VERSION "dbc-export 1 2025.20.8"

NS_ :

BS_:

BU_: ADSP APB APP APS APSB BB BMS CC CMP CMPD CP DAS DI DIF DIR DPB EPAS3P EPAS3S EPASTP EPASTS EPBL EPBR ESP EVSE FC GTW HCML HCMR HVP IBST ICR IDB LS OCS1P PARK PCS PM PMF PMR PNCD PTC RADC RCM RCM2 RCM3 RCU SCCM SCM SCS SDCR TAS TCU TPMS TRCM UI UIS UMC USM VC VCFRONT VCLEFT VCRIGHT VCSEC VEH

BO_ 896 PM_alertMatrix2: 8 PM
 SG_ PM_a066_pmfMIA : 1|1@1+ (1,0) [0|1] "" Vector__XXX
 SG_ PM_a067_pmrMIA : 2|1@1+ (1,0) [0|1] "" Vector__XXX
 SG_ PM_a068_brakePedalMonitor : 3|1@1+ (1,0) [0|1] "" Vector__XXX
 SG_ PM_a069_brakeMonitorsUnhealthy : 4|1@1+ (1,0) [0|1] "" Vector__XXX
 SG_ PM_a070_brakeTorqueSplitMonitorT : 5|1@1+ (1,0) [0|1] "" Vector__XXX
 SG_ PM_a071_baseBrakingMonitor : 6|1@1+ (1,0) [0|1] "" Vector__XXX
 SG_ PM_a072_brakeTorqueCommandInterf : 7|1@1+ (1,0) [0|1] "" Vector__XXX
 SG_ PM_a073_canDataBusC : 8|1@1+ (1,0) [0|1] "" Vector__XXX
 SG_ PM_a074_canHardwareBusC : 9|1@1+ (1,0) [0|1] "" Vector__XXX
 SG_ PM_a075_canDataBusD : 10|1@1+ (1,0) [0|1] "" Vector__XXX
 SG_ PM_a076_canHardwareBusD : 11|1@1+ (1,0) [0|1] "" Vector__XXX
 SG_ PM_a077_canDataBusE : 12|1@1+ (1,0) [0|1] "" Vector__XXX
 SG_ PM_a078_canHardwareBusE : 13|1@1+ (1,0) [0|1] "" Vector__XXX
 SG_ PM_a079_rcuMIA : 14|1@1+ (1,0) [0|1] "" Vector__XXX
 SG_ PM_a080_exceptionPrefetchAbort : 15|1@1+ (1,0) [0|1] "" Vector__XXX
 SG_ PM_a081_exceptionDataAbort : 16|1@1+ (1,0) [0|1] "" Vector__XXX
 SG_ PM_a082_exceptionDataAbort2 : 17|1@1+ (1,0) [0|1] "" Vector__XXX
 SG_ PM_a083_ahbWriteError : 18|1@1+ (1,0) [0|1] "" Vector__XXX
 SG_ PM_a084_exceptionMpuFirewall : 19|1@1+ (1,0) [0|1] "" Vector__XXX
 SG_ PM_a085_dpbMIA : 20|1@1+ (1,0) [0|1] "" Vector__XXX
 SG_ PM_a086_exceptionUndefinedInstru : 21|1@1+ (1,0) [0|1] "" Vector__XXX
 SG_ PM_a087_canHardwareBusLIPC : 22|1@1+ (1,0) [0|1] "" Vector__XXX
 SG_ PM_a092_xtalOscillator : 27|1@1+ (1,0) [0|1] "" Vector__XXX
 SG_ PM_a093_accelPedalSupply : 28|1@1+ (1,0) [0|1] "" Vector__XXX
 SG_ PM_a095_ITPMSTimeoutGNSSConverge : 30|1@1+ (1,0) [0|1] "" Vector__XXX
 SG_ PM_a096_ITPMSConvergedGNSSAbsRad : 31|1@1+ (1,0) [0|1] "" Vector__XXX
 SG_ PM_a098_ITPMSTriggerDebug : 33|1@1+ (1,0) [0|1] "" Vector__XXX
 SG_ PM_a099_ITPMSCalibrated : 34|1@1+ (1,0) [0|1] "" Vector__XXX
 SG_ PM_a100_diTraceInfo1 : 35|1@1+ (1,0) [0|1] "" Vector__XXX
 SG_ PM_a110_indirectTPMSSoftWarningF : 45|1@1+ (1,0) [0|1] "" Vector__XXX
 SG_ PM_a111_indirectTPMSSoftWarningF : 46|1@1+ (1,0) [0|1] "" Vector__XXX
 SG_ PM_a112_indirectTPMSSoftWarningR : 47|1@1+ (1,0) [0|1] "" Vector__XXX
 SG_ PM_a113_indirectTPMSSoftWarningR : 48|1@1+ (1,0) [0|1] "" Vector__XXX
 SG_ PM_a114_indirectTPMSHardWarningF : 49|1@1+ (1,0) [0|1] "" Vector__XXX
 SG_ PM_a115_indirectTPMSHardWarningF : 50|1@1+ (1,0) [0|1] "" Vector__XXX
 SG_ PM_a116_indirectTPMSHardWarningR : 51|1@1+ (1,0) [0|1] "" Vector__XXX
 SG_ PM_a117_indirectTPMSHardWarningR : 52|1@1+ (1,0) [0|1] "" Vector__XXX
 SG_ PM_a120_indirectTPMSFaulted : 55|1@1+ (1,0) [0|1] "" Vector__XXX
 SG_ PM_a121_unintendedReset2 : 56|1@1+ (1,0) [0|1] "" Vector__XXX

BO_ 2020 PM_info: 8 PM
 SG_ PM_infoIndex M : 0|8@1+ (1,0) [0|255] "" Vector__XXX
 SG_ PM_buildType m10 : 8|8@1+ (1,0) [0|255] "" Vector__XXX
 SG_ PM_buildConfigurationId m10 : 16|16@1+ (1,0) [0|65535] "" Vector__XXX
 SG_ PM_hardwareId m10 : 32|8@1+ (1,0) [0|252] "" Vector__XXX
 SG_ PM_deviceFused m10 : 40|1@1+ (1,0) [0|1] "" Vector__XXX
 SG_ PM_componentId m10 : 48|16@1+ (1,0) [0|65535] "" Vector__XXX
 SG_ PM_pcbaId m11 : 16|8@1+ (1,0) [0|255] "" Vector__XXX
 SG_ PM_assemblyId m11 : 24|8@1+ (1,0) [0|255] "" Vector__XXX
 SG_ PM_usageId m11 : 32|16@1+ (1,0) [0|65535] "" Vector__XXX
 SG_ PM_subUsageId m11 : 48|16@1+ (1,0) [0|65535] "" Vector__XXX
 SG_ PM_applicationCrc m13 : 32|32@1+ (1,0) [0|4294967295] "" Vector__XXX
 SG_ PM_bootGitHash m18 : 8|56@1+ (1,0) [0|7.20575940379e+16] "" Vector__XXX

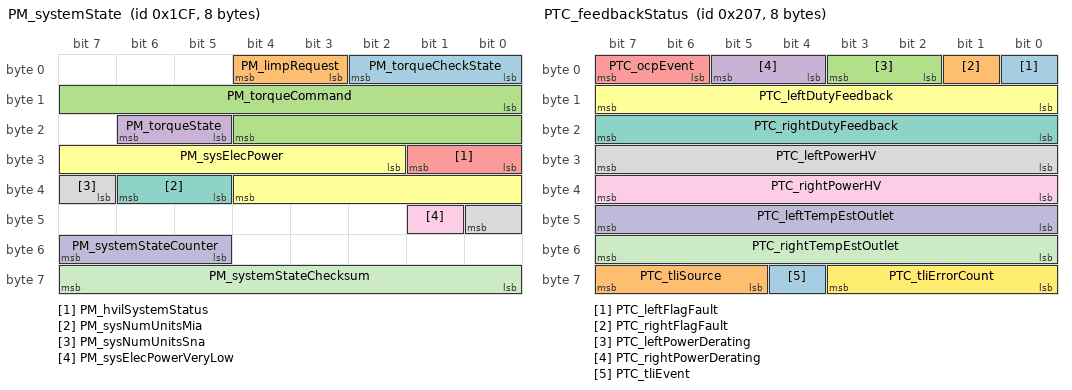
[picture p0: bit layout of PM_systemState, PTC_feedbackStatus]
BO_ 463 PM_systemState: 8 PM
 SG_ PM_torqueCheckState : 0|3@1+ (1,0) [0|7] "" Vector__XXX
 SG_ PM_limpRequest : 3|2@1+ (1,0) [0|3] "" Vector__XXX
 SG_ PM_torqueCommand : 8|13@1- (2,0) [-8192|8190] "Nm" Vector__XXX
 SG_ PM_torqueState : 21|2@1+ (1,0) [0|3] "" Vector__XXX
 SG_ PM_hvilSystemStatus : 24|2@1+ (1,0) [0|2] "" Vector__XXX
 SG_ PM_sysElecPower : 26|11@1- (1,250) [-774|1273] "kW" Vector__XXX
 SG_ PM_sysNumUnitsMia : 37|2@1+ (1,0) [0|3] "" Vector__XXX
 SG_ PM_sysNumUnitsSna : 39|2@1+ (1,0) [0|3] "" Vector__XXX
 SG_ PM_sysElecPowerVeryLow : 41|1@1+ (1,0) [0|1] "" Vector__XXX
 SG_ PM_systemStateCounter : 53|3@1+ (1,0) [0|7] "" Vector__XXX
 SG_ PM_systemStateChecksum : 56|8@1+ (1,0) [0|255] "" Vector__XXX

BO_ 2038 PM_vdcDebug: 8 PM
 SG_ PM_vdcDebugSelector M : 0|6@1+ (1,0) [0|63] "" Vector__XXX
 SG_ PM_VDCA_TCSlipTargetMod_RA_Fwd m5 : 8|6@1- (0.1,0) [-3|3] "m/s" Vector__XXX
 SG_ PM_VDCA_TCSlipTargetMod_RA_Rwd m5 : 16|6@1- (0.1,0) [-3|3] "m/s" Vector__XXX
 SG_ PM_VSE_forceY_RA m5 : 22|9@1- (40,240) [-10000|10440] "N" Vector__XXX
 SG_ PM_VDCT_observerSlipAngle_RA m5 : 31|9@1- (0.005,0.03) [-1.25|1.305] "rad" Vector__XXX
 SG_ PM_VSE_muVehicleFxLow m5 : 40|5@1+ (0.05,0) [0|1.55] "mu" Vector__XXX
 SG_ PM_VE_fxmFres m13 : 8|8@1- (200,0) [-20000|20000] "N" Vector__XXX
 SG_ PM_VE_fxAccelMass m13 : 16|8@1- (0.16,0) [-20|20] "m/s^2" Vector__XXX
 SG_ PM_VE_vxDotGrade m13 : 24|8@1- (0.1,0.8) [-12|13.5] "m/s^2" Vector__XXX
 SG_ PM_VE_betaEst m13 : 32|8@1- (0.01,0) [-1|1] "rad" Vector__XXX
 SG_ PM_VSE_muVehicleFxHigh m13 : 40|5@1+ (0.05,0) [0|1.55] "mu" Vector__XXX
 SG_ PM_VSE_muVehicleDecLeakRate m29 : 6|5@1+ (0.05,0) [0|1.55] "mu" Vector__XXX
 SG_ PM_VSE_muVehicleLearnDown m29 : 11|5@1+ (0.05,0) [0|1.55] "mu" Vector__XXX
 SG_ PM_VSE_muVehicleDecFilter m29 : 16|5@1+ (0.05,0) [0|1.55] "mu" Vector__XXX
 SG_ PM_VSE_muVehicleLatDecLeakRate m29 : 21|5@1+ (0.05,0) [0|1.55] "mu" Vector__XXX
 SG_ PM_VSE_splitMuProbability m29 : 26|5@1+ (0.05,0) [0|1.55] "probability" Vector__XXX
 SG_ PM_VSE_splitMuTotalMz m29 : 31|9@1- (60,360) [-15000|15660] "Nm" Vector__XXX
 SG_ PM_VSE_attitudeBankAngle m29 : 40|9@1- (0.005,0.03) [-1.25|1.305] "rad" Vector__XXX
 SG_ PM_VSE_attitudeDBetaInControl m29 : 49|8@1- (0.01,0.03) [-1.25|1.3] "rad" Vector__XXX
 SG_ PM_VSE_roadWheelAngleAverage m29 : 57|7@1- (0.015,0.255) [-0.7|1.2] "rad" Vector__XXX

BO_ 1766 PNCD_IsoTpPipeToCp: 8 PNCD
 SG_ PNCD_isoTpToCpData : 0|64@1+ (1,0) [0|1.84467440737e+19] "" Vector__XXX

BO_ 519 PTC_feedbackStatus: 8 PTC
 SG_ PTC_leftFlagFault : 0|1@1+ (1,0) [0|1] "" Vector__XXX
 SG_ PTC_rightFlagFault : 1|1@1+ (1,0) [0|1] "" Vector__XXX
 SG_ PTC_leftPowerDerating : 2|2@1+ (1,0) [0|3] "" Vector__XXX
 SG_ PTC_rightPowerDerating : 4|2@1+ (1,0) [0|3] "" Vector__XXX
 SG_ PTC_ocpEvent : 6|2@1+ (1,0) [0|3] "" Vector__XXX
 SG_ PTC_leftDutyFeedback : 8|8@1+ (0.5,0) [0|100] "%" Vector__XXX
 SG_ PTC_rightDutyFeedback : 16|8@1+ (0.5,0) [0|100] "%" Vector__XXX
 SG_ PTC_leftPowerHV : 24|8@1+ (30,0) [0|7650] "W" Vector__XXX
 SG_ PTC_rightPowerHV : 32|8@1+ (30,0) [0|7650] "W" Vector__XXX
 SG_ PTC_leftTempEstOutlet : 40|8@1+ (1,-40) [-40|200] "degC" Vector__XXX
 SG_ PTC_rightTempEstOutlet : 48|8@1+ (1,-40) [-40|200] "degC" Vector__XXX
 SG_ PTC_tliErrorCount : 56|4@1+ (1,0) [0|15] "" Vector__XXX
 SG_ PTC_tliEvent : 60|1@1+ (1,0) [0|1] "" Vector__XXX
 SG_ PTC_tliSource : 61|3@1+ (1,0) [0|7] "" Vector__XXX

BO_ 837 PTC_info: 8 PTC
 SG_ PTC_infoIndex M : 0|8@1+ (1,0) [0|255] "" Vector__XXX
 SG_ PTC_infoBuildType m10 : 8|3@1+ (1,0) [0|7] "" Vector__XXX
 SG_ PTC_infoBuildConfigId m10 : 16|16@1+ (1,0) [0|65535] "" Vector__XXX
 SG_ PTC_infoHardwareId m10 : 32|16@1+ (1,0) [0|65535] "" Vector__XXX
 SG_ PTC_infoComponentId m10 : 48|16@1+ (1,0) [0|65535] "" Vector__XXX
 SG_ PTC_infoPcbaId m11 : 16|8@1+ (1,0) [0|255] "" Vector__XXX
 SG_ PTC_infoAssemblyId m11 : 24|8@1+ (1,0) [0|254] "" Vector__XXX
 SG_ PTC_infoUsageId m11 : 32|16@1+ (1,0) [0|65535] "" Vector__XXX
 SG_ PTC_infoSubUsageId m11 : 48|16@1+ (1,0) [0|65535] "" Vector__XXX
 SG_ PTC_infoPlatformType m13 : 8|8@1+ (1,0) [0|255] "" Vector__XXX
 SG_ PTC_infoAppCrc m13 : 32|32@1+ (1,0) [0|4294967295] "" Vector__XXX
 SG_ PTC_infoBootUdsProtoVersion m20 : 8|8@1+ (1,0) [0|255] "" Vector__XXX
 SG_ PTC_infoBootCrc m20 : 32|32@1+ (1,0) [0|4294967295] "" Vector__XXX

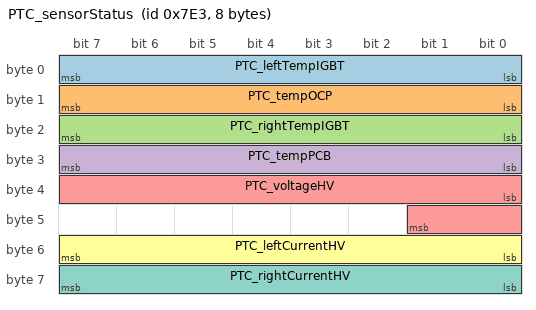
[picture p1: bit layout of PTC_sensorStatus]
BO_ 2019 PTC_sensorStatus: 8 PTC
 SG_ PTC_leftTempIGBT : 0|8@1+ (1,-40) [-40|200] "degC" Vector__XXX
 SG_ PTC_tempOCP : 8|8@1+ (1,-40) [-40|200] "degC" Vector__XXX
 SG_ PTC_rightTempIGBT : 16|8@1+ (1,-40) [-40|200] "degC" Vector__XXX
 SG_ PTC_tempPCB : 24|8@1+ (1,-40) [-40|200] "degC" Vector__XXX
 SG_ PTC_voltageHV : 32|10@1+ (0.5,0) [0|511.5] "V" Vector__XXX
 SG_ PTC_leftCurrentHV : 48|8@1+ (0.2,0) [0|50] "A" Vector__XXX
 SG_ PTC_rightCurrentHV : 56|8@1+ (0.2,0) [0|50] "A" Vector__XXX

BO_ 1365 RADC_alertLog: 8 RADC
 SG_ RADC_alertID M : 0|6@1+ (1,0) [0|63] "" Vector__XXX
 SG_ RADC_alertState : 15|1@1+ (1,0) [0|1] "" Vector__XXX
 SG_ RADC_a002_ecuAdcErrType m2 : 16|8@1+ (1,0) [0|255] "" Vector__XXX
 SG_ RADC_a008_interLockErrType m8 : 16|8@1+ (1,0) [0|255] "" Vector__XXX
 SG_ RADC_a011_ecuMcemErrType m11 : 16|8@1+ (1,0) [0|255] "" Vector__XXX
 SG_ RADC_a013_ecuWdgErrType m13 : 16|8@1+ (1,0) [0|255] "" Vector__XXX
 SG_ RADC_a016_adcOverVoltType m16 : 16|8@1+ (1,0) [0|255] "" Vector__XXX
 SG_ RADC_a016_adcVoltage m16 : 24|6@1+ (0.1,0) [0|6.3] "v" Vector__XXX
 SG_ RADC_a017_adcUnderVoltType m17 : 16|8@1+ (1,0) [0|255] "" Vector__XXX
 SG_ RADC_a017_adcVoltage m17 : 24|6@1+ (0.1,0) [0|6.3] "v" Vector__XXX
 SG_ RADC_a019_internalSWFaultType m19 : 16|8@1+ (1,0) [0|255] "" Vector__XXX
 SG_ RADC_a019_internalSWFaultCoreID m19 : 24|4@1+ (1,0) [0|15] "" Vector__XXX
 SG_ RADC_a020_ecuTemp m20 : 16|16@1+ (0.1,-44) [-44|6509.5] "deg" Vector__XXX
 SG_ RADC_a023_ecuTemp m23 : 16|16@1+ (0.1,-44) [-44|6509.5] "deg" Vector__XXX
 SG_ RADC_a025_ecuVoltage m25 : 16|8@1+ (0.1,0) [0|25.5] "v" Vector__XXX
 SG_ RADC_a026_ecuVoltage m26 : 16|8@1+ (0.1,0) [0|25.5] "v" Vector__XXX
 SG_ RADC_a027_nvmFailureType m27 : 16|8@1+ (1,0) [0|255] "" Vector__XXX
 SG_ RADC_a028_rfComRegCheckFail m28 : 16|8@1+ (1,0) [0|255] "" Vector__XXX
 SG_ RADC_a029_rhcChirpMonErrType m29 : 16|8@1+ (1,0) [0|255] "" Vector__XXX
 SG_ RADC_a029_rhcRxLongTermErrType m29 : 24|8@1+ (1,0) [0|255] "" Vector__XXX
 SG_ RADC_a029_rhcRxErrType m29 : 32|8@1+ (1,0) [0|255] "" Vector__XXX
 SG_ RADC_a029_rhcVcoPowerErrType m29 : 40|8@1+ (1,0) [0|255] "" Vector__XXX
 SG_ RADC_a029_rhcSp1ErrType m29 : 48|8@1+ (1,0) [0|255] "" Vector__XXX
 SG_ RADC_a029_rhcFdcErrType m29 : 56|8@1+ (1,0) [0|255] "" Vector__XXX
 SG_ RADC_a030_rspErrType m30 : 16|8@1+ (1,0) [0|255] "" Vector__XXX
 SG_ RADC_a031_horizMisalignAngle m31 : 16|8@1+ (0.001953125,-0.25) [-0.25|0.248046875] "rad" Vector__XXX
 SG_ RADC_a031_vertMisalignAngle m31 : 24|12@1+ (0.0001220703125,-0.25) [-0.25|0.249877929688] "rad" Vector__XXX
 SG_ RADC_a032_blockageType m32 : 16|8@1+ (1,0) [0|255] "" Vector__XXX
 SG_ RADC_a032_block_SPMBlockageState m32 : 24|3@1+ (1,0) [0|7] "" Vector__XXX
 SG_ RADC_a032_block_dummy m32 : 27|3@1+ (1,0) [0|7] "" Vector__XXX
 SG_ RADC_a032_block_SPMSelfTestState m32 : 30|2@1+ (1,0) [0|3] "" Vector__XXX
 SG_ RADC_a032_block_ucEstiRange m32 : 32|8@1+ (1,0) [0|255] "m" Vector__XXX
 SG_ RADC_a032_block_ucEstiRangeConf m32 : 40|8@1+ (1,0) [0|255] "" Vector__XXX
 SG_ RADC_a032_block_ucEstiRangeProb m32 : 48|8@1+ (1,0) [0|255] "" Vector__XXX
 SG_ RADC_a032_block_ucTimeoutBlkConf m32 : 56|8@1+ (1,0) [0|255] "" Vector__XXX
 SG_ RADC_a035_msgId m35 : 16|12@1+ (1,0) [0|4095] "" Vector__XXX
 SG_ RADC_a036_msgId m36 : 16|12@1+ (1,0) [0|4095] "" Vector__XXX
 SG_ RADC_a037_msgId m37 : 16|12@1+ (1,0) [0|4095] "" Vector__XXX
 SG_ RADC_a038_msgId m38 : 16|12@1+ (1,0) [0|4095] "" Vector__XXX
 SG_ RADC_a039_msgId m39 : 16|12@1+ (1,0) [0|4095] "" Vector__XXX
 SG_ RADC_a040_msgId m40 : 16|12@1+ (1,0) [0|4095] "" Vector__XXX
 SG_ RADC_a041_vinErrType m41 : 16|4@1+ (1,0) [0|15] "" Vector__XXX
 SG_ RADC_a041_vinErrExp m41 : 20|16@1+ (1,0) [0|65535] "" Vector__XXX
 SG_ RADC_a041_vinErrRx m41 : 36|16@1+ (1,0) [0|65535] "" Vector__XXX
 SG_ RADC_a041_msgId m41 : 52|12@1+ (1,0) [0|4095] "" Vector__XXX
 SG_ RADC_a042_carConfigErrType m42 : 16|4@1+ (1,0) [0|15] "" Vector__XXX
 SG_ RADC_a042_carConfigErrExp m42 : 20|16@1+ (1,0) [0|65535] "" Vector__XXX
 SG_ RADC_a042_carConfigErrRx m42 : 36|16@1+ (1,0) [0|65535] "" Vector__XXX
 SG_ RADC_a042_msgId m42 : 52|12@1+ (1,0) [0|4095] "" Vector__XXX
 SG_ RADC_a043_inertialSignalsErrType m43 : 16|4@1+ (1,0) [0|15] "" Vector__XXX
 SG_ RADC_a043_inertialSignalsErrExp m43 : 20|16@1+ (1,0) [0|65535] "" Vector__XXX
 SG_ RADC_a043_inertialSignalsErrRx m43 : 36|16@1+ (1,0) [0|65535] "" Vector__XXX
 SG_ RADC_a043_msgId m43 : 52|12@1+ (1,0) [0|4095] "" Vector__XXX
 SG_ RADC_a044_stwAngleErrType m44 : 16|4@1+ (1,0) [0|15] "" Vector__XXX
 SG_ RADC_a044_stwAngleErrExp m44 : 20|16@1+ (1,0) [0|65535] "" Vector__XXX
 SG_ RADC_a044_stwAngleErrRx m44 : 36|16@1+ (1,0) [0|65535] "" Vector__XXX
 SG_ RADC_a044_msgId m44 : 52|12@1+ (1,0) [0|4095] "" Vector__XXX
 SG_ RADC_a045_vehicleStateErrType m45 : 16|4@1+ (1,0) [0|15] "" Vector__XXX
 SG_ RADC_a045_vehicleStateErrExp m45 : 20|16@1+ (1,0) [0|65535] "" Vector__XXX
 SG_ RADC_a045_vehicleStateErrRx m45 : 36|16@1+ (1,0) [0|65535] "" Vector__XXX
 SG_ RADC_a045_msgId m45 : 52|12@1+ (1,0) [0|4095] "" Vector__XXX
 SG_ RADC_a046_wheelSpeedsErrType m46 : 16|4@1+ (1,0) [0|15] "" Vector__XXX
 SG_ RADC_a046_wheelSpeedsErrExp m46 : 20|16@1+ (1,0) [0|65535] "" Vector__XXX
 SG_ RADC_a046_wheelSpeedsErrRx m46 : 36|16@1+ (1,0) [0|65535] "" Vector__XXX
 SG_ RADC_a046_msgId m46 : 52|12@1+ (1,0) [0|4095] "" Vector__XXX
 SG_ RADC_a047_chassisTypeExp m47 : 16|8@1+ (1,0) [0|255] "" Vector__XXX
 SG_ RADC_a047_chassisTypeRx m47 : 24|8@1+ (1,0) [0|255] "" Vector__XXX
 SG_ RADC_a048_airSuspensionExp m48 : 16|8@1+ (1,0) [0|255] "" Vector__XXX
 SG_ RADC_a048_airSuspensionRx m48 : 24|8@1+ (1,0) [0|255] "" Vector__XXX
 SG_ RADC_a049_fourWheelDriveExp m49 : 16|8@1+ (1,0) [0|255] "" Vector__XXX
 SG_ RADC_a049_fourWheelDriveRx m49 : 24|8@1+ (1,0) [0|255] "" Vector__XXX
 SG_ RADC_a050_countryExp m50 : 16|16@1+ (1,0) [0|65535] "" Vector__XXX
 SG_ RADC_a050_countryRx m50 : 32|16@1+ (1,0) [0|65535] "" Vector__XXX
 SG_ RADC_a051_epasTypeExp m51 : 16|8@1+ (1,0) [0|255] "" Vector__XXX
 SG_ RADC_a051_epasTypeRx m51 : 24|8@1+ (1,0) [0|255] "" Vector__XXX
 SG_ RADC_a052_radarPositionExp m52 : 16|8@1+ (1,0) [0|255] "" Vector__XXX
 SG_ RADC_a052_radarPositionRx m52 : 24|8@1+ (1,0) [0|255] "" Vector__XXX
 SG_ RADC_a054_block_ucObjLossProb m54 : 16|8@1+ (1,0) [0|255] "" Vector__XXX
 SG_ RADC_a054_block_ucObjLossConf m54 : 24|8@1+ (1,0) [0|255] "" Vector__XXX
 SG_ RADC_a054_block_ucOverallProb m54 : 32|8@1+ (1,0) [0|255] "" Vector__XXX
 SG_ RADC_a054_block_ucOverallConf m54 : 40|8@1+ (1,0) [0|255] "" Vector__XXX
 SG_ RADC_a054_block_RoadbeamTimeCnt m54 : 48|16@1+ (1,0) [0|65535] "s" Vector__XXX
 SG_ RADC_a055_block_usTimeoutWayCnt m55 : 16|16@1+ (1,0) [0|65535] "m" Vector__XXX
 SG_ RADC_a055_block_ucTimeoutTimeCnt m55 : 32|8@1+ (1,0) [0|255] "s" Vector__XXX
 SG_ RADC_a055_bblock_ucTimeoutBlkPro m55 : 40|8@1+ (1,0) [0|255] "" Vector__XXX
 SG_ RADC_a055_block_usFullBlkTimer m55 : 48|16@1+ (1,0) [0|65535] "s" Vector__XXX

BO_ 1282 RADC_alertMatrix0: 8 RADC
 SG_ RADC_a001_can1BusOff : 1|1@1+ (1,0) [0|1] "" Vector__XXX
 SG_ RADC_a002_ecuAdcError : 2|1@1+ (1,0) [0|1] "" Vector__XXX
 SG_ RADC_a003_ecuBistDisabled : 3|1@1+ (1,0) [0|1] "" Vector__XXX
 SG_ RADC_a004_ecuCrcHwError : 4|1@1+ (1,0) [0|1] "" Vector__XXX
 SG_ RADC_a005_ecuEcuMError : 5|1@1+ (1,0) [0|1] "" Vector__XXX
 SG_ RADC_a006_ecuFimError : 6|1@1+ (1,0) [0|1] "" Vector__XXX
 SG_ RADC_a007_ecuGptCheckError : 7|1@1+ (1,0) [0|1] "" Vector__XXX
 SG_ RADC_a008_ecuHwSwInterlock : 8|1@1+ (1,0) [0|1] "" Vector__XXX
 SG_ RADC_a009_plantModeActive : 9|1@1+ (1,0) [0|1] "" Vector__XXX
 SG_ RADC_a010_ecuIoHwAbError : 10|1@1+ (1,0) [0|1] "" Vector__XXX
 SG_ RADC_a011_ecuMcemError : 11|1@1+ (1,0) [0|1] "" Vector__XXX
 SG_ RADC_a012_ecuSpiError : 12|1@1+ (1,0) [0|1] "" Vector__XXX
 SG_ RADC_a013_ecuWdgError : 13|1@1+ (1,0) [0|1] "" Vector__XXX
 SG_ RADC_a014_fctSelfTestNotDone : 14|1@1+ (1,0) [0|1] "" Vector__XXX
 SG_ RADC_a015_fctSenInterference : 15|1@1+ (1,0) [0|1] "" Vector__XXX
 SG_ RADC_a016_adcOverVolt : 16|1@1+ (1,0) [0|1] "" Vector__XXX
 SG_ RADC_a017_adcUnderVolt : 17|1@1+ (1,0) [0|1] "" Vector__XXX
 SG_ RADC_a018_internalHardwareFault : 18|1@1+ (1,0) [0|1] "" Vector__XXX
 SG_ RADC_a019_internalSoftwareFault : 19|1@1+ (1,0) [0|1] "" Vector__XXX
 SG_ RADC_a020_overTemp : 20|1@1+ (1,0) [0|1] "" Vector__XXX
 SG_ RADC_a021_overTempCrit : 21|1@1+ (1,0) [0|1] "" Vector__XXX
 SG_ RADC_a022_tempImplausible : 22|1@1+ (1,0) [0|1] "" Vector__XXX
 SG_ RADC_a023_underTemp : 23|1@1+ (1,0) [0|1] "" Vector__XXX
 SG_ RADC_a024_underTempCrit : 24|1@1+ (1,0) [0|1] "" Vector__XXX
 SG_ RADC_a025_overVoltage : 25|1@1+ (1,0) [0|1] "" Vector__XXX
 SG_ RADC_a026_underVoltage : 26|1@1+ (1,0) [0|1] "" Vector__XXX
 SG_ RADC_a027_nvmFailure : 27|1@1+ (1,0) [0|1] "" Vector__XXX
 SG_ RADC_a028_rfChipError : 28|1@1+ (1,0) [0|1] "" Vector__XXX
 SG_ RADC_a029_rhcError : 29|1@1+ (1,0) [0|1] "" Vector__XXX
 SG_ RADC_a030_rspError : 30|1@1+ (1,0) [0|1] "" Vector__XXX
 SG_ RADC_a031_sensorMisaligned : 31|1@1+ (1,0) [0|1] "" Vector__XXX
 SG_ RADC_a032_sensorBlocked : 32|1@1+ (1,0) [0|1] "" Vector__XXX
 SG_ RADC_a033_sensorNeverAligned : 33|1@1+ (1,0) [0|1] "" Vector__XXX
 SG_ RADC_a034_vehDynamicsError : 34|1@1+ (1,0) [0|1] "" Vector__XXX
 SG_ RADC_a035_vinMIA : 35|1@1+ (1,0) [0|1] "" Vector__XXX
 SG_ RADC_a036_carConfigMIA : 36|1@1+ (1,0) [0|1] "" Vector__XXX
 SG_ RADC_a037_inertialSignalsMIA : 37|1@1+ (1,0) [0|1] "" Vector__XXX
 SG_ RADC_a038_steeringWheelAngleMIA : 38|1@1+ (1,0) [0|1] "" Vector__XXX
 SG_ RADC_a039_vehicleStateMIA : 39|1@1+ (1,0) [0|1] "" Vector__XXX
 SG_ RADC_a040_wheelSpeedsMIA : 40|1@1+ (1,0) [0|1] "" Vector__XXX
 SG_ RADC_a041_vinErr : 41|1@1+ (1,0) [0|1] "" Vector__XXX
 SG_ RADC_a042_carConfigErr : 42|1@1+ (1,0) [0|1] "" Vector__XXX
 SG_ RADC_a043_inertialSignalsErr : 43|1@1+ (1,0) [0|1] "" Vector__XXX
 SG_ RADC_a044_steeringWheelAngleErr : 44|1@1+ (1,0) [0|1] "" Vector__XXX
 SG_ RADC_a045_vehicleStateErr : 45|1@1+ (1,0) [0|1] "" Vector__XXX
 SG_ RADC_a046_wheelSpeedsErr : 46|1@1+ (1,0) [0|1] "" Vector__XXX
 SG_ RADC_a047_mismatchChassisType : 47|1@1+ (1,0) [0|1] "" Vector__XXX
 SG_ RADC_a048_mismatchAirSuspension : 48|1@1+ (1,0) [0|1] "" Vector__XXX
 SG_ RADC_a049_mismatchFourWheelDrive : 49|1@1+ (1,0) [0|1] "" Vector__XXX
 SG_ RADC_a050_mismatchCountry : 50|1@1+ (1,0) [0|1] "" Vector__XXX
 SG_ RADC_a051_mismatchEPASType : 51|1@1+ (1,0) [0|1] "" Vector__XXX
 SG_ RADC_a052_mismatcRadPos : 52|1@1+ (1,0) [0|1] "" Vector__XXX
 SG_ RADC_a053_emError : 53|1@1+ (1,0) [0|1] "" Vector__XXX
 SG_ RADC_a054_blockageInfo_Frame_1 : 54|1@1+ (1,0) [0|1] "" Vector__XXX
 SG_ RADC_a055_blockageInfo_Frame_2 : 55|1@1+ (1,0) [0|1] "" Vector__XXX

BO_ 1329 RADC_info: 8 RADC
 SG_ RADC_infoIndex M : 0|8@1+ (1,0) [0|255] "" Vector__XXX
 SG_ RADC_infoBuildType m10 : 8|8@1+ (1,0) [0|255] "" Vector__XXX
 SG_ RADC_infoBuildConfigID m10 : 16|16@1+ (1,0) [0|65535] "" Vector__XXX
 SG_ RADC_infoHardwareID m10 : 32|16@1+ (1,0) [0|65535] "" Vector__XXX
 SG_ RADC_infoComponentID m10 : 48|16@1+ (1,0) [0|65535] "" Vector__XXX
 SG_ RADC_infoPcbaID m11 : 16|8@1+ (1,0) [0|255] "" Vector__XXX
 SG_ RADC_infoAssemblyID m11 : 24|8@1+ (1,0) [0|255] "" Vector__XXX
 SG_ RADC_infoUsageID m11 : 32|16@1+ (1,0) [0|65535] "" Vector__XXX
 SG_ RADC_infoSubUsageID m11 : 48|16@1+ (1,0) [0|65535] "" Vector__XXX
 SG_ RADC_infoApplicationCRC m13 : 32|32@1+ (1,0) [0|4294967295] "" Vector__XXX
 SG_ RADC_infoPlatformType m19 : 8|8@1+ (1,0) [0|255] "" Vector__XXX
 SG_ RADC_infoMajorVersion m19 : 16|8@1+ (1,0) [0|255] "" Vector__XXX
 SG_ RADC_infoBranchOrigin m19 : 24|8@1+ (1,0) [0|255] "" Vector__XXX
 SG_ RADC_infoMaturity m19 : 32|8@1+ (1,0) [0|255] "" Vector__XXX
 SG_ RADC_infoHardwareRevision m19 : 40|8@1+ (1,0) [0|255] "" Vector__XXX
 SG_ RADC_infoBootUdsProtoVersion m20 : 8|8@1+ (1,0) [0|255] "" Vector__XXX
 SG_ RADC_infoBootloaderCRC m20 : 32|32@1+ (1,0) [0|4294967295] "" Vector__XXX

BO_ 1249 RCM2_alertLog: 8 RCM2
 SG_ RCM2_alertID M : 0|10@1+ (1,0) [0|1023] "" Vector__XXX
 SG_ RCM2_alertState : 15|1@1+ (1,0) [0|1] "" Vector__XXX
 SG_ RCM2_eventArmStatus : 25|1@1+ (1,0) [0|1] "" Vector__XXX
 SG_ RCM2_eventFactoryMode : 26|1@1+ (1,0) [0|1] "" Vector__XXX
 SG_ RCM2_eventDriveOrientation : 28|1@1+ (1,0) [0|1] "" Vector__XXX
 SG_ RCM2_eventIDFsignal : 29|1@1+ (1,0) [0|1] "" Vector__XXX
 SG_ RCM2_eventFrontLeftSeatbelt : 30|1@1+ (1,0) [0|1] "" Vector__XXX
 SG_ RCM2_eventFrontRightSeatbelt : 31|1@1+ (1,0) [0|1] "" Vector__XXX
 SG_ RCM2_eventVehicleSpeed : 32|12@1+ (0.08,-40) [-40|287.6] "kph" Vector__XXX
 SG_ RCM2_eventDriverBrakeApply : 44|2@1+ (1,0) [0|2] "" Vector__XXX
 SG_ RCM2_eventAccelPedalPos : 56|8@1+ (0.4,0) [0|101.6] "%" Vector__XXX
 SG_ RCM2_a000_crashDetectedStaticRol m0 : 13|1@1+ (1,0) [0|1] "" Vector__XXX
 SG_ RCM2_a000_crashDetectedPitch m0 : 14|1@1+ (1,0) [0|1] "" Vector__XXX
 SG_ RCM2_a000_crashDetectedFront m0 : 16|1@1+ (1,0) [0|1] "" Vector__XXX
 SG_ RCM2_a000_crashDetectedRear m0 : 17|1@1+ (1,0) [0|1] "" Vector__XXX
 SG_ RCM2_a000_crashDetectedLeft m0 : 18|1@1+ (1,0) [0|1] "" Vector__XXX
 SG_ RCM2_a000_crashDetectedRight m0 : 19|1@1+ (1,0) [0|1] "" Vector__XXX
 SG_ RCM2_a000_crashDetectedRoll m0 : 20|1@1+ (1,0) [0|1] "" Vector__XXX
 SG_ RCM2_a000_crashDetectedPreten m0 : 21|1@1+ (1,0) [0|1] "" Vector__XXX
 SG_ RCM2_a000_crashDetectedStage1 m0 : 22|1@1+ (1,0) [0|1] "" Vector__XXX
 SG_ RCM2_a000_crashDetectedStage2 m0 : 23|1@1+ (1,0) [0|1] "" Vector__XXX
 SG_ RCM2_a000_crashDetectedHVpyro m0 : 24|1@1+ (1,0) [0|1] "" Vector__XXX
 SG_ RCM2_a000_crashDetectedOffZone m0 : 27|1@1+ (1,0) [0|1] "" Vector__XXX
 SG_ RCM2_a001_nearDeployFront m1 : 16|1@1+ (1,0) [0|1] "" Vector__XXX
 SG_ RCM2_a001_nearDeployRear m1 : 17|1@1+ (1,0) [0|1] "" Vector__XXX
 SG_ RCM2_a001_nearDeployLeft m1 : 18|1@1+ (1,0) [0|1] "" Vector__XXX
 SG_ RCM2_a001_nearDeployRight m1 : 19|1@1+ (1,0) [0|1] "" Vector__XXX
 SG_ RCM2_a001_nearDeployRoll m1 : 20|1@1+ (1,0) [0|1] "" Vector__XXX
 SG_ RCM2_a002_airbagsUnArmed_s m2 : 16|1@1+ (1,0) [0|1] "" Vector__XXX
 SG_ RCM2_a003_warningIndicator_s m3 : 16|1@1+ (1,0) [0|1] "" Vector__XXX
 SG_ RCM2_a004_crashAlgoWakeup_s m4 : 16|1@1+ (1,0) [0|1] "" Vector__XXX
 SG_ RCM2_a004_crashAlgoWakeupFront m4 : 17|1@1+ (1,0) [0|1] "" Vector__XXX
 SG_ RCM2_a004_crashAlgoWakeupSide m4 : 18|1@1+ (1,0) [0|1] "" Vector__XXX
 SG_ RCM2_a004_crashAlgoWakeupRear m4 : 19|1@1+ (1,0) [0|1] "" Vector__XXX
 SG_ RCM2_a004_crashAlgoWakeupRoll m4 : 20|1@1+ (1,0) [0|1] "" Vector__XXX
 SG_ RCM2_a004_crashAlgoWakeupPedPro m4 : 21|1@1+ (1,0) [0|1] "" Vector__XXX
 SG_ RCM2_a004_crashAlgoWakeupOffZone m4 : 22|1@1+ (1,0) [0|1] "" Vector__XXX
 SG_ RCM2_a005_abuseImmunityThrshold_ m5 : 16|1@1+ (1,0) [0|1] "" Vector__XXX
 SG_ RCM2_a007_pedProCrashDetected_s m7 : 16|1@1+ (1,0) [0|1] "" Vector__XXX
 SG_ RCM2_a008_factoryMode_s m8 : 16|1@1+ (1,0) [0|1] "" Vector__XXX
 SG_ RCM2_a009_edrDataAreaLocked_s m9 : 16|1@1+ (1,0) [0|1] "" Vector__XXX
 SG_ RCM2_a010_pedProEDRDataLocked_s m10 : 16|1@1+ (1,0) [0|1] "" Vector__XXX
 SG_ RCM2_a014_pedProNearDeploy_s m14 : 16|1@1+ (1,0) [0|1] "" Vector__XXX
 SG_ RCM2_a015_noDeployCrashCal_s m15 : 16|1@1+ (1,0) [0|1] "" Vector__XXX
 SG_ RCM2_a016_noDeployPedProCal_s m16 : 16|1@1+ (1,0) [0|1] "" Vector__XXX
 SG_ RCM2_a047_batteryESRhigh_s m47 : 16|1@1+ (1,0) [0|1] "" Vector__XXX
 SG_ RCM2_a048_batteryVoltageTooHigh_ m48 : 16|1@1+ (1,0) [0|1] "" Vector__XXX
 SG_ RCM2_a049_batteryVoltageTooLow_s m49 : 16|1@1+ (1,0) [0|1] "" Vector__XXX
 SG_ RCM2_a050_driverABStg1Sht2Gnd_s m50 : 16|1@1+ (1,0) [0|1] "" Vector__XXX
 SG_ RCM2_a051_driverABStg1Sht2Bat_s m51 : 16|1@1+ (1,0) [0|1] "" Vector__XXX
 SG_ RCM2_a052_driverABStg1Open_s m52 : 16|1@1+ (1,0) [0|1] "" Vector__XXX
 SG_ RCM2_a053_driverABStg1Short_s m53 : 16|1@1+ (1,0) [0|1] "" Vector__XXX
 SG_ RCM2_a054_driverABStg1CrssCoup_s m54 : 16|1@1+ (1,0) [0|1] "" Vector__XXX
 SG_ RCM2_a055_driverABStg1Config_s m55 : 16|1@1+ (1,0) [0|1] "" Vector__XXX
 SG_ RCM2_a056_driverABStg2Sht2Gnd_s m56 : 16|1@1+ (1,0) [0|1] "" Vector__XXX
 SG_ RCM2_a057_driverABStg2Sht2Bat_s m57 : 16|1@1+ (1,0) [0|1] "" Vector__XXX
 SG_ RCM2_a058_driverABStg2Open_s m58 : 16|1@1+ (1,0) [0|1] "" Vector__XXX
 SG_ RCM2_a059_driverABStg2Short_s m59 : 16|1@1+ (1,0) [0|1] "" Vector__XXX
 SG_ RCM2_a060_driverABStg2CrssCoup_s m60 : 16|1@1+ (1,0) [0|1] "" Vector__XXX
 SG_ RCM2_a061_driverABStg2Config_s m61 : 16|1@1+ (1,0) [0|1] "" Vector__XXX
 SG_ RCM2_a062_passABStg1Sht2Gnd_s m62 : 16|1@1+ (1,0) [0|1] "" Vector__XXX
 SG_ RCM2_a063_passABStg1Sht2Bat_s m63 : 16|1@1+ (1,0) [0|1] "" Vector__XXX
 SG_ RCM2_a064_passABStg1Open_s m64 : 16|1@1+ (1,0) [0|1] "" Vector__XXX
 SG_ RCM2_a065_passABStg1Short_s m65 : 16|1@1+ (1,0) [0|1] "" Vector__XXX
 SG_ RCM2_a066_passABStg1CrssCoup_s m66 : 16|1@1+ (1,0) [0|1] "" Vector__XXX
 SG_ RCM2_a067_passABStg1Config_s m67 : 16|1@1+ (1,0) [0|1] "" Vector__XXX
 SG_ RCM2_a068_passABStg2Sht2Gnd_s m68 : 16|1@1+ (1,0) [0|1] "" Vector__XXX
 SG_ RCM2_a069_passABStg2Sht2Bat_s m69 : 16|1@1+ (1,0) [0|1] "" Vector__XXX
 SG_ RCM2_a070_passABStg2Open_s m70 : 16|1@1+ (1,0) [0|1] "" Vector__XXX
 SG_ RCM2_a071_passABStg2Short_s m71 : 16|1@1+ (1,0) [0|1] "" Vector__XXX
 SG_ RCM2_a072_passABStg2CrssCoup_s m72 : 16|1@1+ (1,0) [0|1] "" Vector__XXX
 SG_ RCM2_a073_passABStg2Config_s m73 : 16|1@1+ (1,0) [0|1] "" Vector__XXX
 SG_ RCM2_a074_passActiveVentSht2Gnd_ m74 : 16|1@1+ (1,0) [0|1] "" Vector__XXX
 SG_ RCM2_a075_passActiveVentSht2Bat_ m75 : 16|1@1+ (1,0) [0|1] "" Vector__XXX
 SG_ RCM2_a076_passActiveVentOpen_s m76 : 16|1@1+ (1,0) [0|1] "" Vector__XXX
 SG_ RCM2_a077_passActiveVentShort_s m77 : 16|1@1+ (1,0) [0|1] "" Vector__XXX
 SG_ RCM2_a078_passActiveVentCrssCoup m78 : 16|1@1+ (1,0) [0|1] "" Vector__XXX
 SG_ RCM2_a079_passActiveVentConfig_s m79 : 16|1@1+ (1,0) [0|1] "" Vector__XXX
 SG_ RCM2_a080_pretenShldLeftSht2Gnd_ m80 : 16|1@1+ (1,0) [0|1] "" Vector__XXX
 SG_ RCM2_a081_pretenShldLeftSht2Bat_ m81 : 16|1@1+ (1,0) [0|1] "" Vector__XXX
 SG_ RCM2_a082_pretenShldLeftOpen_s m82 : 16|1@1+ (1,0) [0|1] "" Vector__XXX
 SG_ RCM2_a083_pretenShldLeftShort_s m83 : 16|1@1+ (1,0) [0|1] "" Vector__XXX
 SG_ RCM2_a084_pretenShldLeftCrossC_s m84 : 16|1@1+ (1,0) [0|1] "" Vector__XXX
 SG_ RCM2_a085_pretenShldLeftConfig_s m85 : 16|1@1+ (1,0) [0|1] "" Vector__XXX
 SG_ RCM2_a086_pretenShldRightSht2Gnd m86 : 16|1@1+ (1,0) [0|1] "" Vector__XXX
 SG_ RCM2_a087_pretenShldRightSht2Bat m87 : 16|1@1+ (1,0) [0|1] "" Vector__XXX
 SG_ RCM2_a088_pretenShldRightOpen_s m88 : 16|1@1+ (1,0) [0|1] "" Vector__XXX
 SG_ RCM2_a089_pretenShldRightShort_s m89 : 16|1@1+ (1,0) [0|1] "" Vector__XXX
 SG_ RCM2_a090_pretenShldRightCrssCou m90 : 16|1@1+ (1,0) [0|1] "" Vector__XXX
 SG_ RCM2_a091_pretenShldRightConfig_ m91 : 16|1@1+ (1,0) [0|1] "" Vector__XXX
 SG_ RCM2_a092_pretenLapLeftSht2Gnd_s m92 : 16|1@1+ (1,0) [0|1] "" Vector__XXX
 SG_ RCM2_a093_pretenLapLeftSht2Bat_s m93 : 16|1@1+ (1,0) [0|1] "" Vector__XXX
 SG_ RCM2_a094_pretenLapLeftOpen_s m94 : 16|1@1+ (1,0) [0|1] "" Vector__XXX
 SG_ RCM2_a095_pretenLapLeftShort_s m95 : 16|1@1+ (1,0) [0|1] "" Vector__XXX
 SG_ RCM2_a096_pretenLapLeftCrssCoup_ m96 : 16|1@1+ (1,0) [0|1] "" Vector__XXX
 SG_ RCM2_a097_pretenLapLeftConfig_s m97 : 16|1@1+ (1,0) [0|1] "" Vector__XXX
 SG_ RCM2_a098_pretenLapRightSht2Gnd_ m98 : 16|1@1+ (1,0) [0|1] "" Vector__XXX
 SG_ RCM2_a099_pretenLapRightSht2Bat_ m99 : 16|1@1+ (1,0) [0|1] "" Vector__XXX
 SG_ RCM2_a100_pretenLapRightOpen_s m100 : 16|1@1+ (1,0) [0|1] "" Vector__XXX
 SG_ RCM2_a101_pretenLapRightShort_s m101 : 16|1@1+ (1,0) [0|1] "" Vector__XXX
 SG_ RCM2_a102_pretenLapRightCrssCoup m102 : 16|1@1+ (1,0) [0|1] "" Vector__XXX
 SG_ RCM2_a103_pretenLapRightConfig_s m103 : 16|1@1+ (1,0) [0|1] "" Vector__XXX
 SG_ RCM2_a104_loadLimLeftSht2Gnd_s m104 : 16|1@1+ (1,0) [0|1] "" Vector__XXX
 SG_ RCM2_a105_loadLimLeftSht2Bat_s m105 : 16|1@1+ (1,0) [0|1] "" Vector__XXX
 SG_ RCM2_a106_loadLimLeftOpen_s m106 : 16|1@1+ (1,0) [0|1] "" Vector__XXX
 SG_ RCM2_a107_loadLimLeftShort_s m107 : 16|1@1+ (1,0) [0|1] "" Vector__XXX
 SG_ RCM2_a108_loadLimLeftCrssCoup_s m108 : 16|1@1+ (1,0) [0|1] "" Vector__XXX
 SG_ RCM2_a110_loadLimRightSht2Gnd_s m110 : 16|1@1+ (1,0) [0|1] "" Vector__XXX
 SG_ RCM2_a111_loadLimRightSht2Bat_s m111 : 16|1@1+ (1,0) [0|1] "" Vector__XXX
 SG_ RCM2_a112_loadLimRightOpen_s m112 : 16|1@1+ (1,0) [0|1] "" Vector__XXX
 SG_ RCM2_a113_loadLimRightShort_s m113 : 16|1@1+ (1,0) [0|1] "" Vector__XXX
 SG_ RCM2_a114_loadLimRightCrssCoup_s m114 : 16|1@1+ (1,0) [0|1] "" Vector__XXX
 SG_ RCM2_a115_loadLimRightConfig_s m115 : 16|1@1+ (1,0) [0|1] "" Vector__XXX
 SG_ RCM2_a116_kneeABDrvrSht2Gnd_s m116 : 16|1@1+ (1,0) [0|1] "" Vector__XXX
 SG_ RCM2_a117_kneeABDrvrSht2Bat_s m117 : 16|1@1+ (1,0) [0|1] "" Vector__XXX
 SG_ RCM2_a118_kneeABDrvrOpen_s m118 : 16|1@1+ (1,0) [0|1] "" Vector__XXX
 SG_ RCM2_a119_kneeABDrvrShort_s m119 : 16|1@1+ (1,0) [0|1] "" Vector__XXX
 SG_ RCM2_a120_kneeABDrvrCrssCoup_s m120 : 16|1@1+ (1,0) [0|1] "" Vector__XXX
 SG_ RCM2_a122_kneeABPassSht2Gnd_s m122 : 16|1@1+ (1,0) [0|1] "" Vector__XXX
 SG_ RCM2_a123_kneeABPassSht2Bat_s m123 : 16|1@1+ (1,0) [0|1] "" Vector__XXX
 SG_ RCM2_a124_kneeABPassOpen_s m124 : 16|1@1+ (1,0) [0|1] "" Vector__XXX
 SG_ RCM2_a125_kneeABPassShort_s m125 : 16|1@1+ (1,0) [0|1] "" Vector__XXX
 SG_ RCM2_a126_kneeABPassCrssCoup_s m126 : 16|1@1+ (1,0) [0|1] "" Vector__XXX
 SG_ RCM2_a127_kneeABPassConfig_s m127 : 16|1@1+ (1,0) [0|1] "" Vector__XXX
 SG_ RCM2_a128_sideAB1stRowLSht2Gnd_s m128 : 16|1@1+ (1,0) [0|1] "" Vector__XXX
 SG_ RCM2_a129_sideAB1stRowLSht2Bat_s m129 : 16|1@1+ (1,0) [0|1] "" Vector__XXX
 SG_ RCM2_a130_sideAB1stRowLOpen_s m130 : 16|1@1+ (1,0) [0|1] "" Vector__XXX
 SG_ RCM2_a131_sideAB1stRowLShort_s m131 : 16|1@1+ (1,0) [0|1] "" Vector__XXX
 SG_ RCM2_a132_sideAB1stRowLCrssCoup_ m132 : 16|1@1+ (1,0) [0|1] "" Vector__XXX
 SG_ RCM2_a134_sideAB1stRowRSht2Gnd_s m134 : 16|1@1+ (1,0) [0|1] "" Vector__XXX
 SG_ RCM2_a135_sideAB1stRowRSht2Bat_s m135 : 16|1@1+ (1,0) [0|1] "" Vector__XXX
 SG_ RCM2_a136_sideAB1stRowROpen_s m136 : 16|1@1+ (1,0) [0|1] "" Vector__XXX
 SG_ RCM2_a137_sideAB1stRowRShort_s m137 : 16|1@1+ (1,0) [0|1] "" Vector__XXX
 SG_ RCM2_a138_sideAB1stRowRCrssCoup_ m138 : 16|1@1+ (1,0) [0|1] "" Vector__XXX
 SG_ RCM2_a140_hvdPyroSht2Gnd_s m140 : 16|1@1+ (1,0) [0|1] "" Vector__XXX
 SG_ RCM2_a141_hvdPyroSht2Bat_s m141 : 16|1@1+ (1,0) [0|1] "" Vector__XXX
 SG_ RCM2_a142_hvdPyroOpen_s m142 : 16|1@1+ (1,0) [0|1] "" Vector__XXX
 SG_ RCM2_a143_hvdPyroShort_s m143 : 16|1@1+ (1,0) [0|1] "" Vector__XXX
 SG_ RCM2_a144_hvdPyroCrssCoup_s m144 : 16|1@1+ (1,0) [0|1] "" Vector__XXX
 SG_ RCM2_a145_hvdPyroConfig_s m145 : 16|1@1+ (1,0) [0|1] "" Vector__XXX
 SG_ RCM2_a146_curABLeftSht2Gnd_s m146 : 16|1@1+ (1,0) [0|1] "" Vector__XXX
 SG_ RCM2_a147_curABLeftSht2Bat_s m147 : 16|1@1+ (1,0) [0|1] "" Vector__XXX
 SG_ RCM2_a148_curABLeftOpen_s m148 : 16|1@1+ (1,0) [0|1] "" Vector__XXX
 SG_ RCM2_a149_curABLeftShort_s m149 : 16|1@1+ (1,0) [0|1] "" Vector__XXX
 SG_ RCM2_a150_curABLeftCrssCoup_s m150 : 16|1@1+ (1,0) [0|1] "" Vector__XXX
 SG_ RCM2_a152_curABRightSht2Gnd_s m152 : 16|1@1+ (1,0) [0|1] "" Vector__XXX
 SG_ RCM2_a153_curABRightSht2Bat_s m153 : 16|1@1+ (1,0) [0|1] "" Vector__XXX
 SG_ RCM2_a154_curABRightOpen_s m154 : 16|1@1+ (1,0) [0|1] "" Vector__XXX
 SG_ RCM2_a155_curABRightShort_s m155 : 16|1@1+ (1,0) [0|1] "" Vector__XXX
 SG_ RCM2_a156_curABRightCrssCoup_s m156 : 16|1@1+ (1,0) [0|1] "" Vector__XXX
 SG_ RCM2_a158_preten2ndRowLSht2Gnd_s m158 : 16|1@1+ (1,0) [0|1] "" Vector__XXX
 SG_ RCM2_a159_preten2ndRowLSht2Bat_s m159 : 16|1@1+ (1,0) [0|1] "" Vector__XXX
 SG_ RCM2_a160_preten2ndRowLOpen_s m160 : 16|1@1+ (1,0) [0|1] "" Vector__XXX
 SG_ RCM2_a161_preten2ndRowLShort_s m161 : 16|1@1+ (1,0) [0|1] "" Vector__XXX
 SG_ RCM2_a162_preten2ndRowLCrssCoup_ m162 : 16|1@1+ (1,0) [0|1] "" Vector__XXX
 SG_ RCM2_a163_preten2ndRowLCgf_s m163 : 16|1@1+ (1,0) [0|1] "" Vector__XXX
 SG_ RCM2_a164_preten2ndRowRSht2Gnd_s m164 : 16|1@1+ (1,0) [0|1] "" Vector__XXX
 SG_ RCM2_a165_preten2ndRowRSht2Bat_s m165 : 16|1@1+ (1,0) [0|1] "" Vector__XXX
 SG_ RCM2_a166_preten2ndRowROpen_s m166 : 16|1@1+ (1,0) [0|1] "" Vector__XXX
 SG_ RCM2_a167_preten2ndRowRShort_s m167 : 16|1@1+ (1,0) [0|1] "" Vector__XXX
 SG_ RCM2_a168_preten2ndRowRCrssCoup_ m168 : 16|1@1+ (1,0) [0|1] "" Vector__XXX
 SG_ RCM2_a169_preten2ndRowRCgf_s m169 : 16|1@1+ (1,0) [0|1] "" Vector__XXX
 SG_ RCM2_a170_curAB2ndRowLSht2Gnd_s m170 : 16|1@1+ (1,0) [0|1] "" Vector__XXX
 SG_ RCM2_a171_curAB2ndRowLSht2Bat_s m171 : 16|1@1+ (1,0) [0|1] "" Vector__XXX
 SG_ RCM2_a172_curAB2ndRowLOpen_s m172 : 16|1@1+ (1,0) [0|1] "" Vector__XXX
 SG_ RCM2_a173_curAB2ndRowLShort_s m173 : 16|1@1+ (1,0) [0|1] "" Vector__XXX
 SG_ RCM2_a174_curAB2ndRowLCrssCoup_s m174 : 16|1@1+ (1,0) [0|1] "" Vector__XXX
 SG_ RCM2_a175_curAB2ndRowLConfig_s m175 : 16|1@1+ (1,0) [0|1] "" Vector__XXX
 SG_ RCM2_a176_curAB2ndRowRSht2Gnd_s m176 : 16|1@1+ (1,0) [0|1] "" Vector__XXX
 SG_ RCM2_a177_curAB2ndRowRSht2Bat_s m177 : 16|1@1+ (1,0) [0|1] "" Vector__XXX
 SG_ RCM2_a178_curAB2ndRowROpen_s m178 : 16|1@1+ (1,0) [0|1] "" Vector__XXX
 SG_ RCM2_a179_curAB2ndRowRShort_s m179 : 16|1@1+ (1,0) [0|1] "" Vector__XXX
 SG_ RCM2_a180_curAB2ndRowRCrssCoup_s m180 : 16|1@1+ (1,0) [0|1] "" Vector__XXX
 SG_ RCM2_a181_curAB2ndRowRConfig_s m181 : 16|1@1+ (1,0) [0|1] "" Vector__XXX
 SG_ RCM2_a182_hoodActuatorRSht2Gnd_s m182 : 16|1@1+ (1,0) [0|1] "" Vector__XXX
 SG_ RCM2_a183_hoodActuatorRSht2Bat_s m183 : 16|1@1+ (1,0) [0|1] "" Vector__XXX
 SG_ RCM2_a184_hoodActuatorROpen_s m184 : 16|1@1+ (1,0) [0|1] "" Vector__XXX
 SG_ RCM2_a185_hoodActuatorRShort_s m185 : 16|1@1+ (1,0) [0|1] "" Vector__XXX
 SG_ RCM2_a186_hoodActuatorRCrssCoup_ m186 : 16|1@1+ (1,0) [0|1] "" Vector__XXX
 SG_ RCM2_a187_hoodActuatorRConfig_s m187 : 16|1@1+ (1,0) [0|1] "" Vector__XXX
 SG_ RCM2_a188_hoodActuatorLSht2Gnd_s m188 : 16|1@1+ (1,0) [0|1] "" Vector__XXX
 SG_ RCM2_a189_hoodActuatorLSht2Bat_s m189 : 16|1@1+ (1,0) [0|1] "" Vector__XXX
 SG_ RCM2_a190_hoodActuatorLOpen_s m190 : 16|1@1+ (1,0) [0|1] "" Vector__XXX
 SG_ RCM2_a191_hoodActuatorLShort_s m191 : 16|1@1+ (1,0) [0|1] "" Vector__XXX
 SG_ RCM2_a192_hoodActuatorLCrssCoup_ m192 : 16|1@1+ (1,0) [0|1] "" Vector__XXX
 SG_ RCM2_a193_hoodActuatorLConfig_s m193 : 16|1@1+ (1,0) [0|1] "" Vector__XXX
 SG_ RCM2_a194_driverABAVSht2Gnd_s m194 : 16|1@1+ (1,0) [0|1] "" Vector__XXX
 SG_ RCM2_a195_driverABAVSht2Bat_s m195 : 16|1@1+ (1,0) [0|1] "" Vector__XXX
 SG_ RCM2_a196_driverABAVOpen_s m196 : 16|1@1+ (1,0) [0|1] "" Vector__XXX
 SG_ RCM2_a197_driverABAVShort_s m197 : 16|1@1+ (1,0) [0|1] "" Vector__XXX
 SG_ RCM2_a198_driverABAVCrossCoup_s m198 : 16|1@1+ (1,0) [0|1] "" Vector__XXX
 SG_ RCM2_a199_driverABAVConfig_s m199 : 16|1@1+ (1,0) [0|1] "" Vector__XXX
 SG_ RCM2_a200_driverFSABSht2Gnd_s m200 : 16|1@1+ (1,0) [0|1] "" Vector__XXX
 SG_ RCM2_a201_driverFSABSht2Bat_s m201 : 16|1@1+ (1,0) [0|1] "" Vector__XXX
 SG_ RCM2_a202_driverFSABOpen_s m202 : 16|1@1+ (1,0) [0|1] "" Vector__XXX
 SG_ RCM2_a203_driverFSABShort_s m203 : 16|1@1+ (1,0) [0|1] "" Vector__XXX
 SG_ RCM2_a204_driverFSABCrossCoup_s m204 : 16|1@1+ (1,0) [0|1] "" Vector__XXX
 SG_ RCM2_a205_driverFSABConfig_s m205 : 16|1@1+ (1,0) [0|1] "" Vector__XXX
 SG_ RCM2_a206_sideAB2ndRowLSht2Gnd_s m206 : 16|1@1+ (1,0) [0|1] "" Vector__XXX
 SG_ RCM2_a207_sideAB2ndRowLSht2Bat_s m207 : 16|1@1+ (1,0) [0|1] "" Vector__XXX
 SG_ RCM2_a208_sideAB2ndRowLOpen_s m208 : 16|1@1+ (1,0) [0|1] "" Vector__XXX
 SG_ RCM2_a209_sideAB2ndRowLShort_s m209 : 16|1@1+ (1,0) [0|1] "" Vector__XXX
 SG_ RCM2_a210_sideAB2ndRowLCrssCoup_ m210 : 16|1@1+ (1,0) [0|1] "" Vector__XXX
 SG_ RCM2_a211_sideAB2ndRowLConfig_s m211 : 16|1@1+ (1,0) [0|1] "" Vector__XXX
 SG_ RCM2_a212_sideAB2ndRowRSht2Gnd_s m212 : 16|1@1+ (1,0) [0|1] "" Vector__XXX
 SG_ RCM2_a213_sideAB2ndRowRSht2Bat_s m213 : 16|1@1+ (1,0) [0|1] "" Vector__XXX
 SG_ RCM2_a214_sideAB2ndRowROpen_s m214 : 16|1@1+ (1,0) [0|1] "" Vector__XXX
 SG_ RCM2_a215_sideAB2ndRowRShort_s m215 : 16|1@1+ (1,0) [0|1] "" Vector__XXX
 SG_ RCM2_a216_sideAB2ndRowRCrssCoup_ m216 : 16|1@1+ (1,0) [0|1] "" Vector__XXX
 SG_ RCM2_a217_sideAB2ndRowRConfig_s m217 : 16|1@1+ (1,0) [0|1] "" Vector__XXX
 SG_ RCM2_a250_ens1Sht2Bat_s m250 : 16|1@1+ (1,0) [0|1] "" Vector__XXX
 SG_ RCM2_a251_ens1Sht2Gnd_s m251 : 16|1@1+ (1,0) [0|1] "" Vector__XXX
 SG_ RCM2_a252_ens1Config_s m252 : 16|1@1+ (1,0) [0|1] "" Vector__XXX
 SG_ RCM2_a253_ens2Sht2Bat_s m253 : 16|1@1+ (1,0) [0|1] "" Vector__XXX
 SG_ RCM2_a254_ens2Sht2Gnd_s m254 : 16|1@1+ (1,0) [0|1] "" Vector__XXX
 SG_ RCM2_a256_ens3Sht2Bat_s m256 : 16|1@1+ (1,0) [0|1] "" Vector__XXX
 SG_ RCM2_a257_ens3Sht2Gnd_s m257 : 16|1@1+ (1,0) [0|1] "" Vector__XXX
 SG_ RCM2_a258_ens3Config_s m258 : 16|1@1+ (1,0) [0|1] "" Vector__XXX
 SG_ RCM2_a259_ens4Sht2Bat_s m259 : 16|1@1+ (1,0) [0|1] "" Vector__XXX
 SG_ RCM2_a260_ens4Sht2Gnd_s m260 : 16|1@1+ (1,0) [0|1] "" Vector__XXX
 SG_ RCM2_a261_ens4Config_s m261 : 16|1@1+ (1,0) [0|1] "" Vector__XXX
 SG_ RCM2_a264_imuYawR8OffCompPosLife m264 : 16|1@1+ (1,0) [0|1] "" Vector__XXX
 SG_ RCM2_a265_imuYawR8OffCompNegLife m265 : 16|1@1+ (1,0) [0|1] "" Vector__XXX
 SG_ RCM2_a266_imuYawR8OffCompPosFLDC m266 : 16|1@1+ (1,0) [0|1] "" Vector__XXX
 SG_ RCM2_a267_imuYawR8OffCompNegFLDC m267 : 16|1@1+ (1,0) [0|1] "" Vector__XXX
 SG_ RCM2_a268_imuYawR8OffCompPosSLDC m268 : 16|1@1+ (1,0) [0|1] "" Vector__XXX
 SG_ RCM2_a269_imuYawR8OffCompNegSLDC m269 : 16|1@1+ (1,0) [0|1] "" Vector__XXX
 SG_ RCM2_a270_imuPtchR8OffCompPosLif m270 : 16|1@1+ (1,0) [0|1] "" Vector__XXX
 SG_ RCM2_a271_imuPtchR8OffCompNegLif m271 : 16|1@1+ (1,0) [0|1] "" Vector__XXX
 SG_ RCM2_a272_imuPtchR8OffCompPosFLD m272 : 16|1@1+ (1,0) [0|1] "" Vector__XXX
 SG_ RCM2_a273_imuPtchR8OffCompNegFLD m273 : 16|1@1+ (1,0) [0|1] "" Vector__XXX
 SG_ RCM2_a274_imuPtchR8OffCompPosSLD m274 : 16|1@1+ (1,0) [0|1] "" Vector__XXX
 SG_ RCM2_a275_imuPtchR8OffCompNegSLD m275 : 16|1@1+ (1,0) [0|1] "" Vector__XXX
 SG_ RCM2_a276_imuRollR8OffCompPosLif m276 : 16|1@1+ (1,0) [0|1] "" Vector__XXX
 SG_ RCM2_a277_imuRollR8OffCompNegLif m277 : 16|1@1+ (1,0) [0|1] "" Vector__XXX
 SG_ RCM2_a278_imuRollR8OffCompPosFLD m278 : 16|1@1+ (1,0) [0|1] "" Vector__XXX
 SG_ RCM2_a279_imuRollR8OffCompNegFLD m279 : 16|1@1+ (1,0) [0|1] "" Vector__XXX
 SG_ RCM2_a280_imuRollR8OffCompPosSLD m280 : 16|1@1+ (1,0) [0|1] "" Vector__XXX
 SG_ RCM2_a281_imuRollR8OffCompNegSLD m281 : 16|1@1+ (1,0) [0|1] "" Vector__XXX
 SG_ RCM2_a282_imuLongAOffCompPosLife m282 : 16|1@1+ (1,0) [0|1] "" Vector__XXX
 SG_ RCM2_a283_imuLongAOffCompNegLife m283 : 16|1@1+ (1,0) [0|1] "" Vector__XXX
 SG_ RCM2_a284_imuLongAOffCompPosFLDC m284 : 16|1@1+ (1,0) [0|1] "" Vector__XXX
 SG_ RCM2_a285_imuLongAOffCompNegFLDC m285 : 16|1@1+ (1,0) [0|1] "" Vector__XXX
 SG_ RCM2_a286_imuLongAOffCompPosSLDC m286 : 16|1@1+ (1,0) [0|1] "" Vector__XXX
 SG_ RCM2_a287_imuLongAOffCompNegSLDC m287 : 16|1@1+ (1,0) [0|1] "" Vector__XXX
 SG_ RCM2_a288_imuLatAcOffCompPosLife m288 : 16|1@1+ (1,0) [0|1] "" Vector__XXX
 SG_ RCM2_a289_imuLatAcOffCompNegLife m289 : 16|1@1+ (1,0) [0|1] "" Vector__XXX
 SG_ RCM2_a290_imuLatAcOffCompPosFLDC m290 : 16|1@1+ (1,0) [0|1] "" Vector__XXX
 SG_ RCM2_a291_imuLatAcOffCompNegFLDC m291 : 16|1@1+ (1,0) [0|1] "" Vector__XXX
 SG_ RCM2_a292_imuLatAcOffCompPosSLDC m292 : 16|1@1+ (1,0) [0|1] "" Vector__XXX
 SG_ RCM2_a293_imuLatAcOffCompNegSLDC m293 : 16|1@1+ (1,0) [0|1] "" Vector__XXX
 SG_ RCM2_a294_imuVertAOffCompPosLife m294 : 16|1@1+ (1,0) [0|1] "" Vector__XXX
 SG_ RCM2_a295_imuVertAOffCompNegLife m295 : 16|1@1+ (1,0) [0|1] "" Vector__XXX
 SG_ RCM2_a296_imuVertAOffCompPosFLDC m296 : 16|1@1+ (1,0) [0|1] "" Vector__XXX
 SG_ RCM2_a297_imuVertAOffCompNegFLDC m297 : 16|1@1+ (1,0) [0|1] "" Vector__XXX
 SG_ RCM2_a298_imuVertAOffCompPosSLDC m298 : 16|1@1+ (1,0) [0|1] "" Vector__XXX
 SG_ RCM2_a299_imuVertAOffCompNegSLDC m299 : 16|1@1+ (1,0) [0|1] "" Vector__XXX
 SG_ RCM2_a300_imuAccXHgMonChlPerm_s m300 : 16|1@1+ (1,0) [0|1] "" Vector__XXX
 SG_ RCM2_a301_imuAccXHgMonChlTemp_s m301 : 16|1@1+ (1,0) [0|1] "" Vector__XXX
 SG_ RCM2_a302_imuAccYHgMonChlPerm_s m302 : 16|1@1+ (1,0) [0|1] "" Vector__XXX
 SG_ RCM2_a303_imuAccYHgMonChlTemp_s m303 : 16|1@1+ (1,0) [0|1] "" Vector__XXX
 SG_ RCM2_a304_imuYawR8SnsrPermBG_s m304 : 16|1@1+ (1,0) [0|1] "" Vector__XXX
 SG_ RCM2_a305_imuYawR8SnsrPermInit_s m305 : 16|1@1+ (1,0) [0|1] "" Vector__XXX
 SG_ RCM2_a306_imuYawR8SnsrPermLF_s m306 : 16|1@1+ (1,0) [0|1] "" Vector__XXX
 SG_ RCM2_a307_imuYawR8ChnlMonTmpLF_s m307 : 16|1@1+ (1,0) [0|1] "" Vector__XXX
 SG_ RCM2_a308_imuPitchR8SnsrPermBG_s m308 : 16|1@1+ (1,0) [0|1] "" Vector__XXX
 SG_ RCM2_a309_imuPitchR8SnsrPermInit m309 : 16|1@1+ (1,0) [0|1] "" Vector__XXX
 SG_ RCM2_a310_imuPitchR8SnsrPermLF_s m310 : 16|1@1+ (1,0) [0|1] "" Vector__XXX
 SG_ RCM2_a311_imuPitchR8ChnlMonTmpLF m311 : 16|1@1+ (1,0) [0|1] "" Vector__XXX
 SG_ RCM2_a312_imuRollR8SnsrPermBG_s m312 : 16|1@1+ (1,0) [0|1] "" Vector__XXX
 SG_ RCM2_a313_imuRollR8SnsrPermInit_ m313 : 16|1@1+ (1,0) [0|1] "" Vector__XXX
 SG_ RCM2_a314_imuRollR8SnsrPermLF_s m314 : 16|1@1+ (1,0) [0|1] "" Vector__XXX
 SG_ RCM2_a315_imuRollR8ChnlMonTmpLF_ m315 : 16|1@1+ (1,0) [0|1] "" Vector__XXX
 SG_ RCM2_a316_imuAccXLgMonChlPerm_s m316 : 16|1@1+ (1,0) [0|1] "" Vector__XXX
 SG_ RCM2_a317_imuAccXLgMonChlTemp_s m317 : 16|1@1+ (1,0) [0|1] "" Vector__XXX
 SG_ RCM2_a318_imuAccYLgMonChlPerm_s m318 : 16|1@1+ (1,0) [0|1] "" Vector__XXX
 SG_ RCM2_a319_imuAccYLgMonChlTemp_s m319 : 16|1@1+ (1,0) [0|1] "" Vector__XXX
 SG_ RCM2_a320_imuAccZLgMonChlPerm_s m320 : 16|1@1+ (1,0) [0|1] "" Vector__XXX
 SG_ RCM2_a321_imuAccZLgMonChlTemp_s m321 : 16|1@1+ (1,0) [0|1] "" Vector__XXX
 SG_ RCM2_a322_imuCalibrationFailed_s m322 : 16|1@1+ (1,0) [0|1] "" Vector__XXX
 SG_ RCM2_a323_imuCalibrationNotDone_ m323 : 16|1@1+ (1,0) [0|1] "" Vector__XXX
 SG_ RCM2_a350_upFrntSnsrLSht2Gnd_s m350 : 16|1@1+ (1,0) [0|1] "" Vector__XXX
 SG_ RCM2_a351_upFrntSnsrLSht2Bat_s m351 : 16|1@1+ (1,0) [0|1] "" Vector__XXX
 SG_ RCM2_a352_upFrntSnsrLOpen_s m352 : 16|1@1+ (1,0) [0|1] "" Vector__XXX
 SG_ RCM2_a353_upFrntSnsrLCrssCoup_s m353 : 16|1@1+ (1,0) [0|1] "" Vector__XXX
 SG_ RCM2_a354_upFrntSnsrLCommErr_s m354 : 16|1@1+ (1,0) [0|1] "" Vector__XXX
 SG_ RCM2_a355_upFrntSnsrLInitTyp_s m355 : 16|1@1+ (1,0) [0|1] "" Vector__XXX
 SG_ RCM2_a356_upFrntSnsrLConfig_s m356 : 16|1@1+ (1,0) [0|1] "" Vector__XXX
 SG_ RCM2_a357_upFrntSnsrLDefect_s m357 : 16|1@1+ (1,0) [0|1] "" Vector__XXX
 SG_ RCM2_a358_upFrntSnsrLSigMon_s m358 : 16|1@1+ (1,0) [0|1] "" Vector__XXX
 SG_ RCM2_a360_upFrntSnsrRSht2Gnd_s m360 : 16|1@1+ (1,0) [0|1] "" Vector__XXX
 SG_ RCM2_a361_upFrntSnsrRSht2Bat_s m361 : 16|1@1+ (1,0) [0|1] "" Vector__XXX
 SG_ RCM2_a362_upFrntSnsrROpen_s m362 : 16|1@1+ (1,0) [0|1] "" Vector__XXX
 SG_ RCM2_a363_upFrntSnsrRCrssCoup_s m363 : 16|1@1+ (1,0) [0|1] "" Vector__XXX
 SG_ RCM2_a364_upFrntSnsrRCommErr_s m364 : 16|1@1+ (1,0) [0|1] "" Vector__XXX
 SG_ RCM2_a365_upFrntSnsrRInitTyp_s m365 : 16|1@1+ (1,0) [0|1] "" Vector__XXX
 SG_ RCM2_a366_upFrntSnsrRConfig_s m366 : 16|1@1+ (1,0) [0|1] "" Vector__XXX
 SG_ RCM2_a367_upFrntSnsrRDefect_s m367 : 16|1@1+ (1,0) [0|1] "" Vector__XXX
 SG_ RCM2_a368_upFrntSnsrRSigMon_s m368 : 16|1@1+ (1,0) [0|1] "" Vector__XXX
 SG_ RCM2_a370_upFrntSnsrMidLSht2Gnd_ m370 : 16|1@1+ (1,0) [0|1] "" Vector__XXX
 SG_ RCM2_a371_upFrntSnsrMidLSht2Bat_ m371 : 16|1@1+ (1,0) [0|1] "" Vector__XXX
 SG_ RCM2_a372_upFrntSnsrMidLOpen_s m372 : 16|1@1+ (1,0) [0|1] "" Vector__XXX
 SG_ RCM2_a373_upFrntSnsrMidLCrssCoup m373 : 16|1@1+ (1,0) [0|1] "" Vector__XXX
 SG_ RCM2_a374_upFrntSnsrMidLCommErr_ m374 : 16|1@1+ (1,0) [0|1] "" Vector__XXX
 SG_ RCM2_a375_upFrntSnsrMidLInitTyp_ m375 : 16|1@1+ (1,0) [0|1] "" Vector__XXX
 SG_ RCM2_a376_upFrntSnsrMidLConfig_s m376 : 16|1@1+ (1,0) [0|1] "" Vector__XXX
 SG_ RCM2_a377_upFrntSnsrMidLDefect_s m377 : 16|1@1+ (1,0) [0|1] "" Vector__XXX
 SG_ RCM2_a378_upFrntSnsrMidLSigMon_s m378 : 16|1@1+ (1,0) [0|1] "" Vector__XXX
 SG_ RCM2_a380_upFrntSnsrMidRSht2Gnd_ m380 : 16|1@1+ (1,0) [0|1] "" Vector__XXX
 SG_ RCM2_a381_upFrntSnsrMidRSht2Bat_ m381 : 16|1@1+ (1,0) [0|1] "" Vector__XXX
 SG_ RCM2_a382_upFrntSnsrMidROpen_s m382 : 16|1@1+ (1,0) [0|1] "" Vector__XXX
 SG_ RCM2_a383_upFrntSnsrMidRCrssCoup m383 : 16|1@1+ (1,0) [0|1] "" Vector__XXX
 SG_ RCM2_a384_upFrntSnsrMidRCommErr_ m384 : 16|1@1+ (1,0) [0|1] "" Vector__XXX
 SG_ RCM2_a385_upFrntSnsrMidRInitTyp_ m385 : 16|1@1+ (1,0) [0|1] "" Vector__XXX
 SG_ RCM2_a386_upFrntSnsrMidRConfig_s m386 : 16|1@1+ (1,0) [0|1] "" Vector__XXX
 SG_ RCM2_a387_upFrntSnsrMidRDefect_s m387 : 16|1@1+ (1,0) [0|1] "" Vector__XXX
 SG_ RCM2_a388_upFrntSnsrMidRSigMon_s m388 : 16|1@1+ (1,0) [0|1] "" Vector__XXX
 SG_ RCM2_a390_sideAccelBPilLSht2Gnd_ m390 : 16|1@1+ (1,0) [0|1] "" Vector__XXX
 SG_ RCM2_a391_sideAccelBPilLSht2Bat_ m391 : 16|1@1+ (1,0) [0|1] "" Vector__XXX
 SG_ RCM2_a392_sideAccelBPilLOpen_s m392 : 16|1@1+ (1,0) [0|1] "" Vector__XXX
 SG_ RCM2_a393_sideAccelBPilLCLosCoup m393 : 16|1@1+ (1,0) [0|1] "" Vector__XXX
 SG_ RCM2_a394_sideAccelBPilLCommErr_ m394 : 16|1@1+ (1,0) [0|1] "" Vector__XXX
 SG_ RCM2_a395_sideAccelBPilLInitTyp_ m395 : 16|1@1+ (1,0) [0|1] "" Vector__XXX
 SG_ RCM2_a396_sideAccelBPilLConfig_s m396 : 16|1@1+ (1,0) [0|1] "" Vector__XXX
 SG_ RCM2_a397_sideAccelBPilLDefect_s m397 : 16|1@1+ (1,0) [0|1] "" Vector__XXX
 SG_ RCM2_a398_sideAccelBPilLSigMon_s m398 : 16|1@1+ (1,0) [0|1] "" Vector__XXX
 SG_ RCM2_a400_sideAccelBPilRSht2Gnd_ m400 : 16|1@1+ (1,0) [0|1] "" Vector__XXX
 SG_ RCM2_a401_sideAccelBPilRSht2Bat_ m401 : 16|1@1+ (1,0) [0|1] "" Vector__XXX
 SG_ RCM2_a402_sideAccelBPilROpen_s m402 : 16|1@1+ (1,0) [0|1] "" Vector__XXX
 SG_ RCM2_a403_sideAccelBPilRCrssCoup m403 : 16|1@1+ (1,0) [0|1] "" Vector__XXX
 SG_ RCM2_a404_sideAccelBPilRCommErr_ m404 : 16|1@1+ (1,0) [0|1] "" Vector__XXX
 SG_ RCM2_a405_sideAccelBPilRInitTyp_ m405 : 16|1@1+ (1,0) [0|1] "" Vector__XXX
 SG_ RCM2_a406_sideAccelBPilRConfig_s m406 : 16|1@1+ (1,0) [0|1] "" Vector__XXX
 SG_ RCM2_a407_sideAccelBPilRDefect_s m407 : 16|1@1+ (1,0) [0|1] "" Vector__XXX
 SG_ RCM2_a408_sideAccelBPilRSigMon_s m408 : 16|1@1+ (1,0) [0|1] "" Vector__XXX
 SG_ RCM2_a410_sideAccelCPilLSht2Gnd_ m410 : 16|1@1+ (1,0) [0|1] "" Vector__XXX
 SG_ RCM2_a411_sideAccelCPilLSht2Bat_ m411 : 16|1@1+ (1,0) [0|1] "" Vector__XXX
 SG_ RCM2_a412_sideAccelCPilLOpen_s m412 : 16|1@1+ (1,0) [0|1] "" Vector__XXX
 SG_ RCM2_a413_sideAccelCPilLCrssCoup m413 : 16|1@1+ (1,0) [0|1] "" Vector__XXX
 SG_ RCM2_a414_sideAccelCPilLCommErr_ m414 : 16|1@1+ (1,0) [0|1] "" Vector__XXX
 SG_ RCM2_a415_sideAccelCPilLInitTyp_ m415 : 16|1@1+ (1,0) [0|1] "" Vector__XXX
 SG_ RCM2_a416_sideAccelCPilLConfig_s m416 : 16|1@1+ (1,0) [0|1] "" Vector__XXX
 SG_ RCM2_a417_sideAccelCPilLDefect_s m417 : 16|1@1+ (1,0) [0|1] "" Vector__XXX
 SG_ RCM2_a418_sideAccelCPilLSigMon_s m418 : 16|1@1+ (1,0) [0|1] "" Vector__XXX
 SG_ RCM2_a420_sideAccelCPilRSht2Gnd_ m420 : 16|1@1+ (1,0) [0|1] "" Vector__XXX
 SG_ RCM2_a421_sideAccelCPilRSht2Bat_ m421 : 16|1@1+ (1,0) [0|1] "" Vector__XXX
 SG_ RCM2_a422_sideAccelCPilROpen_s m422 : 16|1@1+ (1,0) [0|1] "" Vector__XXX
 SG_ RCM2_a423_sideAccelCPilRCrssCoup m423 : 16|1@1+ (1,0) [0|1] "" Vector__XXX
 SG_ RCM2_a424_sideAccelCPilRCommErr_ m424 : 16|1@1+ (1,0) [0|1] "" Vector__XXX
 SG_ RCM2_a425_sideAccelCPilRInitTyp_ m425 : 16|1@1+ (1,0) [0|1] "" Vector__XXX
 SG_ RCM2_a426_sideAccelCPilRConfig_s m426 : 16|1@1+ (1,0) [0|1] "" Vector__XXX
 SG_ RCM2_a427_sideAccelCPilRDefect_s m427 : 16|1@1+ (1,0) [0|1] "" Vector__XXX
 SG_ RCM2_a428_sideAccelCPilRSigMon_s m428 : 16|1@1+ (1,0) [0|1] "" Vector__XXX
 SG_ RCM2_a430_presFrntLDoorSht2Gnd_s m430 : 16|1@1+ (1,0) [0|1] "" Vector__XXX
 SG_ RCM2_a431_presFrntLDoorSht2Bat_s m431 : 16|1@1+ (1,0) [0|1] "" Vector__XXX
 SG_ RCM2_a432_presFrntLDoorOpen_s m432 : 16|1@1+ (1,0) [0|1] "" Vector__XXX
 SG_ RCM2_a433_presFrntLDoorCrssCoup_ m433 : 16|1@1+ (1,0) [0|1] "" Vector__XXX
 SG_ RCM2_a434_presFrntLDoorCommErr_s m434 : 16|1@1+ (1,0) [0|1] "" Vector__XXX
 SG_ RCM2_a435_presFrntLDoorInitTyp_s m435 : 16|1@1+ (1,0) [0|1] "" Vector__XXX
 SG_ RCM2_a436_presFrntLDoorConfig_s m436 : 16|1@1+ (1,0) [0|1] "" Vector__XXX
 SG_ RCM2_a437_presFrntLDoorDefect_s m437 : 16|1@1+ (1,0) [0|1] "" Vector__XXX
 SG_ RCM2_a438_presFrntLDoorSigMon_s m438 : 16|1@1+ (1,0) [0|1] "" Vector__XXX
 SG_ RCM2_a439_presDoorAbsolute1_s m439 : 16|1@1+ (1,0) [0|1] "" Vector__XXX
 SG_ RCM2_a440_presFrntRDoorSht2Gnd_s m440 : 16|1@1+ (1,0) [0|1] "" Vector__XXX
 SG_ RCM2_a441_presFrntRDoorSht2Bat_s m441 : 16|1@1+ (1,0) [0|1] "" Vector__XXX
 SG_ RCM2_a442_presFrntRDoorOpen_s m442 : 16|1@1+ (1,0) [0|1] "" Vector__XXX
 SG_ RCM2_a443_presFrntRDoorCrssCoup_ m443 : 16|1@1+ (1,0) [0|1] "" Vector__XXX
 SG_ RCM2_a444_presFrntRDoorCommErr_s m444 : 16|1@1+ (1,0) [0|1] "" Vector__XXX
 SG_ RCM2_a445_presFrntRDoorInitTyp_s m445 : 16|1@1+ (1,0) [0|1] "" Vector__XXX
 SG_ RCM2_a446_presFrntRDoorConfig_s m446 : 16|1@1+ (1,0) [0|1] "" Vector__XXX
 SG_ RCM2_a447_presFrntRDoorDefect_s m447 : 16|1@1+ (1,0) [0|1] "" Vector__XXX
 SG_ RCM2_a448_presFrntRDoorSigMon_s m448 : 16|1@1+ (1,0) [0|1] "" Vector__XXX
 SG_ RCM2_a449_presDoorAbsolute2_s m449 : 16|1@1+ (1,0) [0|1] "" Vector__XXX
 SG_ RCM2_a450_presPedProLSht2Gnd_s m450 : 16|1@1+ (1,0) [0|1] "" Vector__XXX
 SG_ RCM2_a451_presPedProLSht2Bat_s m451 : 16|1@1+ (1,0) [0|1] "" Vector__XXX
 SG_ RCM2_a452_presPedProLOpen_s m452 : 16|1@1+ (1,0) [0|1] "" Vector__XXX
 SG_ RCM2_a453_presPedProLCrssCoup_s m453 : 16|1@1+ (1,0) [0|1] "" Vector__XXX
 SG_ RCM2_a454_presPedProLCommErr_s m454 : 16|1@1+ (1,0) [0|1] "" Vector__XXX
 SG_ RCM2_a455_presPedProLInitTyp_s m455 : 16|1@1+ (1,0) [0|1] "" Vector__XXX
 SG_ RCM2_a456_presPedProLConfig_s m456 : 16|1@1+ (1,0) [0|1] "" Vector__XXX
 SG_ RCM2_a457_presPedProLDefect_s m457 : 16|1@1+ (1,0) [0|1] "" Vector__XXX
 SG_ RCM2_a458_presPedProLSigMon_s m458 : 16|1@1+ (1,0) [0|1] "" Vector__XXX
 SG_ RCM2_a460_presPedProRSht2Gnd_s m460 : 16|1@1+ (1,0) [0|1] "" Vector__XXX
 SG_ RCM2_a461_presPedProRSht2Bat_s m461 : 16|1@1+ (1,0) [0|1] "" Vector__XXX
 SG_ RCM2_a462_presPedProROpen_s m462 : 16|1@1+ (1,0) [0|1] "" Vector__XXX
 SG_ RCM2_a463_presPedProRCrssCoup_s m463 : 16|1@1+ (1,0) [0|1] "" Vector__XXX
 SG_ RCM2_a464_presPedProRCommErr_s m464 : 16|1@1+ (1,0) [0|1] "" Vector__XXX
 SG_ RCM2_a465_presPedProRInitTyp_s m465 : 16|1@1+ (1,0) [0|1] "" Vector__XXX
 SG_ RCM2_a466_presPedProRConfig_s m466 : 16|1@1+ (1,0) [0|1] "" Vector__XXX
 SG_ RCM2_a467_presPedProRDefect_s m467 : 16|1@1+ (1,0) [0|1] "" Vector__XXX
 SG_ RCM2_a468_presPedProRSigMon_s m468 : 16|1@1+ (1,0) [0|1] "" Vector__XXX
 SG_ RCM2_a469_presPedProAbsolute_s m469 : 16|1@1+ (1,0) [0|1] "" Vector__XXX
 SG_ RCM2_a470_upFrntPedProLSht2Gnd_s m470 : 16|1@1+ (1,0) [0|1] "" Vector__XXX
 SG_ RCM2_a471_upFrntPedProLSht2Bat_s m471 : 16|1@1+ (1,0) [0|1] "" Vector__XXX
 SG_ RCM2_a472_upFrntPedProLOpen_s m472 : 16|1@1+ (1,0) [0|1] "" Vector__XXX
 SG_ RCM2_a473_upFrntPedProLCrssCoup_ m473 : 16|1@1+ (1,0) [0|1] "" Vector__XXX
 SG_ RCM2_a474_upFrntPedProLCommErr_s m474 : 16|1@1+ (1,0) [0|1] "" Vector__XXX
 SG_ RCM2_a475_upFrntPedProLIntTyp_s m475 : 16|1@1+ (1,0) [0|1] "" Vector__XXX
 SG_ RCM2_a476_upFrntPedProLConfig_s m476 : 16|1@1+ (1,0) [0|1] "" Vector__XXX
 SG_ RCM2_a477_upFrntPedProLDefect_s m477 : 16|1@1+ (1,0) [0|1] "" Vector__XXX
 SG_ RCM2_a478_upFrntPedProLSigMon_s m478 : 16|1@1+ (1,0) [0|1] "" Vector__XXX
 SG_ RCM2_a480_upFrntPedProRSht2Gnd_s m480 : 16|1@1+ (1,0) [0|1] "" Vector__XXX
 SG_ RCM2_a481_upFrntPedProRSht2Bat_s m481 : 16|1@1+ (1,0) [0|1] "" Vector__XXX
 SG_ RCM2_a482_upFrntPedProROpen_s m482 : 16|1@1+ (1,0) [0|1] "" Vector__XXX
 SG_ RCM2_a483_upFrntPedProRCrssCoup_ m483 : 16|1@1+ (1,0) [0|1] "" Vector__XXX
 SG_ RCM2_a484_upFrntPedProRCommErr_s m484 : 16|1@1+ (1,0) [0|1] "" Vector__XXX
 SG_ RCM2_a485_upFrntPedProRIntTyp_s m485 : 16|1@1+ (1,0) [0|1] "" Vector__XXX
 SG_ RCM2_a486_upFrntPedProRConfig_s m486 : 16|1@1+ (1,0) [0|1] "" Vector__XXX
 SG_ RCM2_a487_upFrntPedProRDefect_s m487 : 16|1@1+ (1,0) [0|1] "" Vector__XXX
 SG_ RCM2_a488_upFrntPedProRSigMon_s m488 : 16|1@1+ (1,0) [0|1] "" Vector__XXX
 SG_ RCM2_a490_presRearLDoorSht2Gnd_s m490 : 16|1@1+ (1,0) [0|1] "" Vector__XXX
 SG_ RCM2_a491_presRearLDoorSht2Bat_s m491 : 16|1@1+ (1,0) [0|1] "" Vector__XXX
 SG_ RCM2_a492_presRearLDoorOpen_s m492 : 16|1@1+ (1,0) [0|1] "" Vector__XXX
 SG_ RCM2_a493_presRearLDoorCrssCoup_ m493 : 16|1@1+ (1,0) [0|1] "" Vector__XXX
 SG_ RCM2_a494_presRearLDoorCommErr_s m494 : 16|1@1+ (1,0) [0|1] "" Vector__XXX
 SG_ RCM2_a495_presRearLDoorInitTyp_s m495 : 16|1@1+ (1,0) [0|1] "" Vector__XXX
 SG_ RCM2_a496_presRearLDoorConfig_s m496 : 16|1@1+ (1,0) [0|1] "" Vector__XXX
 SG_ RCM2_a497_presRearLDoorDefect_s m497 : 16|1@1+ (1,0) [0|1] "" Vector__XXX
 SG_ RCM2_a498_presRearLDoorSigMon_s m498 : 16|1@1+ (1,0) [0|1] "" Vector__XXX
 SG_ RCM2_a500_presRearRDoorSht2Gnd_s m500 : 16|1@1+ (1,0) [0|1] "" Vector__XXX
 SG_ RCM2_a501_presRearRDoorSht2Bat_s m501 : 16|1@1+ (1,0) [0|1] "" Vector__XXX
 SG_ RCM2_a502_presRearRDoorOpen_s m502 : 16|1@1+ (1,0) [0|1] "" Vector__XXX
 SG_ RCM2_a503_presRearRDoorCrssCoup_ m503 : 16|1@1+ (1,0) [0|1] "" Vector__XXX
 SG_ RCM2_a504_presRearRDoorCommErr_s m504 : 16|1@1+ (1,0) [0|1] "" Vector__XXX
 SG_ RCM2_a505_presRearRDoorInitTyp_s m505 : 16|1@1+ (1,0) [0|1] "" Vector__XXX
 SG_ RCM2_a506_presRearRDoorConfig_s m506 : 16|1@1+ (1,0) [0|1] "" Vector__XXX
 SG_ RCM2_a507_presRearRDoorDefect_s m507 : 16|1@1+ (1,0) [0|1] "" Vector__XXX
 SG_ RCM2_a508_presRearRDoorSigMon_s m508 : 16|1@1+ (1,0) [0|1] "" Vector__XXX
 SG_ RCM2_a509_sideAccelDPilLSht2Gnd_ m509 : 16|1@1+ (1,0) [0|1] "" Vector__XXX
 SG_ RCM2_a510_sideAccelDPilLSht2Bat_ m510 : 16|1@1+ (1,0) [0|1] "" Vector__XXX
 SG_ RCM2_a511_sideAccelDPilLOpen_s m511 : 16|1@1+ (1,0) [0|1] "" Vector__XXX
 SG_ RCM2_a512_sideAccelDPilLCrssCoup m512 : 16|1@1+ (1,0) [0|1] "" Vector__XXX
 SG_ RCM2_a513_sideAccelDPilLCommErr_ m513 : 16|1@1+ (1,0) [0|1] "" Vector__XXX
 SG_ RCM2_a514_sideAccelDPilLInitTyp_ m514 : 16|1@1+ (1,0) [0|1] "" Vector__XXX
 SG_ RCM2_a515_sideAccelDPilLConfig_s m515 : 16|1@1+ (1,0) [0|1] "" Vector__XXX
 SG_ RCM2_a516_sideAccelDPilLDefect_s m516 : 16|1@1+ (1,0) [0|1] "" Vector__XXX
 SG_ RCM2_a517_sideAccelDPilLSigMon_s m517 : 16|1@1+ (1,0) [0|1] "" Vector__XXX
 SG_ RCM2_a518_sideAccelDPilRSht2Gnd_ m518 : 16|1@1+ (1,0) [0|1] "" Vector__XXX
 SG_ RCM2_a519_sideAccelDPilRSht2Bat_ m519 : 16|1@1+ (1,0) [0|1] "" Vector__XXX
 SG_ RCM2_a520_sideAccelDPilROpen_s m520 : 16|1@1+ (1,0) [0|1] "" Vector__XXX
 SG_ RCM2_a521_sideAccelDPilRCrssCoup m521 : 16|1@1+ (1,0) [0|1] "" Vector__XXX
 SG_ RCM2_a522_sideAccelDPilRCommErr_ m522 : 16|1@1+ (1,0) [0|1] "" Vector__XXX
 SG_ RCM2_a523_sideAccelDPilRInitTyp_ m523 : 16|1@1+ (1,0) [0|1] "" Vector__XXX
 SG_ RCM2_a524_sideAccelDPilRConfig_s m524 : 16|1@1+ (1,0) [0|1] "" Vector__XXX
 SG_ RCM2_a525_sideAccelDPilRDefect_s m525 : 16|1@1+ (1,0) [0|1] "" Vector__XXX
 SG_ RCM2_a526_sideAccelDPilRSigMon_s m526 : 16|1@1+ (1,0) [0|1] "" Vector__XXX
 SG_ RCM2_a527_upFrntSnsrCSht2Gnd_s m527 : 16|1@1+ (1,0) [0|1] "" Vector__XXX
 SG_ RCM2_a528_upFrntSnsrCSht2Bat_s m528 : 16|1@1+ (1,0) [0|1] "" Vector__XXX
 SG_ RCM2_a529_upFrntSnsrCOpen_s m529 : 16|1@1+ (1,0) [0|1] "" Vector__XXX
 SG_ RCM2_a530_upFrntSnsrCCrssCoup_s m530 : 16|1@1+ (1,0) [0|1] "" Vector__XXX
 SG_ RCM2_a531_upFrntSnsrCCommErr_s m531 : 16|1@1+ (1,0) [0|1] "" Vector__XXX
 SG_ RCM2_a532_upFrntSnsrCInitTyp_s m532 : 16|1@1+ (1,0) [0|1] "" Vector__XXX
 SG_ RCM2_a533_upFrntSnsrCConfig_s m533 : 16|1@1+ (1,0) [0|1] "" Vector__XXX
 SG_ RCM2_a534_upFrntSnsrCDefect_s m534 : 16|1@1+ (1,0) [0|1] "" Vector__XXX
 SG_ RCM2_a535_upFrntSnsrCSigMon_s m535 : 16|1@1+ (1,0) [0|1] "" Vector__XXX
 SG_ RCM2_a550_bucklHallLeftSht2Gnd_s m550 : 16|1@1+ (1,0) [0|1] "" Vector__XXX
 SG_ RCM2_a551_bucklHallLeftSht2Bat_s m551 : 16|1@1+ (1,0) [0|1] "" Vector__XXX
 SG_ RCM2_a552_bucklHallLeftOpen_s m552 : 16|1@1+ (1,0) [0|1] "" Vector__XXX
 SG_ RCM2_a553_bucklHallLeftUndef_s m553 : 16|1@1+ (1,0) [0|1] "" Vector__XXX
 SG_ RCM2_a554_bucklHallLeftCrssCoup_ m554 : 16|1@1+ (1,0) [0|1] "" Vector__XXX
 SG_ RCM2_a555_bucklHallLeftConfig_s m555 : 16|1@1+ (1,0) [0|1] "" Vector__XXX
 SG_ RCM2_a556_bucklHallRightSht2Gnd_ m556 : 16|1@1+ (1,0) [0|1] "" Vector__XXX
 SG_ RCM2_a557_bucklHallRightSht2Bat_ m557 : 16|1@1+ (1,0) [0|1] "" Vector__XXX
 SG_ RCM2_a558_bucklHallRightOpen_s m558 : 16|1@1+ (1,0) [0|1] "" Vector__XXX
 SG_ RCM2_a559_bucklHallRightUndef_s m559 : 16|1@1+ (1,0) [0|1] "" Vector__XXX
 SG_ RCM2_a560_bucklHallRightCrssCoup m560 : 16|1@1+ (1,0) [0|1] "" Vector__XXX
 SG_ RCM2_a561_bucklHallRightConfig_s m561 : 16|1@1+ (1,0) [0|1] "" Vector__XXX
 SG_ RCM2_a562_seaTrkPosLeftSht2Gnd_s m562 : 16|1@1+ (1,0) [0|1] "" Vector__XXX
 SG_ RCM2_a563_seaTrkPosLeftShtBat_s m563 : 16|1@1+ (1,0) [0|1] "" Vector__XXX
 SG_ RCM2_a564_seaTrkPosLeftOpen_s m564 : 16|1@1+ (1,0) [0|1] "" Vector__XXX
 SG_ RCM2_a565_seaTrkPosLeftUndefined m565 : 16|1@1+ (1,0) [0|1] "" Vector__XXX
 SG_ RCM2_a566_seaTrkPosLeftCrssCoup_ m566 : 16|1@1+ (1,0) [0|1] "" Vector__XXX
 SG_ RCM2_a567_seaTrkPosLeftConfig_s m567 : 16|1@1+ (1,0) [0|1] "" Vector__XXX
 SG_ RCM2_a568_occPROSSht2Gnd_s m568 : 16|1@1+ (1,0) [0|1] "" Vector__XXX
 SG_ RCM2_a569_occPROSSht2Bat_s m569 : 16|1@1+ (1,0) [0|1] "" Vector__XXX
 SG_ RCM2_a570_occPROSOpen_s m570 : 16|1@1+ (1,0) [0|1] "" Vector__XXX
 SG_ RCM2_a571_occPROSUndef_s m571 : 16|1@1+ (1,0) [0|1] "" Vector__XXX
 SG_ RCM2_a572_occPROSCrssCoup_s m572 : 16|1@1+ (1,0) [0|1] "" Vector__XXX
 SG_ RCM2_a573_occPROSConfig_s m573 : 16|1@1+ (1,0) [0|1] "" Vector__XXX
 SG_ RCM2_a587_sbrRearNetworkSht2Gnd_ m587 : 16|1@1+ (1,0) [0|1] "" Vector__XXX
 SG_ RCM2_a588_sbrRearNetworkSht2Bat_ m588 : 16|1@1+ (1,0) [0|1] "" Vector__XXX
 SG_ RCM2_a591_sbrRearNetworkCrssCoup m591 : 16|1@1+ (1,0) [0|1] "" Vector__XXX
 SG_ RCM2_a592_sbrRearNetworkConfig_s m592 : 16|1@1+ (1,0) [0|1] "" Vector__XXX
 SG_ RCM2_a593_driveOrientationSht2Gn m593 : 16|1@1+ (1,0) [0|1] "" Vector__XXX
 SG_ RCM2_a594_driveOrientationSht2Ba m594 : 16|1@1+ (1,0) [0|1] "" Vector__XXX
 SG_ RCM2_a595_driveOrientationOpen_s m595 : 16|1@1+ (1,0) [0|1] "" Vector__XXX
 SG_ RCM2_a596_driveOrientationUndefi m596 : 16|1@1+ (1,0) [0|1] "" Vector__XXX
 SG_ RCM2_a597_driveOrientationCrssCo m597 : 16|1@1+ (1,0) [0|1] "" Vector__XXX
 SG_ RCM2_a598_driveOrientationConfig m598 : 16|1@1+ (1,0) [0|1] "" Vector__XXX
 SG_ RCM2_a600_comCANinternalTimeout_ m600 : 16|1@1+ (1,0) [0|1] "" Vector__XXX
 SG_ RCM2_a601_comChassisCANSilent_s m601 : 16|1@1+ (1,0) [0|1] "" Vector__XXX
 SG_ RCM2_a602_comChassisCANBusOff_s m602 : 16|1@1+ (1,0) [0|1] "" Vector__XXX
 SG_ RCM2_a603_comPARTYCANSilent_s m603 : 16|1@1+ (1,0) [0|1] "" Vector__XXX
 SG_ RCM2_a604_comPARTYCANBusOff_s m604 : 16|1@1+ (1,0) [0|1] "" Vector__XXX
 SG_ RCM2_a620_comInvalidVehicleSpeed m620 : 16|1@1+ (1,0) [0|1] "" Vector__XXX
 SG_ RCM2_a630_comGTWACSMIA_s m630 : 16|1@1+ (1,0) [0|1] "" Vector__XXX
 SG_ RCM2_a631_comGTWACSChkSm_s m631 : 16|1@1+ (1,0) [0|1] "" Vector__XXX
 SG_ RCM2_a632_comGTWACSCntr_s m632 : 16|1@1+ (1,0) [0|1] "" Vector__XXX
 SG_ RCM2_a633_comOCS1PMIA_s m633 : 16|1@1+ (1,0) [0|1] "" Vector__XXX
 SG_ RCM2_a634_comOCS1PChkSm_s m634 : 16|1@1+ (1,0) [0|1] "" Vector__XXX
 SG_ RCM2_a635_comOCS1PCntr_s m635 : 16|1@1+ (1,0) [0|1] "" Vector__XXX
 SG_ RCM2_a636_ocsFaulted_s m636 : 16|1@1+ (1,0) [0|1] "" Vector__XXX
 SG_ RCM2_a637_ocsUnknown_s m637 : 16|1@1+ (1,0) [0|1] "" Vector__XXX
 SG_ RCM2_a642_comVINmessageMIA_s m642 : 16|1@1+ (1,0) [0|1] "" Vector__XXX
 SG_ RCM2_a652_ambientTempFaulted_s m652 : 16|1@1+ (1,0) [0|1] "" Vector__XXX
 SG_ RCM2_a656_comVCSEATPrestMIA_s m656 : 16|1@1+ (1,0) [0|1] "" Vector__XXX
 SG_ RCM2_a657_comVCSEATPrestChkSm_s m657 : 16|1@1+ (1,0) [0|1] "" Vector__XXX
 SG_ RCM2_a658_comVCSEATPrestCntr_s m658 : 16|1@1+ (1,0) [0|1] "" Vector__XXX
 SG_ RCM2_a659_comVCSEATPbuckle_s m659 : 16|1@1+ (1,0) [0|1] "" Vector__XXX
 SG_ RCM2_a660_comVCSEATPOccpy_s m660 : 16|1@1+ (1,0) [0|1] "" Vector__XXX
 SG_ RCM2_a661_comVCSEATPocs_s m661 : 16|1@1+ (1,0) [0|1] "" Vector__XXX
 SG_ RCM2_a662_comVCSEATPstps_s m662 : 16|1@1+ (1,0) [0|1] "" Vector__XXX
 SG_ RCM2_a663_comVCSEATDrestMIA_s m663 : 16|1@1+ (1,0) [0|1] "" Vector__XXX
 SG_ RCM2_a664_comVCSEATDrestChkSm_s m664 : 16|1@1+ (1,0) [0|1] "" Vector__XXX
 SG_ RCM2_a665_comVCSEATDrestCntr_s m665 : 16|1@1+ (1,0) [0|1] "" Vector__XXX
 SG_ RCM2_a666_comVCSEATDbuckle_s m666 : 16|1@1+ (1,0) [0|1] "" Vector__XXX
 SG_ RCM2_a667_comVCSEATDOccpy_s m667 : 16|1@1+ (1,0) [0|1] "" Vector__XXX
 SG_ RCM2_a668_comVCSEATDstps_s m668 : 16|1@1+ (1,0) [0|1] "" Vector__XXX
 SG_ RCM2_a688_comVCLEFTrestMIA_s m688 : 16|1@1+ (1,0) [0|1] "" Vector__XXX
 SG_ RCM2_a689_comVCLEFTrestChkSm_s m689 : 16|1@1+ (1,0) [0|1] "" Vector__XXX
 SG_ RCM2_a690_comVCLEFTrestCntr_s m690 : 16|1@1+ (1,0) [0|1] "" Vector__XXX
 SG_ RCM2_a691_comVCLEFT1rLBuckle_s m691 : 16|1@1+ (1,0) [0|1] "" Vector__XXX
 SG_ RCM2_a692_comVCLEFT2rLBuckle_s m692 : 16|1@1+ (1,0) [0|1] "" Vector__XXX
 SG_ RCM2_a693_comVCLEFT1rLSTPS_s m693 : 16|1@1+ (1,0) [0|1] "" Vector__XXX
 SG_ RCM2_a694_comVCRIGHTrestMIA_s m694 : 16|1@1+ (1,0) [0|1] "" Vector__XXX
 SG_ RCM2_a695_comVCRIGHTrestChkSm_s m695 : 16|1@1+ (1,0) [0|1] "" Vector__XXX
 SG_ RCM2_a696_comVCRIGHTrestCntr_s m696 : 16|1@1+ (1,0) [0|1] "" Vector__XXX
 SG_ RCM2_a697_comVCRIGHT1rRBuckle_s m697 : 16|1@1+ (1,0) [0|1] "" Vector__XXX
 SG_ RCM2_a698_comVCRIGHT2rRBuckle_s m698 : 16|1@1+ (1,0) [0|1] "" Vector__XXX
 SG_ RCM2_a699_comVCRIGHTocs_s m699 : 16|1@1+ (1,0) [0|1] "" Vector__XXX
 SG_ RCM2_a700_comVCRIGHT1rRSTPS_s m700 : 16|1@1+ (1,0) [0|1] "" Vector__XXX
 SG_ RCM2_a750_linInternalTimeout_s m750 : 16|1@1+ (1,0) [0|1] "" Vector__XXX
 SG_ RCM2_a799_internalFault_s m799 : 16|1@1+ (1,0) [0|1] "" Vector__XXX
 SG_ RCM2_a800_crcFault_s m800 : 16|1@1+ (1,0) [0|1] "" Vector__XXX
 SG_ RCM2_a801_parameterLayoutID_s m801 : 16|1@1+ (1,0) [0|1] "" Vector__XXX
 SG_ RCM2_a802_parameterTransferID_s m802 : 16|1@1+ (1,0) [0|1] "" Vector__XXX
 SG_ RCM2_a803_algoVerifySensorID_s m803 : 16|1@1+ (1,0) [0|1] "" Vector__XXX
 SG_ RCM2_a804_configDataInconsistent m804 : 16|1@1+ (1,0) [0|1] "" Vector__XXX
 SG_ RCM2_a805_swVersionWrong_s m805 : 16|1@1+ (1,0) [0|1] "" Vector__XXX
 SG_ RCM2_a806_configVINnotLearned_s m806 : 16|1@1+ (1,0) [0|1] "" Vector__XXX
 SG_ RCM2_a807_configVINmismatch_s m807 : 16|1@1+ (1,0) [0|1] "" Vector__XXX
 SG_ RCM2_a808_configDriveNotLearned_ m808 : 16|1@1+ (1,0) [0|1] "" Vector__XXX
 SG_ RCM2_a809_configDriveMismatch_s m809 : 16|1@1+ (1,0) [0|1] "" Vector__XXX
 SG_ RCM2_a810_bootUpActionFailure_s m810 : 16|1@1+ (1,0) [0|1] "" Vector__XXX
 SG_ RCM2_a815_upFrntPedProMLSht2Gnd_ m815 : 16|1@1+ (1,0) [0|1] "" Vector__XXX
 SG_ RCM2_a816_upFrntPedProMLSht2Bat_ m816 : 16|1@1+ (1,0) [0|1] "" Vector__XXX
 SG_ RCM2_a817_upFrntPedProMLOpen_s m817 : 16|1@1+ (1,0) [0|1] "" Vector__XXX
 SG_ RCM2_a818_upFrntPedProMLCrssCoup m818 : 16|1@1+ (1,0) [0|1] "" Vector__XXX
 SG_ RCM2_a819_upFrntPedProMLCommErr_ m819 : 16|1@1+ (1,0) [0|1] "" Vector__XXX
 SG_ RCM2_a820_upFrntPedProMLIntTyp_s m820 : 16|1@1+ (1,0) [0|1] "" Vector__XXX
 SG_ RCM2_a821_upFrntPedProMLConfig_s m821 : 16|1@1+ (1,0) [0|1] "" Vector__XXX
 SG_ RCM2_a822_upFrntPedProMLDefect_s m822 : 16|1@1+ (1,0) [0|1] "" Vector__XXX
 SG_ RCM2_a823_upFrntPedProMLSigMon_s m823 : 16|1@1+ (1,0) [0|1] "" Vector__XXX
 SG_ RCM2_a824_upFrntPedProMRSht2Gnd_ m824 : 16|1@1+ (1,0) [0|1] "" Vector__XXX
 SG_ RCM2_a825_upFrntPedProMRSht2Bat_ m825 : 16|1@1+ (1,0) [0|1] "" Vector__XXX
 SG_ RCM2_a826_upFrntPedProMROpen_s m826 : 16|1@1+ (1,0) [0|1] "" Vector__XXX
 SG_ RCM2_a827_upFrntPedProMRCrssCoup m827 : 16|1@1+ (1,0) [0|1] "" Vector__XXX
 SG_ RCM2_a828_upFrntPedProMRCommErr_ m828 : 16|1@1+ (1,0) [0|1] "" Vector__XXX
 SG_ RCM2_a829_upFrntPedProMRIntTyp_s m829 : 16|1@1+ (1,0) [0|1] "" Vector__XXX
 SG_ RCM2_a830_upFrntPedProMRConfig_s m830 : 16|1@1+ (1,0) [0|1] "" Vector__XXX
 SG_ RCM2_a831_upFrntPedProMRDefect_s m831 : 16|1@1+ (1,0) [0|1] "" Vector__XXX
 SG_ RCM2_a832_upFrntPedProMRSigMon_s m832 : 16|1@1+ (1,0) [0|1] "" Vector__XXX
 SG_ RCM2_a833_pretenShldCSht2Gnd_s m833 : 16|1@1+ (1,0) [0|1] "" Vector__XXX
 SG_ RCM2_a834_pretenShldCSht2Bat_s m834 : 16|1@1+ (1,0) [0|1] "" Vector__XXX
 SG_ RCM2_a835_pretenShldCOpen_s m835 : 16|1@1+ (1,0) [0|1] "" Vector__XXX
 SG_ RCM2_a836_pretenShldCShort_s m836 : 16|1@1+ (1,0) [0|1] "" Vector__XXX
 SG_ RCM2_a837_pretenShldCCrossC_s m837 : 16|1@1+ (1,0) [0|1] "" Vector__XXX
 SG_ RCM2_a838_pretenShldCConfig_s m838 : 16|1@1+ (1,0) [0|1] "" Vector__XXX
 SG_ RCM2_a839_preten2ndRowCSht2Gnd_s m839 : 16|1@1+ (1,0) [0|1] "" Vector__XXX
 SG_ RCM2_a840_preten2ndRowCSht2Bat_s m840 : 16|1@1+ (1,0) [0|1] "" Vector__XXX
 SG_ RCM2_a841_preten2ndRowCOpen_s m841 : 16|1@1+ (1,0) [0|1] "" Vector__XXX
 SG_ RCM2_a842_preten2ndRowCShort_s m842 : 16|1@1+ (1,0) [0|1] "" Vector__XXX
 SG_ RCM2_a843_preten2ndRowCCrssCoup_ m843 : 16|1@1+ (1,0) [0|1] "" Vector__XXX
 SG_ RCM2_a844_preten2ndRowCConfig_s m844 : 16|1@1+ (1,0) [0|1] "" Vector__XXX
 SG_ RCM2_a852_autarkyEvent_s m852 : 16|1@1+ (1,0) [0|1] "" Vector__XXX
 SG_ RCM2_a853_ConfigParametersIncons m853 : 16|1@1+ (1,0) [0|1] "" Vector__XXX
 SG_ RCM2_a854_ConfigParametersNotLea m854 : 16|1@1+ (1,0) [0|1] "" Vector__XXX
 SG_ RCM2_a857_comVCLEFT2rCBuckle_s m857 : 16|1@1+ (1,0) [0|1] "" Vector__XXX
 SG_ RCM2_a861_typeApprovalStringNotL m861 : 16|1@1+ (1,0) [0|1] "" Vector__XXX
 SG_ RCM2_a868_headAB3rdRowRSht2Gnd_s m868 : 16|1@1+ (1,0) [0|1] "" Vector__XXX
 SG_ RCM2_a869_headAB3rdRowRSht2Bat_s m869 : 16|1@1+ (1,0) [0|1] "" Vector__XXX
 SG_ RCM2_a870_headAB3rdRowROpen_s m870 : 16|1@1+ (1,0) [0|1] "" Vector__XXX
 SG_ RCM2_a871_headAB3rdRowRShort_s m871 : 16|1@1+ (1,0) [0|1] "" Vector__XXX
 SG_ RCM2_a872_headAB3rdRowRCrossC_s m872 : 16|1@1+ (1,0) [0|1] "" Vector__XXX
 SG_ RCM2_a873_headAB3rdRowRConfig_s m873 : 16|1@1+ (1,0) [0|1] "" Vector__XXX
 SG_ RCM2_a874_headAB3rdRowLSht2Gnd_s m874 : 16|1@1+ (1,0) [0|1] "" Vector__XXX
 SG_ RCM2_a875_headAB3rdRowLSht2Bat_s m875 : 16|1@1+ (1,0) [0|1] "" Vector__XXX
 SG_ RCM2_a876_headAB3rdRowLOpen_s m876 : 16|1@1+ (1,0) [0|1] "" Vector__XXX
 SG_ RCM2_a877_headAB3rdRowLShort_s m877 : 16|1@1+ (1,0) [0|1] "" Vector__XXX
 SG_ RCM2_a878_headAB3rdRowLCrossC_s m878 : 16|1@1+ (1,0) [0|1] "" Vector__XXX
 SG_ RCM2_a879_headAB3rdRowLConfig_s m879 : 16|1@1+ (1,0) [0|1] "" Vector__XXX

BO_TX_BU_ 896 : PM;
BO_TX_BU_ 2020 : PM;
BO_TX_BU_ 463 : PM;
BO_TX_BU_ 2038 : PM;
BO_TX_BU_ 1766 : PNCD;
BO_TX_BU_ 519 : PTC;
BO_TX_BU_ 837 : PTC;
BO_TX_BU_ 2019 : PTC;
BO_TX_BU_ 1365 : RADC;
BO_TX_BU_ 1282 : RADC;
BO_TX_BU_ 1329 : RADC;
BO_TX_BU_ 1249 : RCM2;
CM_ BO_ 896 "PM ECU message: alert matrix2";
CM_ SG_ 896 PM_a066_pmfMIA "PM ECU: a066 pmf MIA";
CM_ SG_ 896 PM_a067_pmrMIA "PM ECU: a067 pmr MIA";
CM_ SG_ 896 PM_a068_brakePedalMonitor "PM ECU: a068 brake pedal monitor";
CM_ SG_ 896 PM_a069_brakeMonitorsUnhealthy "PM ECU: a069 brake monitors unhealthy";
CM_ SG_ 896 PM_a070_brakeTorqueSplitMonitorT "PM ECU: a070 brake torque split monitor trip";
CM_ SG_ 896 PM_a071_baseBrakingMonitor "PM ECU: a071 base braking monitor";
CM_ SG_ 896 PM_a072_brakeTorqueCommandInterf "PM ECU: a072 brake torque command interface";
CM_ SG_ 896 PM_a073_canDataBusC "PM ECU: a073 can data bus c";
CM_ SG_ 896 PM_a074_canHardwareBusC "PM ECU: a074 can hardware bus c";
CM_ SG_ 896 PM_a075_canDataBusD "PM ECU: a075 can data bus d";
CM_ SG_ 896 PM_a076_canHardwareBusD "PM ECU: a076 can hardware bus d";
CM_ SG_ 896 PM_a077_canDataBusE "PM ECU: a077 can data bus e";
CM_ SG_ 896 PM_a078_canHardwareBusE "PM ECU: a078 can hardware bus e";
CM_ SG_ 896 PM_a079_rcuMIA "PM ECU: a079 rcu MIA";
CM_ SG_ 896 PM_a080_exceptionPrefetchAbort "PM ECU: a080 exception prefetch abort";
CM_ SG_ 896 PM_a081_exceptionDataAbort "PM ECU: a081 exception data abort";
CM_ SG_ 896 PM_a082_exceptionDataAbort2 "PM ECU: a082 exception data abort2";
CM_ SG_ 896 PM_a083_ahbWriteError "PM ECU: a083 ahb write error";
CM_ SG_ 896 PM_a084_exceptionMpuFirewall "PM ECU: a084 exception mpu firewall";
CM_ SG_ 896 PM_a085_dpbMIA "PM ECU: a085 dpb MIA";
CM_ SG_ 896 PM_a086_exceptionUndefinedInstru "PM ECU: a086 exception undefined instruction";
CM_ SG_ 896 PM_a087_canHardwareBusLIPC "PM ECU: a087 can hardware bus LIPC";
CM_ SG_ 896 PM_a092_xtalOscillator "PM ECU: a092 xtal oscillator";
CM_ SG_ 896 PM_a093_accelPedalSupply "PM ECU: a093 accel pedal supply";
CM_ SG_ 896 PM_a095_ITPMSTimeoutGNSSConverge "PM ECU: a095 ITPMS timeout GNSS convergence";
CM_ SG_ 896 PM_a096_ITPMSConvergedGNSSAbsRad "PM ECU: a096 ITPMS converged GNSS abs radius times";
CM_ SG_ 896 PM_a098_ITPMSTriggerDebug "PM ECU: a098 ITPMS trigger debug";
CM_ SG_ 896 PM_a099_ITPMSCalibrated "PM ECU: a099 ITPMS calibrated";
CM_ SG_ 896 PM_a100_diTraceInfo1 "PM ECU: a100 di trace info1";
CM_ SG_ 896 PM_a110_indirectTPMSSoftWarningF "PM ECU: a110 indirect TPMS soft warning front left";
CM_ SG_ 896 PM_a111_indirectTPMSSoftWarningF "PM ECU: a111 indirect TPMS soft warning front right";
CM_ SG_ 896 PM_a112_indirectTPMSSoftWarningR "PM ECU: a112 indirect TPMS soft warning rear left";
CM_ SG_ 896 PM_a113_indirectTPMSSoftWarningR "PM ECU: a113 indirect TPMS soft warning rear right";
CM_ SG_ 896 PM_a114_indirectTPMSHardWarningF "PM ECU: a114 indirect TPMS hard warning front left";
CM_ SG_ 896 PM_a115_indirectTPMSHardWarningF "PM ECU: a115 indirect TPMS hard warning front right";
CM_ SG_ 896 PM_a116_indirectTPMSHardWarningR "PM ECU: a116 indirect TPMS hard warning rear left";
CM_ SG_ 896 PM_a117_indirectTPMSHardWarningR "PM ECU: a117 indirect TPMS hard warning rear right";
CM_ SG_ 896 PM_a120_indirectTPMSFaulted "PM ECU: a120 indirect TPMS faulted";
CM_ SG_ 896 PM_a121_unintendedReset2 "PM ECU: a121 unintended reset2";
CM_ BO_ 2020 "PM ECU message: info";
CM_ SG_ 2020 PM_infoIndex "PM ECU: info index";
CM_ SG_ 2020 PM_buildType "PM ECU: build type";
CM_ SG_ 2020 PM_buildConfigurationId "PM ECU: build configuration id";
CM_ SG_ 2020 PM_hardwareId "PM ECU: hardware id";
CM_ SG_ 2020 PM_deviceFused "PM ECU: device fused";
CM_ SG_ 2020 PM_componentId "PM ECU: component id";
CM_ SG_ 2020 PM_pcbaId "PM ECU: pcba id";
CM_ SG_ 2020 PM_assemblyId "PM ECU: assembly id";
CM_ SG_ 2020 PM_usageId "PM ECU: usage id";
CM_ SG_ 2020 PM_subUsageId "PM ECU: sub usage id";
CM_ SG_ 2020 PM_applicationCrc "PM ECU: application crc";
CM_ SG_ 2020 PM_bootGitHash "PM ECU: boot git hash";
CM_ BO_ 463 "PM ECU message: system state";
CM_ SG_ 463 PM_torqueCheckState "PM ECU: torque check state";
CM_ SG_ 463 PM_limpRequest "PM ECU: limp request";
CM_ SG_ 463 PM_torqueCommand "PM ECU: torque command; raw 4096 = signal not available (SNA)";
CM_ SG_ 463 PM_torqueState "PM ECU: torque state";
CM_ SG_ 463 PM_hvilSystemStatus "HVIL system status; raw 3 = signal not available (SNA)";
CM_ SG_ 463 PM_sysElecPower "PM ECU: sys elec power; raw 1024 = signal not available (SNA)";
CM_ SG_ 463 PM_sysNumUnitsMia "PM ECU: sys num units mia";
CM_ SG_ 463 PM_sysNumUnitsSna "PM ECU: sys num units sna";
CM_ SG_ 463 PM_sysElecPowerVeryLow "PM ECU: sys elec power very low";
CM_ SG_ 463 PM_systemStateCounter "PM ECU: system state counter";
CM_ SG_ 463 PM_systemStateChecksum "PM ECU: system state checksum";
CM_ BO_ 2038 "PM ECU message: vdc debug";
CM_ SG_ 2038 PM_vdcDebugSelector "PM ECU: vdc debug selector";
CM_ SG_ 2038 PM_VDCA_TCSlipTargetMod_RA_Fwd "PM ECU: VDCA TC slip target mod RA fwd";
CM_ SG_ 2038 PM_VDCA_TCSlipTargetMod_RA_Rwd "PM ECU: VDCA TC slip target mod RA rwd";
CM_ SG_ 2038 PM_VSE_forceY_RA "PM ECU: VSE force y RA";
CM_ SG_ 2038 PM_VDCT_observerSlipAngle_RA "PM ECU: VDCT observer slip angle RA";
CM_ SG_ 2038 PM_VSE_muVehicleFxLow "PM ECU: VSE mu vehicle fx low";
CM_ SG_ 2038 PM_VE_fxmFres "PM ECU: VE fxm fres";
CM_ SG_ 2038 PM_VE_fxAccelMass "PM ECU: VE fx accel mass";
CM_ SG_ 2038 PM_VE_vxDotGrade "PM ECU: VE vx dot grade";
CM_ SG_ 2038 PM_VE_betaEst "PM ECU: VE beta est";
CM_ SG_ 2038 PM_VSE_muVehicleFxHigh "PM ECU: VSE mu vehicle fx high";
CM_ SG_ 2038 PM_VSE_muVehicleDecLeakRate "PM ECU: VSE mu vehicle dec leak rate";
CM_ SG_ 2038 PM_VSE_muVehicleLearnDown "PM ECU: VSE mu vehicle learn down";
CM_ SG_ 2038 PM_VSE_muVehicleDecFilter "PM ECU: VSE mu vehicle dec filter";
CM_ SG_ 2038 PM_VSE_muVehicleLatDecLeakRate "PM ECU: VSE mu vehicle lat dec leak rate";
CM_ SG_ 2038 PM_VSE_splitMuProbability "PM ECU: VSE split mu probability";
CM_ SG_ 2038 PM_VSE_splitMuTotalMz "PM ECU: VSE split mu total mz";
CM_ SG_ 2038 PM_VSE_attitudeBankAngle "PM ECU: VSE attitude bank angle";
CM_ SG_ 2038 PM_VSE_attitudeDBetaInControl "PM ECU: VSE attitude d beta in control";
CM_ SG_ 2038 PM_VSE_roadWheelAngleAverage "PM ECU: VSE road wheel angle average";
CM_ BO_ 1766 "PNCD ECU message: iso tp pipe to cp";
CM_ SG_ 1766 PNCD_isoTpToCpData "PNCD ECU: iso tp to cp data";
CM_ BO_ 519 "Cabin heater message: feedback status";
CM_ SG_ 519 PTC_leftFlagFault "Heater left bank fault indication flag";
CM_ SG_ 519 PTC_rightFlagFault "Heater right bank fault indication flag";
CM_ SG_ 519 PTC_leftPowerDerating "Heater left bank power derating state";
CM_ SG_ 519 PTC_rightPowerDerating "Heater right bank power derating state";
CM_ SG_ 519 PTC_ocpEvent "Indication that an over current protection event has occurred";
CM_ SG_ 519 PTC_leftDutyFeedback "Current PWM duty cycle applied to left side of PTC heater";
CM_ SG_ 519 PTC_rightDutyFeedback "Current PWM duty cycle applied to right side of PTC heater";
CM_ SG_ 519 PTC_leftPowerHV "Heater left bank power";
CM_ SG_ 519 PTC_rightPowerHV "Heater right bank power";
CM_ SG_ 519 PTC_leftTempEstOutlet "Cabin heater: left temp est outlet";
CM_ SG_ 519 PTC_rightTempEstOutlet "Cabin heater: right temp est outlet";
CM_ SG_ 519 PTC_tliErrorCount "Heater top level interrupt error count";
CM_ SG_ 519 PTC_tliEvent "Indicator of heater top level interrupt event";
CM_ SG_ 519 PTC_tliSource "Heater top level interrupt event source";
CM_ BO_ 837 "Cabin heater message: info";
CM_ SG_ 837 PTC_infoIndex "Cabin heater: info index";
CM_ SG_ 837 PTC_infoBuildType "Cabin heater: info build type";
CM_ SG_ 837 PTC_infoBuildConfigId "Cabin heater: info build config id";
CM_ SG_ 837 PTC_infoHardwareId "Cabin heater: info hardware id";
CM_ SG_ 837 PTC_infoComponentId "Cabin heater: info component id";
CM_ SG_ 837 PTC_infoPcbaId "Cabin heater: info pcba id";
CM_ SG_ 837 PTC_infoAssemblyId "Cabin heater: info assembly id; raw 255 = signal not available (SNA)";
CM_ SG_ 837 PTC_infoUsageId "Cabin heater: info usage id";
CM_ SG_ 837 PTC_infoSubUsageId "Cabin heater: info sub usage id";
CM_ SG_ 837 PTC_infoPlatformType "Cabin heater: info platform type";
CM_ SG_ 837 PTC_infoAppCrc "Cabin heater: info app crc";
CM_ SG_ 837 PTC_infoBootUdsProtoVersion "Cabin heater: info boot uds proto version";
CM_ SG_ 837 PTC_infoBootCrc "Cabin heater: info boot crc";
CM_ BO_ 2019 "Cabin heater message: sensor status";
CM_ SG_ 2019 PTC_leftTempIGBT "Heater left bank IGBT temperature";
CM_ SG_ 2019 PTC_tempOCP "Temperature measured near the over current protection circuit";
CM_ SG_ 2019 PTC_rightTempIGBT "Heater right bank IGBT temperature";
CM_ SG_ 2019 PTC_tempPCB "Heater printed circuit board temperature";
CM_ SG_ 2019 PTC_voltageHV "Heater high voltage input voltage";
CM_ SG_ 2019 PTC_leftCurrentHV "Cabin heater: left current HV";
CM_ SG_ 2019 PTC_rightCurrentHV "Cabin heater: right current HV";
CM_ BO_ 1365 "Radar message: alert log";
CM_ SG_ 1365 RADC_alertID "Radar: alert ID";
CM_ SG_ 1365 RADC_alertState "Radar: alert state";
CM_ SG_ 1365 RADC_a002_ecuAdcErrType "Radar: a002 ecu adc err type";
CM_ SG_ 1365 RADC_a008_interLockErrType "Radar: a008 inter lock err type";
CM_ SG_ 1365 RADC_a011_ecuMcemErrType "Radar: a011 ecu mcem err type";
CM_ SG_ 1365 RADC_a013_ecuWdgErrType "Radar: a013 ecu wdg err type";
CM_ SG_ 1365 RADC_a016_adcOverVoltType "Radar: a016 adc over volt type";
CM_ SG_ 1365 RADC_a016_adcVoltage "Radar: a016 adc voltage";
CM_ SG_ 1365 RADC_a017_adcUnderVoltType "Radar: a017 adc under volt type";
CM_ SG_ 1365 RADC_a017_adcVoltage "Radar: a017 adc voltage";
CM_ SG_ 1365 RADC_a019_internalSWFaultType "Radar: a019 internal SW fault type";
CM_ SG_ 1365 RADC_a019_internalSWFaultCoreID "Radar: a019 internal SW fault core ID";
CM_ SG_ 1365 RADC_a020_ecuTemp "Radar: a020 ecu temp";
CM_ SG_ 1365 RADC_a023_ecuTemp "Radar: a023 ecu temp";
CM_ SG_ 1365 RADC_a025_ecuVoltage "Radar: a025 ecu voltage";
CM_ SG_ 1365 RADC_a026_ecuVoltage "Radar: a026 ecu voltage";
CM_ SG_ 1365 RADC_a027_nvmFailureType "Radar: a027 nvm failure type";
CM_ SG_ 1365 RADC_a028_rfComRegCheckFail "Radar: a028 rf com reg check fail";
CM_ SG_ 1365 RADC_a029_rhcChirpMonErrType "Radar: a029 rhc chirp mon err type";
CM_ SG_ 1365 RADC_a029_rhcRxLongTermErrType "Radar: a029 rhc rx long term err type";
CM_ SG_ 1365 RADC_a029_rhcRxErrType "Radar: a029 rhc rx err type";
CM_ SG_ 1365 RADC_a029_rhcVcoPowerErrType "Radar: a029 rhc vco power err type";
CM_ SG_ 1365 RADC_a029_rhcSp1ErrType "Radar: a029 rhc sp1 err type";
CM_ SG_ 1365 RADC_a029_rhcFdcErrType "Radar: a029 rhc fdc err type";
CM_ SG_ 1365 RADC_a030_rspErrType "Radar: a030 rsp err type";
CM_ SG_ 1365 RADC_a031_horizMisalignAngle "Radar: a031 horiz misalign angle";
CM_ SG_ 1365 RADC_a031_vertMisalignAngle "Radar: a031 vert misalign angle";
CM_ SG_ 1365 RADC_a032_blockageType "Radar: a032 blockage type";
CM_ SG_ 1365 RADC_a032_block_SPMBlockageState "Radar: a032 block SPM blockage state";
CM_ SG_ 1365 RADC_a032_block_dummy "Radar: a032 block dummy";
CM_ SG_ 1365 RADC_a032_block_SPMSelfTestState "Radar: a032 block SPM self test state";
CM_ SG_ 1365 RADC_a032_block_ucEstiRange "Radar: a032 block uc esti range";
CM_ SG_ 1365 RADC_a032_block_ucEstiRangeConf "Radar: a032 block uc esti range conf";
CM_ SG_ 1365 RADC_a032_block_ucEstiRangeProb "Radar: a032 block uc esti range prob";
CM_ SG_ 1365 RADC_a032_block_ucTimeoutBlkConf "Radar: a032 block uc timeout blk conf";
CM_ SG_ 1365 RADC_a035_msgId "Radar: a035 msg id";
CM_ SG_ 1365 RADC_a036_msgId "Radar: a036 msg id";
CM_ SG_ 1365 RADC_a037_msgId "Radar: a037 msg id";
CM_ SG_ 1365 RADC_a038_msgId "Radar: a038 msg id";
CM_ SG_ 1365 RADC_a039_msgId "Radar: a039 msg id";
CM_ SG_ 1365 RADC_a040_msgId "Radar: a040 msg id";
CM_ SG_ 1365 RADC_a041_vinErrType "Radar: a041 vin err type";
CM_ SG_ 1365 RADC_a041_vinErrExp "Radar: a041 vin err exp";
CM_ SG_ 1365 RADC_a041_vinErrRx "Radar: a041 vin err rx";
CM_ SG_ 1365 RADC_a041_msgId "Radar: a041 msg id";
CM_ SG_ 1365 RADC_a042_carConfigErrType "Radar: a042 car config err type";
CM_ SG_ 1365 RADC_a042_carConfigErrExp "Radar: a042 car config err exp";
CM_ SG_ 1365 RADC_a042_carConfigErrRx "Radar: a042 car config err rx";
CM_ SG_ 1365 RADC_a042_msgId "Radar: a042 msg id";
CM_ SG_ 1365 RADC_a043_inertialSignalsErrType "Radar: a043 inertial signals err type";
CM_ SG_ 1365 RADC_a043_inertialSignalsErrExp "Radar: a043 inertial signals err exp";
CM_ SG_ 1365 RADC_a043_inertialSignalsErrRx "Radar: a043 inertial signals err rx";
CM_ SG_ 1365 RADC_a043_msgId "Radar: a043 msg id";
CM_ SG_ 1365 RADC_a044_stwAngleErrType "Radar: a044 stw angle err type";
CM_ SG_ 1365 RADC_a044_stwAngleErrExp "Radar: a044 stw angle err exp";
CM_ SG_ 1365 RADC_a044_stwAngleErrRx "Radar: a044 stw angle err rx";
CM_ SG_ 1365 RADC_a044_msgId "Radar: a044 msg id";
CM_ SG_ 1365 RADC_a045_vehicleStateErrType "Radar: a045 vehicle state err type";
CM_ SG_ 1365 RADC_a045_vehicleStateErrExp "Radar: a045 vehicle state err exp";
CM_ SG_ 1365 RADC_a045_vehicleStateErrRx "Radar: a045 vehicle state err rx";
CM_ SG_ 1365 RADC_a045_msgId "Radar: a045 msg id";
CM_ SG_ 1365 RADC_a046_wheelSpeedsErrType "Radar: a046 wheel speeds err type";
CM_ SG_ 1365 RADC_a046_wheelSpeedsErrExp "Radar: a046 wheel speeds err exp";
CM_ SG_ 1365 RADC_a046_wheelSpeedsErrRx "Radar: a046 wheel speeds err rx";
CM_ SG_ 1365 RADC_a046_msgId "Radar: a046 msg id";
CM_ SG_ 1365 RADC_a047_chassisTypeExp "Radar: a047 chassis type exp; raw 7 = signal not available (SNA)";
CM_ SG_ 1365 RADC_a047_chassisTypeRx "Radar: a047 chassis type rx; raw 7 = signal not available (SNA)";
CM_ SG_ 1365 RADC_a048_airSuspensionExp "Radar: a048 air suspension exp; raw 7 = signal not available (SNA)";
CM_ SG_ 1365 RADC_a048_airSuspensionRx "Radar: a048 air suspension rx; raw 7 = signal not available (SNA)";
CM_ SG_ 1365 RADC_a049_fourWheelDriveExp "Radar: a049 four wheel drive exp; raw 3 = signal not available (SNA)";
CM_ SG_ 1365 RADC_a049_fourWheelDriveRx "Radar: a049 four wheel drive rx; raw 3 = signal not available (SNA)";
CM_ SG_ 1365 RADC_a050_countryExp "Radar: a050 country exp";
CM_ SG_ 1365 RADC_a050_countryRx "Radar: a050 country rx";
CM_ SG_ 1365 RADC_a051_epasTypeExp "Radar: a051 epas type exp; raw 7 = signal not available (SNA)";
CM_ SG_ 1365 RADC_a051_epasTypeRx "Radar: a051 epas type rx; raw 7 = signal not available (SNA)";
CM_ SG_ 1365 RADC_a052_radarPositionExp "Radar: a052 radar position exp; raw 7 = signal not available (SNA)";
CM_ SG_ 1365 RADC_a052_radarPositionRx "Radar: a052 radar position rx; raw 7 = signal not available (SNA)";
CM_ SG_ 1365 RADC_a054_block_ucObjLossProb "Radar: a054 block uc obj loss prob";
CM_ SG_ 1365 RADC_a054_block_ucObjLossConf "Radar: a054 block uc obj loss conf";
CM_ SG_ 1365 RADC_a054_block_ucOverallProb "Radar: a054 block uc overall prob";
CM_ SG_ 1365 RADC_a054_block_ucOverallConf "Radar: a054 block uc overall conf";
CM_ SG_ 1365 RADC_a054_block_RoadbeamTimeCnt "Radar: a054 block roadbeam time cnt";
CM_ SG_ 1365 RADC_a055_block_usTimeoutWayCnt "Radar: a055 block us timeout way cnt";
CM_ SG_ 1365 RADC_a055_block_ucTimeoutTimeCnt "Radar: a055 block uc timeout time cnt";
CM_ SG_ 1365 RADC_a055_bblock_ucTimeoutBlkPro "Radar: a055 bblock uc timeout blk prob";
CM_ SG_ 1365 RADC_a055_block_usFullBlkTimer "Radar: a055 block us full blk timer";
CM_ BO_ 1282 "Radar message: alert matrix0";
CM_ SG_ 1282 RADC_a001_can1BusOff "Radar: a001 can1 bus off";
CM_ SG_ 1282 RADC_a002_ecuAdcError "Radar: a002 ecu adc error";
CM_ SG_ 1282 RADC_a003_ecuBistDisabled "Radar: a003 ecu bist disabled";
CM_ SG_ 1282 RADC_a004_ecuCrcHwError "Radar: a004 ecu crc hw error";
CM_ SG_ 1282 RADC_a005_ecuEcuMError "Radar: a005 ecu ecu m error";
CM_ SG_ 1282 RADC_a006_ecuFimError "Radar: a006 ecu fim error";
CM_ SG_ 1282 RADC_a007_ecuGptCheckError "Radar: a007 ecu gpt check error";
CM_ SG_ 1282 RADC_a008_ecuHwSwInterlock "Radar: a008 ecu hw sw interlock";
CM_ SG_ 1282 RADC_a009_plantModeActive "Radar: a009 plant mode active";
CM_ SG_ 1282 RADC_a010_ecuIoHwAbError "Radar: a010 ecu io hw ab error";
CM_ SG_ 1282 RADC_a011_ecuMcemError "Radar: a011 ecu mcem error";
CM_ SG_ 1282 RADC_a012_ecuSpiError "Radar: a012 ecu spi error";
CM_ SG_ 1282 RADC_a013_ecuWdgError "Radar: a013 ecu wdg error";
CM_ SG_ 1282 RADC_a014_fctSelfTestNotDone "Radar: a014 fct self test not done";
CM_ SG_ 1282 RADC_a015_fctSenInterference "Radar: a015 fct sen interference";
CM_ SG_ 1282 RADC_a016_adcOverVolt "Radar: a016 adc over volt";
CM_ SG_ 1282 RADC_a017_adcUnderVolt "Radar: a017 adc under volt";
CM_ SG_ 1282 RADC_a018_internalHardwareFault "Radar: a018 internal hardware fault";
CM_ SG_ 1282 RADC_a019_internalSoftwareFault "Radar: a019 internal software fault";
CM_ SG_ 1282 RADC_a020_overTemp "Radar: a020 over temp";
CM_ SG_ 1282 RADC_a021_overTempCrit "Radar: a021 over temp crit";
CM_ SG_ 1282 RADC_a022_tempImplausible "Radar: a022 temp implausible";
CM_ SG_ 1282 RADC_a023_underTemp "Radar: a023 under temp";
CM_ SG_ 1282 RADC_a024_underTempCrit "Radar: a024 under temp crit";
CM_ SG_ 1282 RADC_a025_overVoltage "Radar: a025 over voltage";
CM_ SG_ 1282 RADC_a026_underVoltage "Radar: a026 under voltage";
CM_ SG_ 1282 RADC_a027_nvmFailure "Radar: a027 nvm failure";
CM_ SG_ 1282 RADC_a028_rfChipError "Radar: a028 rf chip error";
CM_ SG_ 1282 RADC_a029_rhcError "Radar: a029 rhc error";
CM_ SG_ 1282 RADC_a030_rspError "Radar: a030 rsp error";
CM_ SG_ 1282 RADC_a031_sensorMisaligned "Radar: a031 sensor misaligned";
CM_ SG_ 1282 RADC_a032_sensorBlocked "Radar: a032 sensor blocked";
CM_ SG_ 1282 RADC_a033_sensorNeverAligned "Radar: a033 sensor never aligned";
CM_ SG_ 1282 RADC_a034_vehDynamicsError "Radar: a034 veh dynamics error";
CM_ SG_ 1282 RADC_a035_vinMIA "Radar: a035 vin MIA";
CM_ SG_ 1282 RADC_a036_carConfigMIA "Radar: a036 car config MIA";
CM_ SG_ 1282 RADC_a037_inertialSignalsMIA "Radar: a037 inertial signals MIA";
CM_ SG_ 1282 RADC_a038_steeringWheelAngleMIA "Radar: a038 steering wheel angle MIA";
CM_ SG_ 1282 RADC_a039_vehicleStateMIA "Radar: a039 vehicle state MIA";
CM_ SG_ 1282 RADC_a040_wheelSpeedsMIA "Radar: a040 wheel speeds MIA";
CM_ SG_ 1282 RADC_a041_vinErr "Radar: a041 vin err";
CM_ SG_ 1282 RADC_a042_carConfigErr "Radar: a042 car config err";
CM_ SG_ 1282 RADC_a043_inertialSignalsErr "Radar: a043 inertial signals err";
CM_ SG_ 1282 RADC_a044_steeringWheelAngleErr "Radar: a044 steering wheel angle err";
CM_ SG_ 1282 RADC_a045_vehicleStateErr "Radar: a045 vehicle state err";
CM_ SG_ 1282 RADC_a046_wheelSpeedsErr "Radar: a046 wheel speeds err";
CM_ SG_ 1282 RADC_a047_mismatchChassisType "Radar: a047 mismatch chassis type";
CM_ SG_ 1282 RADC_a048_mismatchAirSuspension "Radar: a048 mismatch air suspension";
CM_ SG_ 1282 RADC_a049_mismatchFourWheelDrive "Radar: a049 mismatch four wheel drive";
CM_ SG_ 1282 RADC_a050_mismatchCountry "Radar: a050 mismatch country";
CM_ SG_ 1282 RADC_a051_mismatchEPASType "Radar: a051 mismatch EPAS type";
CM_ SG_ 1282 RADC_a052_mismatcRadPos "Radar: a052 mismatc rad pos";
CM_ SG_ 1282 RADC_a053_emError "Radar: a053 em error";
CM_ SG_ 1282 RADC_a054_blockageInfo_Frame_1 "Radar: a054 blockage info frame 1";
CM_ SG_ 1282 RADC_a055_blockageInfo_Frame_2 "Radar: a055 blockage info frame 2";
CM_ BO_ 1329 "Radar message: info";
CM_ SG_ 1329 RADC_infoIndex "Radar: info index";
CM_ SG_ 1329 RADC_infoBuildType "Radar: info build type";
CM_ SG_ 1329 RADC_infoBuildConfigID "Radar: info build config ID";
CM_ SG_ 1329 RADC_infoHardwareID "Radar: info hardware ID";
CM_ SG_ 1329 RADC_infoComponentID "Radar: info component ID";
CM_ SG_ 1329 RADC_infoPcbaID "Radar: info pcba ID";
CM_ SG_ 1329 RADC_infoAssemblyID "Radar: info assembly ID";
CM_ SG_ 1329 RADC_infoUsageID "Radar: info usage ID";
CM_ SG_ 1329 RADC_infoSubUsageID "Radar: info sub usage ID";
CM_ SG_ 1329 RADC_infoApplicationCRC "Radar: info application CRC";
CM_ SG_ 1329 RADC_infoPlatformType "Radar: info platform type";
CM_ SG_ 1329 RADC_infoMajorVersion "Radar: info major version";
CM_ SG_ 1329 RADC_infoBranchOrigin "Radar: info branch origin";
CM_ SG_ 1329 RADC_infoMaturity "Radar: info maturity";
CM_ SG_ 1329 RADC_infoHardwareRevision "Radar: info hardware revision";
CM_ SG_ 1329 RADC_infoBootUdsProtoVersion "Radar: info boot uds proto version";
CM_ SG_ 1329 RADC_infoBootloaderCRC "Radar: info bootloader CRC";
CM_ BO_ 1249 "RCM2 ECU message: alert log";
CM_ SG_ 1249 RCM2_alertID "RCM2 ECU: alert ID";
CM_ SG_ 1249 RCM2_alertState "RCM2 ECU: alert state";
CM_ SG_ 1249 RCM2_eventArmStatus "RCM2 ECU: event arm status";
CM_ SG_ 1249 RCM2_eventFactoryMode "RCM2 ECU: event factory mode";
CM_ SG_ 1249 RCM2_eventDriveOrientation "RCM2 ECU: event drive orientation";
CM_ SG_ 1249 RCM2_eventIDFsignal "RCM2 ECU: event ID fsignal";
CM_ SG_ 1249 RCM2_eventFrontLeftSeatbelt "RCM2 ECU: event front left seatbelt";
CM_ SG_ 1249 RCM2_eventFrontRightSeatbelt "RCM2 ECU: event front right seatbelt";
CM_ SG_ 1249 RCM2_eventVehicleSpeed "RCM2 ECU: event vehicle speed";
CM_ SG_ 1249 RCM2_eventDriverBrakeApply "RCM2 ECU: event driver brake apply; raw 3 = signal not available (SNA)";
CM_ SG_ 1249 RCM2_eventAccelPedalPos "RCM2 ECU: event accel pedal pos; raw 255 = signal not available (SNA)";
CM_ SG_ 1249 RCM2_a000_crashDetectedStaticRol "RCM2 ECU: a000 crash detected static roll";
CM_ SG_ 1249 RCM2_a000_crashDetectedPitch "RCM2 ECU: a000 crash detected pitch";
CM_ SG_ 1249 RCM2_a000_crashDetectedFront "RCM2 ECU: a000 crash detected front";
CM_ SG_ 1249 RCM2_a000_crashDetectedRear "RCM2 ECU: a000 crash detected rear";
CM_ SG_ 1249 RCM2_a000_crashDetectedLeft "RCM2 ECU: a000 crash detected left";
CM_ SG_ 1249 RCM2_a000_crashDetectedRight "RCM2 ECU: a000 crash detected right";
CM_ SG_ 1249 RCM2_a000_crashDetectedRoll "RCM2 ECU: a000 crash detected roll";
CM_ SG_ 1249 RCM2_a000_crashDetectedPreten "RCM2 ECU: a000 crash detected preten";
CM_ SG_ 1249 RCM2_a000_crashDetectedStage1 "RCM2 ECU: a000 crash detected stage1";
CM_ SG_ 1249 RCM2_a000_crashDetectedStage2 "RCM2 ECU: a000 crash detected stage2";
CM_ SG_ 1249 RCM2_a000_crashDetectedHVpyro "RCM2 ECU: a000 crash detected h vpyro";
CM_ SG_ 1249 RCM2_a000_crashDetectedOffZone "RCM2 ECU: a000 crash detected off zone";
CM_ SG_ 1249 RCM2_a001_nearDeployFront "RCM2 ECU: a001 near deploy front";
CM_ SG_ 1249 RCM2_a001_nearDeployRear "RCM2 ECU: a001 near deploy rear";
CM_ SG_ 1249 RCM2_a001_nearDeployLeft "RCM2 ECU: a001 near deploy left";
CM_ SG_ 1249 RCM2_a001_nearDeployRight "RCM2 ECU: a001 near deploy right";
CM_ SG_ 1249 RCM2_a001_nearDeployRoll "RCM2 ECU: a001 near deploy roll";
CM_ SG_ 1249 RCM2_a002_airbagsUnArmed_s "RCM2 ECU: a002 airbags un armed s";
CM_ SG_ 1249 RCM2_a003_warningIndicator_s "RCM2 ECU: a003 warning indicator s";
CM_ SG_ 1249 RCM2_a004_crashAlgoWakeup_s "RCM2 ECU: a004 crash algo wakeup s";
CM_ SG_ 1249 RCM2_a004_crashAlgoWakeupFront "RCM2 ECU: a004 crash algo wakeup front";
CM_ SG_ 1249 RCM2_a004_crashAlgoWakeupSide "RCM2 ECU: a004 crash algo wakeup side";
CM_ SG_ 1249 RCM2_a004_crashAlgoWakeupRear "RCM2 ECU: a004 crash algo wakeup rear";
CM_ SG_ 1249 RCM2_a004_crashAlgoWakeupRoll "RCM2 ECU: a004 crash algo wakeup roll";
CM_ SG_ 1249 RCM2_a004_crashAlgoWakeupPedPro "RCM2 ECU: a004 crash algo wakeup ped pro";
CM_ SG_ 1249 RCM2_a004_crashAlgoWakeupOffZone "RCM2 ECU: a004 crash algo wakeup off zone";
CM_ SG_ 1249 RCM2_a005_abuseImmunityThrshold_ "RCM2 ECU: a005 abuse immunity thrshold s";
CM_ SG_ 1249 RCM2_a007_pedProCrashDetected_s "RCM2 ECU: a007 ped pro crash detected s";
CM_ SG_ 1249 RCM2_a008_factoryMode_s "RCM2 ECU: a008 factory mode s";
CM_ SG_ 1249 RCM2_a009_edrDataAreaLocked_s "RCM2 ECU: a009 edr data area locked s";
CM_ SG_ 1249 RCM2_a010_pedProEDRDataLocked_s "RCM2 ECU: a010 ped pro EDR data locked s";
CM_ SG_ 1249 RCM2_a014_pedProNearDeploy_s "RCM2 ECU: a014 ped pro near deploy s";
CM_ SG_ 1249 RCM2_a015_noDeployCrashCal_s "RCM2 ECU: a015 no deploy crash cal s";
CM_ SG_ 1249 RCM2_a016_noDeployPedProCal_s "RCM2 ECU: a016 no deploy ped pro cal s";
CM_ SG_ 1249 RCM2_a047_batteryESRhigh_s "RCM2 ECU: a047 battery ES rhigh s";
CM_ SG_ 1249 RCM2_a048_batteryVoltageTooHigh_ "RCM2 ECU: a048 battery voltage too high s";
CM_ SG_ 1249 RCM2_a049_batteryVoltageTooLow_s "RCM2 ECU: a049 battery voltage too low s";
CM_ SG_ 1249 RCM2_a050_driverABStg1Sht2Gnd_s "RCM2 ECU: a050 driver AB stg1 sht2 gnd s";
CM_ SG_ 1249 RCM2_a051_driverABStg1Sht2Bat_s "RCM2 ECU: a051 driver AB stg1 sht2 bat s";
CM_ SG_ 1249 RCM2_a052_driverABStg1Open_s "RCM2 ECU: a052 driver AB stg1 open s";
CM_ SG_ 1249 RCM2_a053_driverABStg1Short_s "RCM2 ECU: a053 driver AB stg1 short s";
CM_ SG_ 1249 RCM2_a054_driverABStg1CrssCoup_s "RCM2 ECU: a054 driver AB stg1 crss coup s";
CM_ SG_ 1249 RCM2_a055_driverABStg1Config_s "RCM2 ECU: a055 driver AB stg1 config s";
CM_ SG_ 1249 RCM2_a056_driverABStg2Sht2Gnd_s "RCM2 ECU: a056 driver AB stg2 sht2 gnd s";
CM_ SG_ 1249 RCM2_a057_driverABStg2Sht2Bat_s "RCM2 ECU: a057 driver AB stg2 sht2 bat s";
CM_ SG_ 1249 RCM2_a058_driverABStg2Open_s "RCM2 ECU: a058 driver AB stg2 open s";
CM_ SG_ 1249 RCM2_a059_driverABStg2Short_s "RCM2 ECU: a059 driver AB stg2 short s";
CM_ SG_ 1249 RCM2_a060_driverABStg2CrssCoup_s "RCM2 ECU: a060 driver AB stg2 crss coup s";
CM_ SG_ 1249 RCM2_a061_driverABStg2Config_s "RCM2 ECU: a061 driver AB stg2 config s";
CM_ SG_ 1249 RCM2_a062_passABStg1Sht2Gnd_s "RCM2 ECU: a062 pass AB stg1 sht2 gnd s";
CM_ SG_ 1249 RCM2_a063_passABStg1Sht2Bat_s "RCM2 ECU: a063 pass AB stg1 sht2 bat s";
CM_ SG_ 1249 RCM2_a064_passABStg1Open_s "RCM2 ECU: a064 pass AB stg1 open s";
CM_ SG_ 1249 RCM2_a065_passABStg1Short_s "RCM2 ECU: a065 pass AB stg1 short s";
CM_ SG_ 1249 RCM2_a066_passABStg1CrssCoup_s "RCM2 ECU: a066 pass AB stg1 crss coup s";
CM_ SG_ 1249 RCM2_a067_passABStg1Config_s "RCM2 ECU: a067 pass AB stg1 config s";
CM_ SG_ 1249 RCM2_a068_passABStg2Sht2Gnd_s "RCM2 ECU: a068 pass AB stg2 sht2 gnd s";
CM_ SG_ 1249 RCM2_a069_passABStg2Sht2Bat_s "RCM2 ECU: a069 pass AB stg2 sht2 bat s";
CM_ SG_ 1249 RCM2_a070_passABStg2Open_s "RCM2 ECU: a070 pass AB stg2 open s";
CM_ SG_ 1249 RCM2_a071_passABStg2Short_s "RCM2 ECU: a071 pass AB stg2 short s";
CM_ SG_ 1249 RCM2_a072_passABStg2CrssCoup_s "RCM2 ECU: a072 pass AB stg2 crss coup s";
CM_ SG_ 1249 RCM2_a073_passABStg2Config_s "RCM2 ECU: a073 pass AB stg2 config s";
CM_ SG_ 1249 RCM2_a074_passActiveVentSht2Gnd_ "RCM2 ECU: a074 pass active vent sht2 gnd s";
CM_ SG_ 1249 RCM2_a075_passActiveVentSht2Bat_ "RCM2 ECU: a075 pass active vent sht2 bat s";
CM_ SG_ 1249 RCM2_a076_passActiveVentOpen_s "RCM2 ECU: a076 pass active vent open s";
CM_ SG_ 1249 RCM2_a077_passActiveVentShort_s "RCM2 ECU: a077 pass active vent short s";
CM_ SG_ 1249 RCM2_a078_passActiveVentCrssCoup "RCM2 ECU: a078 pass active vent crss coup s";
CM_ SG_ 1249 RCM2_a079_passActiveVentConfig_s "RCM2 ECU: a079 pass active vent config s";
CM_ SG_ 1249 RCM2_a080_pretenShldLeftSht2Gnd_ "RCM2 ECU: a080 preten shld left sht2 gnd s";
CM_ SG_ 1249 RCM2_a081_pretenShldLeftSht2Bat_ "RCM2 ECU: a081 preten shld left sht2 bat s";
CM_ SG_ 1249 RCM2_a082_pretenShldLeftOpen_s "RCM2 ECU: a082 preten shld left open s";
CM_ SG_ 1249 RCM2_a083_pretenShldLeftShort_s "RCM2 ECU: a083 preten shld left short s";
CM_ SG_ 1249 RCM2_a084_pretenShldLeftCrossC_s "RCM2 ECU: a084 preten shld left cross c s";
CM_ SG_ 1249 RCM2_a085_pretenShldLeftConfig_s "RCM2 ECU: a085 preten shld left config s";
CM_ SG_ 1249 RCM2_a086_pretenShldRightSht2Gnd "RCM2 ECU: a086 preten shld right sht2 gnd s";
CM_ SG_ 1249 RCM2_a087_pretenShldRightSht2Bat "RCM2 ECU: a087 preten shld right sht2 bat s";
CM_ SG_ 1249 RCM2_a088_pretenShldRightOpen_s "RCM2 ECU: a088 preten shld right open s";
CM_ SG_ 1249 RCM2_a089_pretenShldRightShort_s "RCM2 ECU: a089 preten shld right short s";
CM_ SG_ 1249 RCM2_a090_pretenShldRightCrssCou "RCM2 ECU: a090 preten shld right crss cou s";
CM_ SG_ 1249 RCM2_a091_pretenShldRightConfig_ "RCM2 ECU: a091 preten shld right config s";
CM_ SG_ 1249 RCM2_a092_pretenLapLeftSht2Gnd_s "RCM2 ECU: a092 preten lap left sht2 gnd s";
CM_ SG_ 1249 RCM2_a093_pretenLapLeftSht2Bat_s "RCM2 ECU: a093 preten lap left sht2 bat s";
CM_ SG_ 1249 RCM2_a094_pretenLapLeftOpen_s "RCM2 ECU: a094 preten lap left open s";
CM_ SG_ 1249 RCM2_a095_pretenLapLeftShort_s "RCM2 ECU: a095 preten lap left short s";
CM_ SG_ 1249 RCM2_a096_pretenLapLeftCrssCoup_ "RCM2 ECU: a096 preten lap left crss coup s";
CM_ SG_ 1249 RCM2_a097_pretenLapLeftConfig_s "RCM2 ECU: a097 preten lap left config s";
CM_ SG_ 1249 RCM2_a098_pretenLapRightSht2Gnd_ "RCM2 ECU: a098 preten lap right sht2 gnd s";
CM_ SG_ 1249 RCM2_a099_pretenLapRightSht2Bat_ "RCM2 ECU: a099 preten lap right sht2 bat s";
CM_ SG_ 1249 RCM2_a100_pretenLapRightOpen_s "RCM2 ECU: a100 preten lap right open s";
CM_ SG_ 1249 RCM2_a101_pretenLapRightShort_s "RCM2 ECU: a101 preten lap right short s";
CM_ SG_ 1249 RCM2_a102_pretenLapRightCrssCoup "RCM2 ECU: a102 preten lap right crss coup s";
CM_ SG_ 1249 RCM2_a103_pretenLapRightConfig_s "RCM2 ECU: a103 preten lap right config s";
CM_ SG_ 1249 RCM2_a104_loadLimLeftSht2Gnd_s "RCM2 ECU: a104 load lim left sht2 gnd s";
CM_ SG_ 1249 RCM2_a105_loadLimLeftSht2Bat_s "RCM2 ECU: a105 load lim left sht2 bat s";
CM_ SG_ 1249 RCM2_a106_loadLimLeftOpen_s "RCM2 ECU: a106 load lim left open s";
CM_ SG_ 1249 RCM2_a107_loadLimLeftShort_s "RCM2 ECU: a107 load lim left short s";
CM_ SG_ 1249 RCM2_a108_loadLimLeftCrssCoup_s "RCM2 ECU: a108 load lim left crss coup s";
CM_ SG_ 1249 RCM2_a110_loadLimRightSht2Gnd_s "RCM2 ECU: a110 load lim right sht2 gnd s";
CM_ SG_ 1249 RCM2_a111_loadLimRightSht2Bat_s "RCM2 ECU: a111 load lim right sht2 bat s";
CM_ SG_ 1249 RCM2_a112_loadLimRightOpen_s "RCM2 ECU: a112 load lim right open s";
CM_ SG_ 1249 RCM2_a113_loadLimRightShort_s "RCM2 ECU: a113 load lim right short s";
CM_ SG_ 1249 RCM2_a114_loadLimRightCrssCoup_s "RCM2 ECU: a114 load lim right crss coup s";
CM_ SG_ 1249 RCM2_a115_loadLimRightConfig_s "RCM2 ECU: a115 load lim right config s";
CM_ SG_ 1249 RCM2_a116_kneeABDrvrSht2Gnd_s "RCM2 ECU: a116 knee AB drvr sht2 gnd s";
CM_ SG_ 1249 RCM2_a117_kneeABDrvrSht2Bat_s "RCM2 ECU: a117 knee AB drvr sht2 bat s";
CM_ SG_ 1249 RCM2_a118_kneeABDrvrOpen_s "RCM2 ECU: a118 knee AB drvr open s";
CM_ SG_ 1249 RCM2_a119_kneeABDrvrShort_s "RCM2 ECU: a119 knee AB drvr short s";
CM_ SG_ 1249 RCM2_a120_kneeABDrvrCrssCoup_s "RCM2 ECU: a120 knee AB drvr crss coup s";
CM_ SG_ 1249 RCM2_a122_kneeABPassSht2Gnd_s "RCM2 ECU: a122 knee AB pass sht2 gnd s";
CM_ SG_ 1249 RCM2_a123_kneeABPassSht2Bat_s "RCM2 ECU: a123 knee AB pass sht2 bat s";
CM_ SG_ 1249 RCM2_a124_kneeABPassOpen_s "RCM2 ECU: a124 knee AB pass open s";
CM_ SG_ 1249 RCM2_a125_kneeABPassShort_s "RCM2 ECU: a125 knee AB pass short s";
CM_ SG_ 1249 RCM2_a126_kneeABPassCrssCoup_s "RCM2 ECU: a126 knee AB pass crss coup s";
CM_ SG_ 1249 RCM2_a127_kneeABPassConfig_s "RCM2 ECU: a127 knee AB pass config s";
CM_ SG_ 1249 RCM2_a128_sideAB1stRowLSht2Gnd_s "RCM2 ECU: a128 side ab1st row l sht2 gnd s";
CM_ SG_ 1249 RCM2_a129_sideAB1stRowLSht2Bat_s "RCM2 ECU: a129 side ab1st row l sht2 bat s";
CM_ SG_ 1249 RCM2_a130_sideAB1stRowLOpen_s "RCM2 ECU: a130 side ab1st row l open s";
CM_ SG_ 1249 RCM2_a131_sideAB1stRowLShort_s "RCM2 ECU: a131 side ab1st row l short s";
CM_ SG_ 1249 RCM2_a132_sideAB1stRowLCrssCoup_ "RCM2 ECU: a132 side ab1st row l crss coup s";
CM_ SG_ 1249 RCM2_a134_sideAB1stRowRSht2Gnd_s "RCM2 ECU: a134 side ab1st row r sht2 gnd s";
CM_ SG_ 1249 RCM2_a135_sideAB1stRowRSht2Bat_s "RCM2 ECU: a135 side ab1st row r sht2 bat s";
CM_ SG_ 1249 RCM2_a136_sideAB1stRowROpen_s "RCM2 ECU: a136 side ab1st row r open s";
CM_ SG_ 1249 RCM2_a137_sideAB1stRowRShort_s "RCM2 ECU: a137 side ab1st row r short s";
CM_ SG_ 1249 RCM2_a138_sideAB1stRowRCrssCoup_ "RCM2 ECU: a138 side ab1st row r crss coup s";
CM_ SG_ 1249 RCM2_a140_hvdPyroSht2Gnd_s "RCM2 ECU: a140 hvd pyro sht2 gnd s";
CM_ SG_ 1249 RCM2_a141_hvdPyroSht2Bat_s "RCM2 ECU: a141 hvd pyro sht2 bat s";
CM_ SG_ 1249 RCM2_a142_hvdPyroOpen_s "RCM2 ECU: a142 hvd pyro open s";
CM_ SG_ 1249 RCM2_a143_hvdPyroShort_s "RCM2 ECU: a143 hvd pyro short s";
CM_ SG_ 1249 RCM2_a144_hvdPyroCrssCoup_s "RCM2 ECU: a144 hvd pyro crss coup s";
CM_ SG_ 1249 RCM2_a145_hvdPyroConfig_s "RCM2 ECU: a145 hvd pyro config s";
CM_ SG_ 1249 RCM2_a146_curABLeftSht2Gnd_s "RCM2 ECU: a146 cur AB left sht2 gnd s";
CM_ SG_ 1249 RCM2_a147_curABLeftSht2Bat_s "RCM2 ECU: a147 cur AB left sht2 bat s";
CM_ SG_ 1249 RCM2_a148_curABLeftOpen_s "RCM2 ECU: a148 cur AB left open s";
CM_ SG_ 1249 RCM2_a149_curABLeftShort_s "RCM2 ECU: a149 cur AB left short s";
CM_ SG_ 1249 RCM2_a150_curABLeftCrssCoup_s "RCM2 ECU: a150 cur AB left crss coup s";
CM_ SG_ 1249 RCM2_a152_curABRightSht2Gnd_s "RCM2 ECU: a152 cur AB right sht2 gnd s";
CM_ SG_ 1249 RCM2_a153_curABRightSht2Bat_s "RCM2 ECU: a153 cur AB right sht2 bat s";
CM_ SG_ 1249 RCM2_a154_curABRightOpen_s "RCM2 ECU: a154 cur AB right open s";
CM_ SG_ 1249 RCM2_a155_curABRightShort_s "RCM2 ECU: a155 cur AB right short s";
CM_ SG_ 1249 RCM2_a156_curABRightCrssCoup_s "RCM2 ECU: a156 cur AB right crss coup s";
CM_ SG_ 1249 RCM2_a158_preten2ndRowLSht2Gnd_s "RCM2 ECU: a158 preten2nd row l sht2 gnd s";
CM_ SG_ 1249 RCM2_a159_preten2ndRowLSht2Bat_s "RCM2 ECU: a159 preten2nd row l sht2 bat s";
CM_ SG_ 1249 RCM2_a160_preten2ndRowLOpen_s "RCM2 ECU: a160 preten2nd row l open s";
CM_ SG_ 1249 RCM2_a161_preten2ndRowLShort_s "RCM2 ECU: a161 preten2nd row l short s";
CM_ SG_ 1249 RCM2_a162_preten2ndRowLCrssCoup_ "RCM2 ECU: a162 preten2nd row l crss coup s";
CM_ SG_ 1249 RCM2_a163_preten2ndRowLCgf_s "RCM2 ECU: a163 preten2nd row l cgf s";
CM_ SG_ 1249 RCM2_a164_preten2ndRowRSht2Gnd_s "RCM2 ECU: a164 preten2nd row r sht2 gnd s";
CM_ SG_ 1249 RCM2_a165_preten2ndRowRSht2Bat_s "RCM2 ECU: a165 preten2nd row r sht2 bat s";
CM_ SG_ 1249 RCM2_a166_preten2ndRowROpen_s "RCM2 ECU: a166 preten2nd row r open s";
CM_ SG_ 1249 RCM2_a167_preten2ndRowRShort_s "RCM2 ECU: a167 preten2nd row r short s";
CM_ SG_ 1249 RCM2_a168_preten2ndRowRCrssCoup_ "RCM2 ECU: a168 preten2nd row r crss coup s";
CM_ SG_ 1249 RCM2_a169_preten2ndRowRCgf_s "RCM2 ECU: a169 preten2nd row r cgf s";
CM_ SG_ 1249 RCM2_a170_curAB2ndRowLSht2Gnd_s "RCM2 ECU: a170 cur ab2nd row l sht2 gnd s";
CM_ SG_ 1249 RCM2_a171_curAB2ndRowLSht2Bat_s "RCM2 ECU: a171 cur ab2nd row l sht2 bat s";
CM_ SG_ 1249 RCM2_a172_curAB2ndRowLOpen_s "RCM2 ECU: a172 cur ab2nd row l open s";
CM_ SG_ 1249 RCM2_a173_curAB2ndRowLShort_s "RCM2 ECU: a173 cur ab2nd row l short s";
CM_ SG_ 1249 RCM2_a174_curAB2ndRowLCrssCoup_s "RCM2 ECU: a174 cur ab2nd row l crss coup s";
CM_ SG_ 1249 RCM2_a175_curAB2ndRowLConfig_s "RCM2 ECU: a175 cur ab2nd row l config s";
CM_ SG_ 1249 RCM2_a176_curAB2ndRowRSht2Gnd_s "RCM2 ECU: a176 cur ab2nd row r sht2 gnd s";
CM_ SG_ 1249 RCM2_a177_curAB2ndRowRSht2Bat_s "RCM2 ECU: a177 cur ab2nd row r sht2 bat s";
CM_ SG_ 1249 RCM2_a178_curAB2ndRowROpen_s "RCM2 ECU: a178 cur ab2nd row r open s";
CM_ SG_ 1249 RCM2_a179_curAB2ndRowRShort_s "RCM2 ECU: a179 cur ab2nd row r short s";
CM_ SG_ 1249 RCM2_a180_curAB2ndRowRCrssCoup_s "RCM2 ECU: a180 cur ab2nd row r crss coup s";
CM_ SG_ 1249 RCM2_a181_curAB2ndRowRConfig_s "RCM2 ECU: a181 cur ab2nd row r config s";
CM_ SG_ 1249 RCM2_a182_hoodActuatorRSht2Gnd_s "RCM2 ECU: a182 hood actuator r sht2 gnd s";
CM_ SG_ 1249 RCM2_a183_hoodActuatorRSht2Bat_s "RCM2 ECU: a183 hood actuator r sht2 bat s";
CM_ SG_ 1249 RCM2_a184_hoodActuatorROpen_s "RCM2 ECU: a184 hood actuator r open s";
CM_ SG_ 1249 RCM2_a185_hoodActuatorRShort_s "RCM2 ECU: a185 hood actuator r short s";
CM_ SG_ 1249 RCM2_a186_hoodActuatorRCrssCoup_ "RCM2 ECU: a186 hood actuator r crss coup s";
CM_ SG_ 1249 RCM2_a187_hoodActuatorRConfig_s "RCM2 ECU: a187 hood actuator r config s";
CM_ SG_ 1249 RCM2_a188_hoodActuatorLSht2Gnd_s "RCM2 ECU: a188 hood actuator l sht2 gnd s";
CM_ SG_ 1249 RCM2_a189_hoodActuatorLSht2Bat_s "RCM2 ECU: a189 hood actuator l sht2 bat s";
CM_ SG_ 1249 RCM2_a190_hoodActuatorLOpen_s "RCM2 ECU: a190 hood actuator l open s";
CM_ SG_ 1249 RCM2_a191_hoodActuatorLShort_s "RCM2 ECU: a191 hood actuator l short s";
CM_ SG_ 1249 RCM2_a192_hoodActuatorLCrssCoup_ "RCM2 ECU: a192 hood actuator l crss coup s";
CM_ SG_ 1249 RCM2_a193_hoodActuatorLConfig_s "RCM2 ECU: a193 hood actuator l config s";
CM_ SG_ 1249 RCM2_a194_driverABAVSht2Gnd_s "RCM2 ECU: a194 driver ABAV sht2 gnd s";
CM_ SG_ 1249 RCM2_a195_driverABAVSht2Bat_s "RCM2 ECU: a195 driver ABAV sht2 bat s";
CM_ SG_ 1249 RCM2_a196_driverABAVOpen_s "RCM2 ECU: a196 driver ABAV open s";
CM_ SG_ 1249 RCM2_a197_driverABAVShort_s "RCM2 ECU: a197 driver ABAV short s";
CM_ SG_ 1249 RCM2_a198_driverABAVCrossCoup_s "RCM2 ECU: a198 driver ABAV cross coup s";
CM_ SG_ 1249 RCM2_a199_driverABAVConfig_s "RCM2 ECU: a199 driver ABAV config s";
CM_ SG_ 1249 RCM2_a200_driverFSABSht2Gnd_s "RCM2 ECU: a200 driver FSAB sht2 gnd s";
CM_ SG_ 1249 RCM2_a201_driverFSABSht2Bat_s "RCM2 ECU: a201 driver FSAB sht2 bat s";
CM_ SG_ 1249 RCM2_a202_driverFSABOpen_s "RCM2 ECU: a202 driver FSAB open s";
CM_ SG_ 1249 RCM2_a203_driverFSABShort_s "RCM2 ECU: a203 driver FSAB short s";
CM_ SG_ 1249 RCM2_a204_driverFSABCrossCoup_s "RCM2 ECU: a204 driver FSAB cross coup s";
CM_ SG_ 1249 RCM2_a205_driverFSABConfig_s "RCM2 ECU: a205 driver FSAB config s";
CM_ SG_ 1249 RCM2_a206_sideAB2ndRowLSht2Gnd_s "RCM2 ECU: a206 side ab2nd row l sht2 gnd s";
CM_ SG_ 1249 RCM2_a207_sideAB2ndRowLSht2Bat_s "RCM2 ECU: a207 side ab2nd row l sht2 bat s";
CM_ SG_ 1249 RCM2_a208_sideAB2ndRowLOpen_s "RCM2 ECU: a208 side ab2nd row l open s";
CM_ SG_ 1249 RCM2_a209_sideAB2ndRowLShort_s "RCM2 ECU: a209 side ab2nd row l short s";
CM_ SG_ 1249 RCM2_a210_sideAB2ndRowLCrssCoup_ "RCM2 ECU: a210 side ab2nd row l crss coup s";
CM_ SG_ 1249 RCM2_a211_sideAB2ndRowLConfig_s "RCM2 ECU: a211 side ab2nd row l config s";
CM_ SG_ 1249 RCM2_a212_sideAB2ndRowRSht2Gnd_s "RCM2 ECU: a212 side ab2nd row r sht2 gnd s";
CM_ SG_ 1249 RCM2_a213_sideAB2ndRowRSht2Bat_s "RCM2 ECU: a213 side ab2nd row r sht2 bat s";
CM_ SG_ 1249 RCM2_a214_sideAB2ndRowROpen_s "RCM2 ECU: a214 side ab2nd row r open s";
CM_ SG_ 1249 RCM2_a215_sideAB2ndRowRShort_s "RCM2 ECU: a215 side ab2nd row r short s";
CM_ SG_ 1249 RCM2_a216_sideAB2ndRowRCrssCoup_ "RCM2 ECU: a216 side ab2nd row r crss coup s";
CM_ SG_ 1249 RCM2_a217_sideAB2ndRowRConfig_s "RCM2 ECU: a217 side ab2nd row r config s";
CM_ SG_ 1249 RCM2_a250_ens1Sht2Bat_s "RCM2 ECU: a250 ens1 sht2 bat s";
CM_ SG_ 1249 RCM2_a251_ens1Sht2Gnd_s "RCM2 ECU: a251 ens1 sht2 gnd s";
CM_ SG_ 1249 RCM2_a252_ens1Config_s "RCM2 ECU: a252 ens1 config s";
CM_ SG_ 1249 RCM2_a253_ens2Sht2Bat_s "RCM2 ECU: a253 ens2 sht2 bat s";
CM_ SG_ 1249 RCM2_a254_ens2Sht2Gnd_s "RCM2 ECU: a254 ens2 sht2 gnd s";
CM_ SG_ 1249 RCM2_a256_ens3Sht2Bat_s "RCM2 ECU: a256 ens3 sht2 bat s";
CM_ SG_ 1249 RCM2_a257_ens3Sht2Gnd_s "RCM2 ECU: a257 ens3 sht2 gnd s";
CM_ SG_ 1249 RCM2_a258_ens3Config_s "RCM2 ECU: a258 ens3 config s";
CM_ SG_ 1249 RCM2_a259_ens4Sht2Bat_s "RCM2 ECU: a259 ens4 sht2 bat s";
CM_ SG_ 1249 RCM2_a260_ens4Sht2Gnd_s "RCM2 ECU: a260 ens4 sht2 gnd s";
CM_ SG_ 1249 RCM2_a261_ens4Config_s "RCM2 ECU: a261 ens4 config s";
CM_ SG_ 1249 RCM2_a264_imuYawR8OffCompPosLife "RCM2 ECU: a264 imu yaw R8 off comp pos life s";
CM_ SG_ 1249 RCM2_a265_imuYawR8OffCompNegLife "RCM2 ECU: a265 imu yaw R8 off comp neg life s";
CM_ SG_ 1249 RCM2_a266_imuYawR8OffCompPosFLDC "RCM2 ECU: a266 imu yaw R8 off comp pos FLDC s";
CM_ SG_ 1249 RCM2_a267_imuYawR8OffCompNegFLDC "RCM2 ECU: a267 imu yaw R8 off comp neg FLDC s";
CM_ SG_ 1249 RCM2_a268_imuYawR8OffCompPosSLDC "RCM2 ECU: a268 imu yaw R8 off comp pos SLDC s";
CM_ SG_ 1249 RCM2_a269_imuYawR8OffCompNegSLDC "RCM2 ECU: a269 imu yaw R8 off comp neg SLDC s";
CM_ SG_ 1249 RCM2_a270_imuPtchR8OffCompPosLif "RCM2 ECU: a270 imu ptch R8 off comp pos life s";
CM_ SG_ 1249 RCM2_a271_imuPtchR8OffCompNegLif "RCM2 ECU: a271 imu ptch R8 off comp neg life s";
CM_ SG_ 1249 RCM2_a272_imuPtchR8OffCompPosFLD "RCM2 ECU: a272 imu ptch R8 off comp pos FLDC s";
CM_ SG_ 1249 RCM2_a273_imuPtchR8OffCompNegFLD "RCM2 ECU: a273 imu ptch R8 off comp neg FLDC s";
CM_ SG_ 1249 RCM2_a274_imuPtchR8OffCompPosSLD "RCM2 ECU: a274 imu ptch R8 off comp pos SLDC s";
CM_ SG_ 1249 RCM2_a275_imuPtchR8OffCompNegSLD "RCM2 ECU: a275 imu ptch R8 off comp neg SLDC s";
CM_ SG_ 1249 RCM2_a276_imuRollR8OffCompPosLif "RCM2 ECU: a276 imu roll R8 off comp pos life s";
CM_ SG_ 1249 RCM2_a277_imuRollR8OffCompNegLif "RCM2 ECU: a277 imu roll R8 off comp neg life s";
CM_ SG_ 1249 RCM2_a278_imuRollR8OffCompPosFLD "RCM2 ECU: a278 imu roll R8 off comp pos FLDC s";
CM_ SG_ 1249 RCM2_a279_imuRollR8OffCompNegFLD "RCM2 ECU: a279 imu roll R8 off comp neg FLDC s";
CM_ SG_ 1249 RCM2_a280_imuRollR8OffCompPosSLD "RCM2 ECU: a280 imu roll R8 off comp pos SLDC s";
CM_ SG_ 1249 RCM2_a281_imuRollR8OffCompNegSLD "RCM2 ECU: a281 imu roll R8 off comp neg SLDC s";
CM_ SG_ 1249 RCM2_a282_imuLongAOffCompPosLife "RCM2 ECU: a282 imu long a off comp pos life s";
CM_ SG_ 1249 RCM2_a283_imuLongAOffCompNegLife "RCM2 ECU: a283 imu long a off comp neg life s";
CM_ SG_ 1249 RCM2_a284_imuLongAOffCompPosFLDC "RCM2 ECU: a284 imu long a off comp pos FLDC s";
CM_ SG_ 1249 RCM2_a285_imuLongAOffCompNegFLDC "RCM2 ECU: a285 imu long a off comp neg FLDC s";
CM_ SG_ 1249 RCM2_a286_imuLongAOffCompPosSLDC "RCM2 ECU: a286 imu long a off comp pos SLDC s";
CM_ SG_ 1249 RCM2_a287_imuLongAOffCompNegSLDC "RCM2 ECU: a287 imu long a off comp neg SLDC s";
CM_ SG_ 1249 RCM2_a288_imuLatAcOffCompPosLife "RCM2 ECU: a288 imu lat ac off comp pos life s";
CM_ SG_ 1249 RCM2_a289_imuLatAcOffCompNegLife "RCM2 ECU: a289 imu lat ac off comp neg life s";
CM_ SG_ 1249 RCM2_a290_imuLatAcOffCompPosFLDC "RCM2 ECU: a290 imu lat ac off comp pos FLDC s";
CM_ SG_ 1249 RCM2_a291_imuLatAcOffCompNegFLDC "RCM2 ECU: a291 imu lat ac off comp neg FLDC s";
CM_ SG_ 1249 RCM2_a292_imuLatAcOffCompPosSLDC "RCM2 ECU: a292 imu lat ac off comp pos SLDC s";
CM_ SG_ 1249 RCM2_a293_imuLatAcOffCompNegSLDC "RCM2 ECU: a293 imu lat ac off comp neg SLDC s";
CM_ SG_ 1249 RCM2_a294_imuVertAOffCompPosLife "RCM2 ECU: a294 imu vert a off comp pos life s";
CM_ SG_ 1249 RCM2_a295_imuVertAOffCompNegLife "RCM2 ECU: a295 imu vert a off comp neg life s";
CM_ SG_ 1249 RCM2_a296_imuVertAOffCompPosFLDC "RCM2 ECU: a296 imu vert a off comp pos FLDC s";
CM_ SG_ 1249 RCM2_a297_imuVertAOffCompNegFLDC "RCM2 ECU: a297 imu vert a off comp neg FLDC s";
CM_ SG_ 1249 RCM2_a298_imuVertAOffCompPosSLDC "RCM2 ECU: a298 imu vert a off comp pos SLDC s";
CM_ SG_ 1249 RCM2_a299_imuVertAOffCompNegSLDC "RCM2 ECU: a299 imu vert a off comp neg SLDC s";
CM_ SG_ 1249 RCM2_a300_imuAccXHgMonChlPerm_s "RCM2 ECU: a300 imu acc x hg mon chl perm s";
CM_ SG_ 1249 RCM2_a301_imuAccXHgMonChlTemp_s "RCM2 ECU: a301 imu acc x hg mon chl temp s";
CM_ SG_ 1249 RCM2_a302_imuAccYHgMonChlPerm_s "RCM2 ECU: a302 imu acc y hg mon chl perm s";
CM_ SG_ 1249 RCM2_a303_imuAccYHgMonChlTemp_s "RCM2 ECU: a303 imu acc y hg mon chl temp s";
CM_ SG_ 1249 RCM2_a304_imuYawR8SnsrPermBG_s "RCM2 ECU: a304 imu yaw R8 snsr perm BG s";
CM_ SG_ 1249 RCM2_a305_imuYawR8SnsrPermInit_s "RCM2 ECU: a305 imu yaw R8 snsr perm init s";
CM_ SG_ 1249 RCM2_a306_imuYawR8SnsrPermLF_s "RCM2 ECU: a306 imu yaw R8 snsr perm LF s";
CM_ SG_ 1249 RCM2_a307_imuYawR8ChnlMonTmpLF_s "RCM2 ECU: a307 imu yaw R8 chnl mon tmp LF s";
CM_ SG_ 1249 RCM2_a308_imuPitchR8SnsrPermBG_s "RCM2 ECU: a308 imu pitch R8 snsr perm BG s";
CM_ SG_ 1249 RCM2_a309_imuPitchR8SnsrPermInit "RCM2 ECU: a309 imu pitch R8 snsr perm init s";
CM_ SG_ 1249 RCM2_a310_imuPitchR8SnsrPermLF_s "RCM2 ECU: a310 imu pitch R8 snsr perm LF s";
CM_ SG_ 1249 RCM2_a311_imuPitchR8ChnlMonTmpLF "RCM2 ECU: a311 imu pitch R8 chnl mon tmp LF s";
CM_ SG_ 1249 RCM2_a312_imuRollR8SnsrPermBG_s "RCM2 ECU: a312 imu roll R8 snsr perm BG s";
CM_ SG_ 1249 RCM2_a313_imuRollR8SnsrPermInit_ "RCM2 ECU: a313 imu roll R8 snsr perm init s";
CM_ SG_ 1249 RCM2_a314_imuRollR8SnsrPermLF_s "RCM2 ECU: a314 imu roll R8 snsr perm LF s";
CM_ SG_ 1249 RCM2_a315_imuRollR8ChnlMonTmpLF_ "RCM2 ECU: a315 imu roll R8 chnl mon tmp LF s";
CM_ SG_ 1249 RCM2_a316_imuAccXLgMonChlPerm_s "RCM2 ECU: a316 imu acc x lg mon chl perm s";
CM_ SG_ 1249 RCM2_a317_imuAccXLgMonChlTemp_s "RCM2 ECU: a317 imu acc x lg mon chl temp s";
CM_ SG_ 1249 RCM2_a318_imuAccYLgMonChlPerm_s "RCM2 ECU: a318 imu acc y lg mon chl perm s";
CM_ SG_ 1249 RCM2_a319_imuAccYLgMonChlTemp_s "RCM2 ECU: a319 imu acc y lg mon chl temp s";
CM_ SG_ 1249 RCM2_a320_imuAccZLgMonChlPerm_s "RCM2 ECU: a320 imu acc z lg mon chl perm s";
CM_ SG_ 1249 RCM2_a321_imuAccZLgMonChlTemp_s "RCM2 ECU: a321 imu acc z lg mon chl temp s";
CM_ SG_ 1249 RCM2_a322_imuCalibrationFailed_s "RCM2 ECU: a322 imu calibration failed s";
CM_ SG_ 1249 RCM2_a323_imuCalibrationNotDone_ "RCM2 ECU: a323 imu calibration not done s";
CM_ SG_ 1249 RCM2_a350_upFrntSnsrLSht2Gnd_s "RCM2 ECU: a350 up frnt snsr l sht2 gnd s";
CM_ SG_ 1249 RCM2_a351_upFrntSnsrLSht2Bat_s "RCM2 ECU: a351 up frnt snsr l sht2 bat s";
CM_ SG_ 1249 RCM2_a352_upFrntSnsrLOpen_s "RCM2 ECU: a352 up frnt snsr l open s";
CM_ SG_ 1249 RCM2_a353_upFrntSnsrLCrssCoup_s "RCM2 ECU: a353 up frnt snsr l crss coup s";
CM_ SG_ 1249 RCM2_a354_upFrntSnsrLCommErr_s "RCM2 ECU: a354 up frnt snsr l comm err s";
CM_ SG_ 1249 RCM2_a355_upFrntSnsrLInitTyp_s "RCM2 ECU: a355 up frnt snsr l init typ s";
CM_ SG_ 1249 RCM2_a356_upFrntSnsrLConfig_s "RCM2 ECU: a356 up frnt snsr l config s";
CM_ SG_ 1249 RCM2_a357_upFrntSnsrLDefect_s "RCM2 ECU: a357 up frnt snsr l defect s";
CM_ SG_ 1249 RCM2_a358_upFrntSnsrLSigMon_s "RCM2 ECU: a358 up frnt snsr l sig mon s";
CM_ SG_ 1249 RCM2_a360_upFrntSnsrRSht2Gnd_s "RCM2 ECU: a360 up frnt snsr r sht2 gnd s";
CM_ SG_ 1249 RCM2_a361_upFrntSnsrRSht2Bat_s "RCM2 ECU: a361 up frnt snsr r sht2 bat s";
CM_ SG_ 1249 RCM2_a362_upFrntSnsrROpen_s "RCM2 ECU: a362 up frnt snsr r open s";
CM_ SG_ 1249 RCM2_a363_upFrntSnsrRCrssCoup_s "RCM2 ECU: a363 up frnt snsr r crss coup s";
CM_ SG_ 1249 RCM2_a364_upFrntSnsrRCommErr_s "RCM2 ECU: a364 up frnt snsr r comm err s";
CM_ SG_ 1249 RCM2_a365_upFrntSnsrRInitTyp_s "RCM2 ECU: a365 up frnt snsr r init typ s";
CM_ SG_ 1249 RCM2_a366_upFrntSnsrRConfig_s "RCM2 ECU: a366 up frnt snsr r config s";
CM_ SG_ 1249 RCM2_a367_upFrntSnsrRDefect_s "RCM2 ECU: a367 up frnt snsr r defect s";
CM_ SG_ 1249 RCM2_a368_upFrntSnsrRSigMon_s "RCM2 ECU: a368 up frnt snsr r sig mon s";
CM_ SG_ 1249 RCM2_a370_upFrntSnsrMidLSht2Gnd_ "RCM2 ECU: a370 up frnt snsr mid l sht2 gnd s";
CM_ SG_ 1249 RCM2_a371_upFrntSnsrMidLSht2Bat_ "RCM2 ECU: a371 up frnt snsr mid l sht2 bat s";
CM_ SG_ 1249 RCM2_a372_upFrntSnsrMidLOpen_s "RCM2 ECU: a372 up frnt snsr mid l open s";
CM_ SG_ 1249 RCM2_a373_upFrntSnsrMidLCrssCoup "RCM2 ECU: a373 up frnt snsr mid l crss coup s";
CM_ SG_ 1249 RCM2_a374_upFrntSnsrMidLCommErr_ "RCM2 ECU: a374 up frnt snsr mid l comm err s";
CM_ SG_ 1249 RCM2_a375_upFrntSnsrMidLInitTyp_ "RCM2 ECU: a375 up frnt snsr mid l init typ s";
CM_ SG_ 1249 RCM2_a376_upFrntSnsrMidLConfig_s "RCM2 ECU: a376 up frnt snsr mid l config s";
CM_ SG_ 1249 RCM2_a377_upFrntSnsrMidLDefect_s "RCM2 ECU: a377 up frnt snsr mid l defect s";
CM_ SG_ 1249 RCM2_a378_upFrntSnsrMidLSigMon_s "RCM2 ECU: a378 up frnt snsr mid l sig mon s";
CM_ SG_ 1249 RCM2_a380_upFrntSnsrMidRSht2Gnd_ "RCM2 ECU: a380 up frnt snsr mid r sht2 gnd s";
CM_ SG_ 1249 RCM2_a381_upFrntSnsrMidRSht2Bat_ "RCM2 ECU: a381 up frnt snsr mid r sht2 bat s";
CM_ SG_ 1249 RCM2_a382_upFrntSnsrMidROpen_s "RCM2 ECU: a382 up frnt snsr mid r open s";
CM_ SG_ 1249 RCM2_a383_upFrntSnsrMidRCrssCoup "RCM2 ECU: a383 up frnt snsr mid r crss coup s";
CM_ SG_ 1249 RCM2_a384_upFrntSnsrMidRCommErr_ "RCM2 ECU: a384 up frnt snsr mid r comm err s";
CM_ SG_ 1249 RCM2_a385_upFrntSnsrMidRInitTyp_ "RCM2 ECU: a385 up frnt snsr mid r init typ s";
CM_ SG_ 1249 RCM2_a386_upFrntSnsrMidRConfig_s "RCM2 ECU: a386 up frnt snsr mid r config s";
CM_ SG_ 1249 RCM2_a387_upFrntSnsrMidRDefect_s "RCM2 ECU: a387 up frnt snsr mid r defect s";
CM_ SG_ 1249 RCM2_a388_upFrntSnsrMidRSigMon_s "RCM2 ECU: a388 up frnt snsr mid r sig mon s";
CM_ SG_ 1249 RCM2_a390_sideAccelBPilLSht2Gnd_ "RCM2 ECU: a390 side accel b pil l sht2 gnd s";
CM_ SG_ 1249 RCM2_a391_sideAccelBPilLSht2Bat_ "RCM2 ECU: a391 side accel b pil l sht2 bat s";
CM_ SG_ 1249 RCM2_a392_sideAccelBPilLOpen_s "RCM2 ECU: a392 side accel b pil l open s";
CM_ SG_ 1249 RCM2_a393_sideAccelBPilLCLosCoup "RCM2 ECU: a393 side accel b pil LC los coup s";
CM_ SG_ 1249 RCM2_a394_sideAccelBPilLCommErr_ "RCM2 ECU: a394 side accel b pil l comm err s";
CM_ SG_ 1249 RCM2_a395_sideAccelBPilLInitTyp_ "RCM2 ECU: a395 side accel b pil l init typ s";
CM_ SG_ 1249 RCM2_a396_sideAccelBPilLConfig_s "RCM2 ECU: a396 side accel b pil l config s";
CM_ SG_ 1249 RCM2_a397_sideAccelBPilLDefect_s "RCM2 ECU: a397 side accel b pil l defect s";
CM_ SG_ 1249 RCM2_a398_sideAccelBPilLSigMon_s "RCM2 ECU: a398 side accel b pil l sig mon s";
CM_ SG_ 1249 RCM2_a400_sideAccelBPilRSht2Gnd_ "RCM2 ECU: a400 side accel b pil r sht2 gnd s";
CM_ SG_ 1249 RCM2_a401_sideAccelBPilRSht2Bat_ "RCM2 ECU: a401 side accel b pil r sht2 bat s";
CM_ SG_ 1249 RCM2_a402_sideAccelBPilROpen_s "RCM2 ECU: a402 side accel b pil r open s";
CM_ SG_ 1249 RCM2_a403_sideAccelBPilRCrssCoup "RCM2 ECU: a403 side accel b pil r crss coup s";
CM_ SG_ 1249 RCM2_a404_sideAccelBPilRCommErr_ "RCM2 ECU: a404 side accel b pil r comm err s";
CM_ SG_ 1249 RCM2_a405_sideAccelBPilRInitTyp_ "RCM2 ECU: a405 side accel b pil r init typ s";
CM_ SG_ 1249 RCM2_a406_sideAccelBPilRConfig_s "RCM2 ECU: a406 side accel b pil r config s";
CM_ SG_ 1249 RCM2_a407_sideAccelBPilRDefect_s "RCM2 ECU: a407 side accel b pil r defect s";
CM_ SG_ 1249 RCM2_a408_sideAccelBPilRSigMon_s "RCM2 ECU: a408 side accel b pil r sig mon s";
CM_ SG_ 1249 RCM2_a410_sideAccelCPilLSht2Gnd_ "RCM2 ECU: a410 side accel c pil l sht2 gnd s";
CM_ SG_ 1249 RCM2_a411_sideAccelCPilLSht2Bat_ "RCM2 ECU: a411 side accel c pil l sht2 bat s";
CM_ SG_ 1249 RCM2_a412_sideAccelCPilLOpen_s "RCM2 ECU: a412 side accel c pil l open s";
CM_ SG_ 1249 RCM2_a413_sideAccelCPilLCrssCoup "RCM2 ECU: a413 side accel c pil l crss coup s";
CM_ SG_ 1249 RCM2_a414_sideAccelCPilLCommErr_ "RCM2 ECU: a414 side accel c pil l comm err s";
CM_ SG_ 1249 RCM2_a415_sideAccelCPilLInitTyp_ "RCM2 ECU: a415 side accel c pil l init typ s";
CM_ SG_ 1249 RCM2_a416_sideAccelCPilLConfig_s "RCM2 ECU: a416 side accel c pil l config s";
CM_ SG_ 1249 RCM2_a417_sideAccelCPilLDefect_s "RCM2 ECU: a417 side accel c pil l defect s";
CM_ SG_ 1249 RCM2_a418_sideAccelCPilLSigMon_s "RCM2 ECU: a418 side accel c pil l sig mon s";
CM_ SG_ 1249 RCM2_a420_sideAccelCPilRSht2Gnd_ "RCM2 ECU: a420 side accel c pil r sht2 gnd s";
CM_ SG_ 1249 RCM2_a421_sideAccelCPilRSht2Bat_ "RCM2 ECU: a421 side accel c pil r sht2 bat s";
CM_ SG_ 1249 RCM2_a422_sideAccelCPilROpen_s "RCM2 ECU: a422 side accel c pil r open s";
CM_ SG_ 1249 RCM2_a423_sideAccelCPilRCrssCoup "RCM2 ECU: a423 side accel c pil r crss coup s";
CM_ SG_ 1249 RCM2_a424_sideAccelCPilRCommErr_ "RCM2 ECU: a424 side accel c pil r comm err s";
CM_ SG_ 1249 RCM2_a425_sideAccelCPilRInitTyp_ "RCM2 ECU: a425 side accel c pil r init typ s";
CM_ SG_ 1249 RCM2_a426_sideAccelCPilRConfig_s "RCM2 ECU: a426 side accel c pil r config s";
CM_ SG_ 1249 RCM2_a427_sideAccelCPilRDefect_s "RCM2 ECU: a427 side accel c pil r defect s";
CM_ SG_ 1249 RCM2_a428_sideAccelCPilRSigMon_s "RCM2 ECU: a428 side accel c pil r sig mon s";
CM_ SG_ 1249 RCM2_a430_presFrntLDoorSht2Gnd_s "RCM2 ECU: a430 pres frnt l door sht2 gnd s";
CM_ SG_ 1249 RCM2_a431_presFrntLDoorSht2Bat_s "RCM2 ECU: a431 pres frnt l door sht2 bat s";
CM_ SG_ 1249 RCM2_a432_presFrntLDoorOpen_s "RCM2 ECU: a432 pres frnt l door open s";
CM_ SG_ 1249 RCM2_a433_presFrntLDoorCrssCoup_ "RCM2 ECU: a433 pres frnt l door crss coup s";
CM_ SG_ 1249 RCM2_a434_presFrntLDoorCommErr_s "RCM2 ECU: a434 pres frnt l door comm err s";
CM_ SG_ 1249 RCM2_a435_presFrntLDoorInitTyp_s "RCM2 ECU: a435 pres frnt l door init typ s";
CM_ SG_ 1249 RCM2_a436_presFrntLDoorConfig_s "RCM2 ECU: a436 pres frnt l door config s";
CM_ SG_ 1249 RCM2_a437_presFrntLDoorDefect_s "RCM2 ECU: a437 pres frnt l door defect s";
CM_ SG_ 1249 RCM2_a438_presFrntLDoorSigMon_s "RCM2 ECU: a438 pres frnt l door sig mon s";
CM_ SG_ 1249 RCM2_a439_presDoorAbsolute1_s "RCM2 ECU: a439 pres door absolute1 s";
CM_ SG_ 1249 RCM2_a440_presFrntRDoorSht2Gnd_s "RCM2 ECU: a440 pres frnt r door sht2 gnd s";
CM_ SG_ 1249 RCM2_a441_presFrntRDoorSht2Bat_s "RCM2 ECU: a441 pres frnt r door sht2 bat s";
CM_ SG_ 1249 RCM2_a442_presFrntRDoorOpen_s "RCM2 ECU: a442 pres frnt r door open s";
CM_ SG_ 1249 RCM2_a443_presFrntRDoorCrssCoup_ "RCM2 ECU: a443 pres frnt r door crss coup s";
CM_ SG_ 1249 RCM2_a444_presFrntRDoorCommErr_s "RCM2 ECU: a444 pres frnt r door comm err s";
CM_ SG_ 1249 RCM2_a445_presFrntRDoorInitTyp_s "RCM2 ECU: a445 pres frnt r door init typ s";
CM_ SG_ 1249 RCM2_a446_presFrntRDoorConfig_s "RCM2 ECU: a446 pres frnt r door config s";
CM_ SG_ 1249 RCM2_a447_presFrntRDoorDefect_s "RCM2 ECU: a447 pres frnt r door defect s";
CM_ SG_ 1249 RCM2_a448_presFrntRDoorSigMon_s "RCM2 ECU: a448 pres frnt r door sig mon s";
CM_ SG_ 1249 RCM2_a449_presDoorAbsolute2_s "RCM2 ECU: a449 pres door absolute2 s";
CM_ SG_ 1249 RCM2_a450_presPedProLSht2Gnd_s "RCM2 ECU: a450 pres ped pro l sht2 gnd s";
CM_ SG_ 1249 RCM2_a451_presPedProLSht2Bat_s "RCM2 ECU: a451 pres ped pro l sht2 bat s";
CM_ SG_ 1249 RCM2_a452_presPedProLOpen_s "RCM2 ECU: a452 pres ped pro l open s";
CM_ SG_ 1249 RCM2_a453_presPedProLCrssCoup_s "RCM2 ECU: a453 pres ped pro l crss coup s";
CM_ SG_ 1249 RCM2_a454_presPedProLCommErr_s "RCM2 ECU: a454 pres ped pro l comm err s";
CM_ SG_ 1249 RCM2_a455_presPedProLInitTyp_s "RCM2 ECU: a455 pres ped pro l init typ s";
CM_ SG_ 1249 RCM2_a456_presPedProLConfig_s "RCM2 ECU: a456 pres ped pro l config s";
CM_ SG_ 1249 RCM2_a457_presPedProLDefect_s "RCM2 ECU: a457 pres ped pro l defect s";
CM_ SG_ 1249 RCM2_a458_presPedProLSigMon_s "RCM2 ECU: a458 pres ped pro l sig mon s";
CM_ SG_ 1249 RCM2_a460_presPedProRSht2Gnd_s "RCM2 ECU: a460 pres ped pro r sht2 gnd s";
CM_ SG_ 1249 RCM2_a461_presPedProRSht2Bat_s "RCM2 ECU: a461 pres ped pro r sht2 bat s";
CM_ SG_ 1249 RCM2_a462_presPedProROpen_s "RCM2 ECU: a462 pres ped pro r open s";
CM_ SG_ 1249 RCM2_a463_presPedProRCrssCoup_s "RCM2 ECU: a463 pres ped pro r crss coup s";
CM_ SG_ 1249 RCM2_a464_presPedProRCommErr_s "RCM2 ECU: a464 pres ped pro r comm err s";
CM_ SG_ 1249 RCM2_a465_presPedProRInitTyp_s "RCM2 ECU: a465 pres ped pro r init typ s";
CM_ SG_ 1249 RCM2_a466_presPedProRConfig_s "RCM2 ECU: a466 pres ped pro r config s";
CM_ SG_ 1249 RCM2_a467_presPedProRDefect_s "RCM2 ECU: a467 pres ped pro r defect s";
CM_ SG_ 1249 RCM2_a468_presPedProRSigMon_s "RCM2 ECU: a468 pres ped pro r sig mon s";
CM_ SG_ 1249 RCM2_a469_presPedProAbsolute_s "RCM2 ECU: a469 pres ped pro absolute s";
CM_ SG_ 1249 RCM2_a470_upFrntPedProLSht2Gnd_s "RCM2 ECU: a470 up frnt ped pro l sht2 gnd s";
CM_ SG_ 1249 RCM2_a471_upFrntPedProLSht2Bat_s "RCM2 ECU: a471 up frnt ped pro l sht2 bat s";
CM_ SG_ 1249 RCM2_a472_upFrntPedProLOpen_s "RCM2 ECU: a472 up frnt ped pro l open s";
CM_ SG_ 1249 RCM2_a473_upFrntPedProLCrssCoup_ "RCM2 ECU: a473 up frnt ped pro l crss coup s";
CM_ SG_ 1249 RCM2_a474_upFrntPedProLCommErr_s "RCM2 ECU: a474 up frnt ped pro l comm err s";
CM_ SG_ 1249 RCM2_a475_upFrntPedProLIntTyp_s "RCM2 ECU: a475 up frnt ped pro l int typ s";
CM_ SG_ 1249 RCM2_a476_upFrntPedProLConfig_s "RCM2 ECU: a476 up frnt ped pro l config s";
CM_ SG_ 1249 RCM2_a477_upFrntPedProLDefect_s "RCM2 ECU: a477 up frnt ped pro l defect s";
CM_ SG_ 1249 RCM2_a478_upFrntPedProLSigMon_s "RCM2 ECU: a478 up frnt ped pro l sig mon s";
CM_ SG_ 1249 RCM2_a480_upFrntPedProRSht2Gnd_s "RCM2 ECU: a480 up frnt ped pro r sht2 gnd s";
CM_ SG_ 1249 RCM2_a481_upFrntPedProRSht2Bat_s "RCM2 ECU: a481 up frnt ped pro r sht2 bat s";
CM_ SG_ 1249 RCM2_a482_upFrntPedProROpen_s "RCM2 ECU: a482 up frnt ped pro r open s";
CM_ SG_ 1249 RCM2_a483_upFrntPedProRCrssCoup_ "RCM2 ECU: a483 up frnt ped pro r crss coup s";
CM_ SG_ 1249 RCM2_a484_upFrntPedProRCommErr_s "RCM2 ECU: a484 up frnt ped pro r comm err s";
CM_ SG_ 1249 RCM2_a485_upFrntPedProRIntTyp_s "RCM2 ECU: a485 up frnt ped pro r int typ s";
CM_ SG_ 1249 RCM2_a486_upFrntPedProRConfig_s "RCM2 ECU: a486 up frnt ped pro r config s";
CM_ SG_ 1249 RCM2_a487_upFrntPedProRDefect_s "RCM2 ECU: a487 up frnt ped pro r defect s";
CM_ SG_ 1249 RCM2_a488_upFrntPedProRSigMon_s "RCM2 ECU: a488 up frnt ped pro r sig mon s";
CM_ SG_ 1249 RCM2_a490_presRearLDoorSht2Gnd_s "RCM2 ECU: a490 pres rear l door sht2 gnd s";
CM_ SG_ 1249 RCM2_a491_presRearLDoorSht2Bat_s "RCM2 ECU: a491 pres rear l door sht2 bat s";
CM_ SG_ 1249 RCM2_a492_presRearLDoorOpen_s "RCM2 ECU: a492 pres rear l door open s";
CM_ SG_ 1249 RCM2_a493_presRearLDoorCrssCoup_ "RCM2 ECU: a493 pres rear l door crss coup s";
CM_ SG_ 1249 RCM2_a494_presRearLDoorCommErr_s "RCM2 ECU: a494 pres rear l door comm err s";
CM_ SG_ 1249 RCM2_a495_presRearLDoorInitTyp_s "RCM2 ECU: a495 pres rear l door init typ s";
CM_ SG_ 1249 RCM2_a496_presRearLDoorConfig_s "RCM2 ECU: a496 pres rear l door config s";
CM_ SG_ 1249 RCM2_a497_presRearLDoorDefect_s "RCM2 ECU: a497 pres rear l door defect s";
CM_ SG_ 1249 RCM2_a498_presRearLDoorSigMon_s "RCM2 ECU: a498 pres rear l door sig mon s";
CM_ SG_ 1249 RCM2_a500_presRearRDoorSht2Gnd_s "RCM2 ECU: a500 pres rear r door sht2 gnd s";
CM_ SG_ 1249 RCM2_a501_presRearRDoorSht2Bat_s "RCM2 ECU: a501 pres rear r door sht2 bat s";
CM_ SG_ 1249 RCM2_a502_presRearRDoorOpen_s "RCM2 ECU: a502 pres rear r door open s";
CM_ SG_ 1249 RCM2_a503_presRearRDoorCrssCoup_ "RCM2 ECU: a503 pres rear r door crss coup s";
CM_ SG_ 1249 RCM2_a504_presRearRDoorCommErr_s "RCM2 ECU: a504 pres rear r door comm err s";
CM_ SG_ 1249 RCM2_a505_presRearRDoorInitTyp_s "RCM2 ECU: a505 pres rear r door init typ s";
CM_ SG_ 1249 RCM2_a506_presRearRDoorConfig_s "RCM2 ECU: a506 pres rear r door config s";
CM_ SG_ 1249 RCM2_a507_presRearRDoorDefect_s "RCM2 ECU: a507 pres rear r door defect s";
CM_ SG_ 1249 RCM2_a508_presRearRDoorSigMon_s "RCM2 ECU: a508 pres rear r door sig mon s";
CM_ SG_ 1249 RCM2_a509_sideAccelDPilLSht2Gnd_ "RCM2 ECU: a509 side accel d pil l sht2 gnd s";
CM_ SG_ 1249 RCM2_a510_sideAccelDPilLSht2Bat_ "RCM2 ECU: a510 side accel d pil l sht2 bat s";
CM_ SG_ 1249 RCM2_a511_sideAccelDPilLOpen_s "RCM2 ECU: a511 side accel d pil l open s";
CM_ SG_ 1249 RCM2_a512_sideAccelDPilLCrssCoup "RCM2 ECU: a512 side accel d pil l crss coup s";
CM_ SG_ 1249 RCM2_a513_sideAccelDPilLCommErr_ "RCM2 ECU: a513 side accel d pil l comm err s";
CM_ SG_ 1249 RCM2_a514_sideAccelDPilLInitTyp_ "RCM2 ECU: a514 side accel d pil l init typ s";
CM_ SG_ 1249 RCM2_a515_sideAccelDPilLConfig_s "RCM2 ECU: a515 side accel d pil l config s";
CM_ SG_ 1249 RCM2_a516_sideAccelDPilLDefect_s "RCM2 ECU: a516 side accel d pil l defect s";
CM_ SG_ 1249 RCM2_a517_sideAccelDPilLSigMon_s "RCM2 ECU: a517 side accel d pil l sig mon s";
CM_ SG_ 1249 RCM2_a518_sideAccelDPilRSht2Gnd_ "RCM2 ECU: a518 side accel d pil r sht2 gnd s";
CM_ SG_ 1249 RCM2_a519_sideAccelDPilRSht2Bat_ "RCM2 ECU: a519 side accel d pil r sht2 bat s";
CM_ SG_ 1249 RCM2_a520_sideAccelDPilROpen_s "RCM2 ECU: a520 side accel d pil r open s";
CM_ SG_ 1249 RCM2_a521_sideAccelDPilRCrssCoup "RCM2 ECU: a521 side accel d pil r crss coup s";
CM_ SG_ 1249 RCM2_a522_sideAccelDPilRCommErr_ "RCM2 ECU: a522 side accel d pil r comm err s";
CM_ SG_ 1249 RCM2_a523_sideAccelDPilRInitTyp_ "RCM2 ECU: a523 side accel d pil r init typ s";
CM_ SG_ 1249 RCM2_a524_sideAccelDPilRConfig_s "RCM2 ECU: a524 side accel d pil r config s";
CM_ SG_ 1249 RCM2_a525_sideAccelDPilRDefect_s "RCM2 ECU: a525 side accel d pil r defect s";
CM_ SG_ 1249 RCM2_a526_sideAccelDPilRSigMon_s "RCM2 ECU: a526 side accel d pil r sig mon s";
CM_ SG_ 1249 RCM2_a527_upFrntSnsrCSht2Gnd_s "RCM2 ECU: a527 up frnt snsr c sht2 gnd s";
CM_ SG_ 1249 RCM2_a528_upFrntSnsrCSht2Bat_s "RCM2 ECU: a528 up frnt snsr c sht2 bat s";
CM_ SG_ 1249 RCM2_a529_upFrntSnsrCOpen_s "RCM2 ECU: a529 up frnt snsr c open s";
CM_ SG_ 1249 RCM2_a530_upFrntSnsrCCrssCoup_s "RCM2 ECU: a530 up frnt snsr c crss coup s";
CM_ SG_ 1249 RCM2_a531_upFrntSnsrCCommErr_s "RCM2 ECU: a531 up frnt snsr c comm err s";
CM_ SG_ 1249 RCM2_a532_upFrntSnsrCInitTyp_s "RCM2 ECU: a532 up frnt snsr c init typ s";
CM_ SG_ 1249 RCM2_a533_upFrntSnsrCConfig_s "RCM2 ECU: a533 up frnt snsr c config s";
CM_ SG_ 1249 RCM2_a534_upFrntSnsrCDefect_s "RCM2 ECU: a534 up frnt snsr c defect s";
CM_ SG_ 1249 RCM2_a535_upFrntSnsrCSigMon_s "RCM2 ECU: a535 up frnt snsr c sig mon s";
CM_ SG_ 1249 RCM2_a550_bucklHallLeftSht2Gnd_s "RCM2 ECU: a550 buckl hall left sht2 gnd s";
CM_ SG_ 1249 RCM2_a551_bucklHallLeftSht2Bat_s "RCM2 ECU: a551 buckl hall left sht2 bat s";
CM_ SG_ 1249 RCM2_a552_bucklHallLeftOpen_s "RCM2 ECU: a552 buckl hall left open s";
CM_ SG_ 1249 RCM2_a553_bucklHallLeftUndef_s "RCM2 ECU: a553 buckl hall left undef s";
CM_ SG_ 1249 RCM2_a554_bucklHallLeftCrssCoup_ "RCM2 ECU: a554 buckl hall left crss coup s";
CM_ SG_ 1249 RCM2_a555_bucklHallLeftConfig_s "RCM2 ECU: a555 buckl hall left config s";
CM_ SG_ 1249 RCM2_a556_bucklHallRightSht2Gnd_ "RCM2 ECU: a556 buckl hall right sht2 gnd s";
CM_ SG_ 1249 RCM2_a557_bucklHallRightSht2Bat_ "RCM2 ECU: a557 buckl hall right sht2 bat s";
CM_ SG_ 1249 RCM2_a558_bucklHallRightOpen_s "RCM2 ECU: a558 buckl hall right open s";
CM_ SG_ 1249 RCM2_a559_bucklHallRightUndef_s "RCM2 ECU: a559 buckl hall right undef s";
CM_ SG_ 1249 RCM2_a560_bucklHallRightCrssCoup "RCM2 ECU: a560 buckl hall right crss coup s";
CM_ SG_ 1249 RCM2_a561_bucklHallRightConfig_s "RCM2 ECU: a561 buckl hall right config s";
CM_ SG_ 1249 RCM2_a562_seaTrkPosLeftSht2Gnd_s "RCM2 ECU: a562 sea trk pos left sht2 gnd s";
CM_ SG_ 1249 RCM2_a563_seaTrkPosLeftShtBat_s "RCM2 ECU: a563 sea trk pos left sht bat s";
CM_ SG_ 1249 RCM2_a564_seaTrkPosLeftOpen_s "RCM2 ECU: a564 sea trk pos left open s";
CM_ SG_ 1249 RCM2_a565_seaTrkPosLeftUndefined "RCM2 ECU: a565 sea trk pos left undefined s";
CM_ SG_ 1249 RCM2_a566_seaTrkPosLeftCrssCoup_ "RCM2 ECU: a566 sea trk pos left crss coup s";
CM_ SG_ 1249 RCM2_a567_seaTrkPosLeftConfig_s "RCM2 ECU: a567 sea trk pos left config s";
CM_ SG_ 1249 RCM2_a568_occPROSSht2Gnd_s "RCM2 ECU: a568 occ PROS sht2 gnd s";
CM_ SG_ 1249 RCM2_a569_occPROSSht2Bat_s "RCM2 ECU: a569 occ PROS sht2 bat s";
CM_ SG_ 1249 RCM2_a570_occPROSOpen_s "RCM2 ECU: a570 occ PROS open s";
CM_ SG_ 1249 RCM2_a571_occPROSUndef_s "RCM2 ECU: a571 occ PROS undef s";
CM_ SG_ 1249 RCM2_a572_occPROSCrssCoup_s "RCM2 ECU: a572 occ PROS crss coup s";
CM_ SG_ 1249 RCM2_a573_occPROSConfig_s "RCM2 ECU: a573 occ PROS config s";
CM_ SG_ 1249 RCM2_a587_sbrRearNetworkSht2Gnd_ "RCM2 ECU: a587 sbr rear network sht2 gnd s";
CM_ SG_ 1249 RCM2_a588_sbrRearNetworkSht2Bat_ "RCM2 ECU: a588 sbr rear network sht2 bat s";
CM_ SG_ 1249 RCM2_a591_sbrRearNetworkCrssCoup "RCM2 ECU: a591 sbr rear network crss coup s";
CM_ SG_ 1249 RCM2_a592_sbrRearNetworkConfig_s "RCM2 ECU: a592 sbr rear network config s";
CM_ SG_ 1249 RCM2_a593_driveOrientationSht2Gn "RCM2 ECU: a593 drive orientation sht2 gnd s";
CM_ SG_ 1249 RCM2_a594_driveOrientationSht2Ba "RCM2 ECU: a594 drive orientation sht2 bat s";
CM_ SG_ 1249 RCM2_a595_driveOrientationOpen_s "RCM2 ECU: a595 drive orientation open s";
CM_ SG_ 1249 RCM2_a596_driveOrientationUndefi "RCM2 ECU: a596 drive orientation undefined s";
CM_ SG_ 1249 RCM2_a597_driveOrientationCrssCo "RCM2 ECU: a597 drive orientation crss coup s";
CM_ SG_ 1249 RCM2_a598_driveOrientationConfig "RCM2 ECU: a598 drive orientation config s";
CM_ SG_ 1249 RCM2_a600_comCANinternalTimeout_ "RCM2 ECU: a600 com CA ninternal timeout s";
CM_ SG_ 1249 RCM2_a601_comChassisCANSilent_s "RCM2 ECU: a601 com chassis CAN silent s";
CM_ SG_ 1249 RCM2_a602_comChassisCANBusOff_s "RCM2 ECU: a602 com chassis CAN bus off s";
CM_ SG_ 1249 RCM2_a603_comPARTYCANSilent_s "RCM2 ECU: a603 com PARTYCAN silent s";
CM_ SG_ 1249 RCM2_a604_comPARTYCANBusOff_s "RCM2 ECU: a604 com PARTYCAN bus off s";
CM_ SG_ 1249 RCM2_a620_comInvalidVehicleSpeed "RCM2 ECU: a620 com invalid vehicle speed s";
CM_ SG_ 1249 RCM2_a630_comGTWACSMIA_s "RCM2 ECU: a630 com GTWACSMIA s";
CM_ SG_ 1249 RCM2_a631_comGTWACSChkSm_s "RCM2 ECU: a631 com GTWACS chk sm s";
CM_ SG_ 1249 RCM2_a632_comGTWACSCntr_s "RCM2 ECU: a632 com GTWACS cntr s";
CM_ SG_ 1249 RCM2_a633_comOCS1PMIA_s "RCM2 ECU: a633 com OCS1 PMIA s";
CM_ SG_ 1249 RCM2_a634_comOCS1PChkSm_s "RCM2 ECU: a634 com OCS1 p chk sm s";
CM_ SG_ 1249 RCM2_a635_comOCS1PCntr_s "RCM2 ECU: a635 com OCS1 p cntr s";
CM_ SG_ 1249 RCM2_a636_ocsFaulted_s "RCM2 ECU: a636 ocs faulted s";
CM_ SG_ 1249 RCM2_a637_ocsUnknown_s "RCM2 ECU: a637 ocs unknown s";
CM_ SG_ 1249 RCM2_a642_comVINmessageMIA_s "RCM2 ECU: a642 com VI nmessage MIA s";
CM_ SG_ 1249 RCM2_a652_ambientTempFaulted_s "RCM2 ECU: a652 ambient temp faulted s";
CM_ SG_ 1249 RCM2_a656_comVCSEATPrestMIA_s "RCM2 ECU: a656 com VCSEAT prest MIA s";
CM_ SG_ 1249 RCM2_a657_comVCSEATPrestChkSm_s "RCM2 ECU: a657 com VCSEAT prest chk sm s";
CM_ SG_ 1249 RCM2_a658_comVCSEATPrestCntr_s "RCM2 ECU: a658 com VCSEAT prest cntr s";
CM_ SG_ 1249 RCM2_a659_comVCSEATPbuckle_s "RCM2 ECU: a659 com VCSEAT pbuckle s";
CM_ SG_ 1249 RCM2_a660_comVCSEATPOccpy_s "RCM2 ECU: a660 com VCSEATP occpy s";
CM_ SG_ 1249 RCM2_a661_comVCSEATPocs_s "RCM2 ECU: a661 com VCSEAT pocs s";
CM_ SG_ 1249 RCM2_a662_comVCSEATPstps_s "RCM2 ECU: a662 com VCSEAT pstps s";
CM_ SG_ 1249 RCM2_a663_comVCSEATDrestMIA_s "RCM2 ECU: a663 com VCSEAT drest MIA s";
CM_ SG_ 1249 RCM2_a664_comVCSEATDrestChkSm_s "RCM2 ECU: a664 com VCSEAT drest chk sm s";
CM_ SG_ 1249 RCM2_a665_comVCSEATDrestCntr_s "RCM2 ECU: a665 com VCSEAT drest cntr s";
CM_ SG_ 1249 RCM2_a666_comVCSEATDbuckle_s "RCM2 ECU: a666 com VCSEAT dbuckle s";
CM_ SG_ 1249 RCM2_a667_comVCSEATDOccpy_s "RCM2 ECU: a667 com VCSEATD occpy s";
CM_ SG_ 1249 RCM2_a668_comVCSEATDstps_s "RCM2 ECU: a668 com VCSEAT dstps s";
CM_ SG_ 1249 RCM2_a688_comVCLEFTrestMIA_s "RCM2 ECU: a688 com VCLEF trest MIA s";
CM_ SG_ 1249 RCM2_a689_comVCLEFTrestChkSm_s "RCM2 ECU: a689 com VCLEF trest chk sm s";
CM_ SG_ 1249 RCM2_a690_comVCLEFTrestCntr_s "RCM2 ECU: a690 com VCLEF trest cntr s";
CM_ SG_ 1249 RCM2_a691_comVCLEFT1rLBuckle_s "RCM2 ECU: a691 com vcleft1r l buckle s";
CM_ SG_ 1249 RCM2_a692_comVCLEFT2rLBuckle_s "RCM2 ECU: a692 com vcleft2r l buckle s";
CM_ SG_ 1249 RCM2_a693_comVCLEFT1rLSTPS_s "RCM2 ECU: a693 com vcleft1r LSTPS s";
CM_ SG_ 1249 RCM2_a694_comVCRIGHTrestMIA_s "RCM2 ECU: a694 com VCRIGH trest MIA s";
CM_ SG_ 1249 RCM2_a695_comVCRIGHTrestChkSm_s "RCM2 ECU: a695 com VCRIGH trest chk sm s";
CM_ SG_ 1249 RCM2_a696_comVCRIGHTrestCntr_s "RCM2 ECU: a696 com VCRIGH trest cntr s";
CM_ SG_ 1249 RCM2_a697_comVCRIGHT1rRBuckle_s "RCM2 ECU: a697 com vcright1r r buckle s";
CM_ SG_ 1249 RCM2_a698_comVCRIGHT2rRBuckle_s "RCM2 ECU: a698 com vcright2r r buckle s";
CM_ SG_ 1249 RCM2_a699_comVCRIGHTocs_s "RCM2 ECU: a699 com VCRIGH tocs s";
CM_ SG_ 1249 RCM2_a700_comVCRIGHT1rRSTPS_s "RCM2 ECU: a700 com vcright1r RSTPS s";
CM_ SG_ 1249 RCM2_a750_linInternalTimeout_s "RCM2 ECU: a750 lin internal timeout s";
CM_ SG_ 1249 RCM2_a799_internalFault_s "RCM2 ECU: a799 internal fault s";
CM_ SG_ 1249 RCM2_a800_crcFault_s "RCM2 ECU: a800 crc fault s";
CM_ SG_ 1249 RCM2_a801_parameterLayoutID_s "RCM2 ECU: a801 parameter layout ID s";
CM_ SG_ 1249 RCM2_a802_parameterTransferID_s "RCM2 ECU: a802 parameter transfer ID s";
CM_ SG_ 1249 RCM2_a803_algoVerifySensorID_s "RCM2 ECU: a803 algo verify sensor ID s";
CM_ SG_ 1249 RCM2_a804_configDataInconsistent "RCM2 ECU: a804 config data inconsistent s";
CM_ SG_ 1249 RCM2_a805_swVersionWrong_s "RCM2 ECU: a805 sw version wrong s";
CM_ SG_ 1249 RCM2_a806_configVINnotLearned_s "RCM2 ECU: a806 config VI nnot learned s";
CM_ SG_ 1249 RCM2_a807_configVINmismatch_s "RCM2 ECU: a807 config VI nmismatch s";
CM_ SG_ 1249 RCM2_a808_configDriveNotLearned_ "RCM2 ECU: a808 config drive not learned s";
CM_ SG_ 1249 RCM2_a809_configDriveMismatch_s "RCM2 ECU: a809 config drive mismatch s";
CM_ SG_ 1249 RCM2_a810_bootUpActionFailure_s "RCM2 ECU: a810 boot up action failure s";
CM_ SG_ 1249 RCM2_a815_upFrntPedProMLSht2Gnd_ "RCM2 ECU: a815 up frnt ped pro ML sht2 gnd s";
CM_ SG_ 1249 RCM2_a816_upFrntPedProMLSht2Bat_ "RCM2 ECU: a816 up frnt ped pro ML sht2 bat s";
CM_ SG_ 1249 RCM2_a817_upFrntPedProMLOpen_s "RCM2 ECU: a817 up frnt ped pro ML open s";
CM_ SG_ 1249 RCM2_a818_upFrntPedProMLCrssCoup "RCM2 ECU: a818 up frnt ped pro ML crss coup s";
CM_ SG_ 1249 RCM2_a819_upFrntPedProMLCommErr_ "RCM2 ECU: a819 up frnt ped pro ML comm err s";
CM_ SG_ 1249 RCM2_a820_upFrntPedProMLIntTyp_s "RCM2 ECU: a820 up frnt ped pro ML int typ s";
CM_ SG_ 1249 RCM2_a821_upFrntPedProMLConfig_s "RCM2 ECU: a821 up frnt ped pro ML config s";
CM_ SG_ 1249 RCM2_a822_upFrntPedProMLDefect_s "RCM2 ECU: a822 up frnt ped pro ML defect s";
CM_ SG_ 1249 RCM2_a823_upFrntPedProMLSigMon_s "RCM2 ECU: a823 up frnt ped pro ML sig mon s";
CM_ SG_ 1249 RCM2_a824_upFrntPedProMRSht2Gnd_ "RCM2 ECU: a824 up frnt ped pro MR sht2 gnd s";
CM_ SG_ 1249 RCM2_a825_upFrntPedProMRSht2Bat_ "RCM2 ECU: a825 up frnt ped pro MR sht2 bat s";
CM_ SG_ 1249 RCM2_a826_upFrntPedProMROpen_s "RCM2 ECU: a826 up frnt ped pro MR open s";
CM_ SG_ 1249 RCM2_a827_upFrntPedProMRCrssCoup "RCM2 ECU: a827 up frnt ped pro MR crss coup s";
CM_ SG_ 1249 RCM2_a828_upFrntPedProMRCommErr_ "RCM2 ECU: a828 up frnt ped pro MR comm err s";
CM_ SG_ 1249 RCM2_a829_upFrntPedProMRIntTyp_s "RCM2 ECU: a829 up frnt ped pro MR int typ s";
CM_ SG_ 1249 RCM2_a830_upFrntPedProMRConfig_s "RCM2 ECU: a830 up frnt ped pro MR config s";
CM_ SG_ 1249 RCM2_a831_upFrntPedProMRDefect_s "RCM2 ECU: a831 up frnt ped pro MR defect s";
CM_ SG_ 1249 RCM2_a832_upFrntPedProMRSigMon_s "RCM2 ECU: a832 up frnt ped pro MR sig mon s";
CM_ SG_ 1249 RCM2_a833_pretenShldCSht2Gnd_s "RCM2 ECU: a833 preten shld c sht2 gnd s";
CM_ SG_ 1249 RCM2_a834_pretenShldCSht2Bat_s "RCM2 ECU: a834 preten shld c sht2 bat s";
CM_ SG_ 1249 RCM2_a835_pretenShldCOpen_s "RCM2 ECU: a835 preten shld c open s";
CM_ SG_ 1249 RCM2_a836_pretenShldCShort_s "RCM2 ECU: a836 preten shld c short s";
CM_ SG_ 1249 RCM2_a837_pretenShldCCrossC_s "RCM2 ECU: a837 preten shld c cross c s";
CM_ SG_ 1249 RCM2_a838_pretenShldCConfig_s "RCM2 ECU: a838 preten shld c config s";
CM_ SG_ 1249 RCM2_a839_preten2ndRowCSht2Gnd_s "RCM2 ECU: a839 preten2nd row c sht2 gnd s";
CM_ SG_ 1249 RCM2_a840_preten2ndRowCSht2Bat_s "RCM2 ECU: a840 preten2nd row c sht2 bat s";
CM_ SG_ 1249 RCM2_a841_preten2ndRowCOpen_s "RCM2 ECU: a841 preten2nd row c open s";
CM_ SG_ 1249 RCM2_a842_preten2ndRowCShort_s "RCM2 ECU: a842 preten2nd row c short s";
CM_ SG_ 1249 RCM2_a843_preten2ndRowCCrssCoup_ "RCM2 ECU: a843 preten2nd row c crss coup s";
CM_ SG_ 1249 RCM2_a844_preten2ndRowCConfig_s "RCM2 ECU: a844 preten2nd row c config s";
CM_ SG_ 1249 RCM2_a852_autarkyEvent_s "RCM2 ECU: a852 autarky event s";
CM_ SG_ 1249 RCM2_a853_ConfigParametersIncons "RCM2 ECU: a853 config parameters inconsistent s";
CM_ SG_ 1249 RCM2_a854_ConfigParametersNotLea "RCM2 ECU: a854 config parameters not learned s";
CM_ SG_ 1249 RCM2_a857_comVCLEFT2rCBuckle_s "RCM2 ECU: a857 com vcleft2r c buckle s";
CM_ SG_ 1249 RCM2_a861_typeApprovalStringNotL "RCM2 ECU: a861 type approval string not learned s";
CM_ SG_ 1249 RCM2_a868_headAB3rdRowRSht2Gnd_s "RCM2 ECU: a868 head ab3rd row r sht2 gnd s";
CM_ SG_ 1249 RCM2_a869_headAB3rdRowRSht2Bat_s "RCM2 ECU: a869 head ab3rd row r sht2 bat s";
CM_ SG_ 1249 RCM2_a870_headAB3rdRowROpen_s "RCM2 ECU: a870 head ab3rd row r open s";
CM_ SG_ 1249 RCM2_a871_headAB3rdRowRShort_s "RCM2 ECU: a871 head ab3rd row r short s";
CM_ SG_ 1249 RCM2_a872_headAB3rdRowRCrossC_s "RCM2 ECU: a872 head ab3rd row r cross c s";
CM_ SG_ 1249 RCM2_a873_headAB3rdRowRConfig_s "RCM2 ECU: a873 head ab3rd row r config s";
CM_ SG_ 1249 RCM2_a874_headAB3rdRowLSht2Gnd_s "RCM2 ECU: a874 head ab3rd row l sht2 gnd s";
CM_ SG_ 1249 RCM2_a875_headAB3rdRowLSht2Bat_s "RCM2 ECU: a875 head ab3rd row l sht2 bat s";
CM_ SG_ 1249 RCM2_a876_headAB3rdRowLOpen_s "RCM2 ECU: a876 head ab3rd row l open s";
CM_ SG_ 1249 RCM2_a877_headAB3rdRowLShort_s "RCM2 ECU: a877 head ab3rd row l short s";
CM_ SG_ 1249 RCM2_a878_headAB3rdRowLCrossC_s "RCM2 ECU: a878 head ab3rd row l cross c s";
CM_ SG_ 1249 RCM2_a879_headAB3rdRowLConfig_s "RCM2 ECU: a879 head ab3rd row l config s";
BA_DEF_ BO_ "GenMsgCycleTime" INT 0 3600000;
BA_DEF_ BO_ "GenMsgSendType" ENUM "Cyclic","NotUsed","NotUsed","NotUsed","NotUsed","NotUsed","NotUsed","IfActive","NoMsgSendType","NotUsed";
BA_DEF_ BO_ "VFrameFormat" ENUM "StandardCAN","ExtendedCAN","reserved","J1939PG","reserved","reserved","reserved","reserved","reserved","reserved","reserved","reserved","reserved","reserved","StandardCAN_FD","ExtendedCAN_FD";
BA_DEF_ BO_ "CANFD_BRS" ENUM "0","1";
BA_DEF_ SG_ "GenSigSNA" STRING;
BA_DEF_ SG_ "SystemSignalLongSymbol" STRING;
BA_DEF_ SG_ "Confidence" ENUM "validated","plausible","layout-only","contradicted";
BA_DEF_DEF_ "GenMsgCycleTime" 0;
BA_DEF_DEF_ "GenMsgSendType" "NoMsgSendType";
BA_DEF_DEF_ "VFrameFormat" "StandardCAN";
BA_DEF_DEF_ "CANFD_BRS" "1";
BA_DEF_DEF_ "GenSigSNA" "";
BA_DEF_DEF_ "SystemSignalLongSymbol" "";
BA_DEF_DEF_ "Confidence" "layout-only";
BA_ "GenMsgCycleTime" BO_ 896 1000;
BA_ "GenMsgSendType" BO_ 896 0;
BA_ "GenMsgCycleTime" BO_ 2020 1000;
BA_ "GenMsgSendType" BO_ 2020 0;
BA_ "GenMsgCycleTime" BO_ 463 10;
BA_ "GenMsgSendType" BO_ 463 0;
BA_ "GenMsgCycleTime" BO_ 2038 20;
BA_ "GenMsgSendType" BO_ 2038 0;
BA_ "GenMsgCycleTime" BO_ 519 100;
BA_ "GenMsgSendType" BO_ 519 0;
BA_ "GenMsgCycleTime" BO_ 837 1000;
BA_ "GenMsgSendType" BO_ 837 0;
BA_ "GenMsgCycleTime" BO_ 2019 100;
BA_ "GenMsgSendType" BO_ 2019 0;
BA_ "GenMsgCycleTime" BO_ 1282 1000;
BA_ "GenMsgSendType" BO_ 1282 0;
BA_ "GenMsgCycleTime" BO_ 1329 1000;
BA_ "GenMsgSendType" BO_ 1329 0;
BA_ "SystemSignalLongSymbol" SG_ 896 PM_a070_brakeTorqueSplitMonitorT "PM_a070_brakeTorqueSplitMonitorTrip";
BA_ "SystemSignalLongSymbol" SG_ 896 PM_a072_brakeTorqueCommandInterf "PM_a072_brakeTorqueCommandInterface";
BA_ "SystemSignalLongSymbol" SG_ 896 PM_a086_exceptionUndefinedInstru "PM_a086_exceptionUndefinedInstruction";
BA_ "SystemSignalLongSymbol" SG_ 896 PM_a095_ITPMSTimeoutGNSSConverge "PM_a095_ITPMSTimeoutGNSSConvergence";
BA_ "SystemSignalLongSymbol" SG_ 896 PM_a096_ITPMSConvergedGNSSAbsRad "PM_a096_ITPMSConvergedGNSSAbsRadiusTimes";
BA_ "SystemSignalLongSymbol" SG_ 896 PM_a110_indirectTPMSSoftWarningF "PM_a110_indirectTPMSSoftWarningFrontLeft";
BA_ "SystemSignalLongSymbol" SG_ 896 PM_a111_indirectTPMSSoftWarningF "PM_a111_indirectTPMSSoftWarningFrontRight";
BA_ "SystemSignalLongSymbol" SG_ 896 PM_a112_indirectTPMSSoftWarningR "PM_a112_indirectTPMSSoftWarningRearLeft";
BA_ "SystemSignalLongSymbol" SG_ 896 PM_a113_indirectTPMSSoftWarningR "PM_a113_indirectTPMSSoftWarningRearRight";
BA_ "SystemSignalLongSymbol" SG_ 896 PM_a114_indirectTPMSHardWarningF "PM_a114_indirectTPMSHardWarningFrontLeft";
BA_ "SystemSignalLongSymbol" SG_ 896 PM_a115_indirectTPMSHardWarningF "PM_a115_indirectTPMSHardWarningFrontRight";
BA_ "SystemSignalLongSymbol" SG_ 896 PM_a116_indirectTPMSHardWarningR "PM_a116_indirectTPMSHardWarningRearLeft";
BA_ "SystemSignalLongSymbol" SG_ 896 PM_a117_indirectTPMSHardWarningR "PM_a117_indirectTPMSHardWarningRearRight";
BA_ "Confidence" SG_ 2020 PM_infoIndex 1;
BA_ "Confidence" SG_ 2020 PM_buildType 0;
BA_ "Confidence" SG_ 2020 PM_buildConfigurationId 0;
BA_ "Confidence" SG_ 2020 PM_hardwareId 0;
BA_ "Confidence" SG_ 2020 PM_deviceFused 0;
BA_ "Confidence" SG_ 2020 PM_componentId 0;
BA_ "Confidence" SG_ 2020 PM_pcbaId 0;
BA_ "Confidence" SG_ 2020 PM_assemblyId 0;
BA_ "Confidence" SG_ 2020 PM_usageId 0;
BA_ "Confidence" SG_ 2020 PM_subUsageId 0;
BA_ "Confidence" SG_ 2020 PM_applicationCrc 0;
BA_ "Confidence" SG_ 2020 PM_bootGitHash 0;
BA_ "Confidence" SG_ 463 PM_torqueCheckState 1;
BA_ "Confidence" SG_ 463 PM_limpRequest 1;
BA_ "Confidence" SG_ 463 PM_torqueCommand 1;
BA_ "GenSigSNA" SG_ 463 PM_torqueCommand "4096";
BA_ "Confidence" SG_ 463 PM_torqueState 1;
BA_ "Confidence" SG_ 463 PM_hvilSystemStatus 1;
BA_ "GenSigSNA" SG_ 463 PM_hvilSystemStatus "3";
BA_ "Confidence" SG_ 463 PM_sysElecPower 1;
BA_ "GenSigSNA" SG_ 463 PM_sysElecPower "1024";
BA_ "Confidence" SG_ 2038 PM_vdcDebugSelector 1;
BA_ "Confidence" SG_ 2038 PM_VDCA_TCSlipTargetMod_RA_Fwd 0;
BA_ "Confidence" SG_ 2038 PM_VDCA_TCSlipTargetMod_RA_Rwd 0;
BA_ "Confidence" SG_ 2038 PM_VSE_forceY_RA 0;
BA_ "Confidence" SG_ 2038 PM_VDCT_observerSlipAngle_RA 0;
BA_ "Confidence" SG_ 2038 PM_VSE_muVehicleFxLow 0;
BA_ "Confidence" SG_ 2038 PM_VE_fxmFres 0;
BA_ "Confidence" SG_ 2038 PM_VE_fxAccelMass 0;
BA_ "Confidence" SG_ 2038 PM_VE_vxDotGrade 0;
BA_ "Confidence" SG_ 2038 PM_VE_betaEst 0;
BA_ "Confidence" SG_ 2038 PM_VSE_muVehicleFxHigh 0;
BA_ "Confidence" SG_ 2038 PM_VSE_muVehicleDecLeakRate 0;
BA_ "Confidence" SG_ 2038 PM_VSE_muVehicleLearnDown 0;
BA_ "Confidence" SG_ 2038 PM_VSE_muVehicleDecFilter 0;
BA_ "Confidence" SG_ 2038 PM_VSE_muVehicleLatDecLeakRate 0;
BA_ "Confidence" SG_ 2038 PM_VSE_splitMuProbability 0;
BA_ "Confidence" SG_ 2038 PM_VSE_splitMuTotalMz 0;
BA_ "Confidence" SG_ 2038 PM_VSE_attitudeBankAngle 0;
BA_ "Confidence" SG_ 2038 PM_VSE_attitudeDBetaInControl 0;
BA_ "Confidence" SG_ 2038 PM_VSE_roadWheelAngleAverage 0;
BA_ "Confidence" SG_ 519 PTC_leftFlagFault 0;
BA_ "Confidence" SG_ 519 PTC_rightFlagFault 0;
BA_ "Confidence" SG_ 519 PTC_leftPowerDerating 0;
BA_ "Confidence" SG_ 519 PTC_rightPowerDerating 0;
BA_ "Confidence" SG_ 519 PTC_ocpEvent 0;
BA_ "Confidence" SG_ 519 PTC_leftDutyFeedback 0;
BA_ "Confidence" SG_ 519 PTC_rightDutyFeedback 0;
BA_ "Confidence" SG_ 519 PTC_leftPowerHV 0;
BA_ "Confidence" SG_ 519 PTC_rightPowerHV 0;
BA_ "Confidence" SG_ 519 PTC_leftTempEstOutlet 0;
BA_ "Confidence" SG_ 519 PTC_rightTempEstOutlet 0;
BA_ "Confidence" SG_ 519 PTC_tliErrorCount 0;
BA_ "Confidence" SG_ 519 PTC_tliEvent 0;
BA_ "Confidence" SG_ 519 PTC_tliSource 0;
BA_ "Confidence" SG_ 837 PTC_infoIndex 1;
BA_ "Confidence" SG_ 837 PTC_infoBuildType 0;
BA_ "Confidence" SG_ 837 PTC_infoBuildConfigId 0;
BA_ "Confidence" SG_ 837 PTC_infoHardwareId 0;
BA_ "Confidence" SG_ 837 PTC_infoComponentId 0;
BA_ "Confidence" SG_ 837 PTC_infoPcbaId 0;
BA_ "Confidence" SG_ 837 PTC_infoAssemblyId 0;
BA_ "GenSigSNA" SG_ 837 PTC_infoAssemblyId "255";
BA_ "Confidence" SG_ 837 PTC_infoUsageId 0;
BA_ "Confidence" SG_ 837 PTC_infoSubUsageId 0;
BA_ "Confidence" SG_ 837 PTC_infoPlatformType 0;
BA_ "Confidence" SG_ 837 PTC_infoAppCrc 0;
BA_ "Confidence" SG_ 837 PTC_infoBootUdsProtoVersion 0;
BA_ "Confidence" SG_ 837 PTC_infoBootCrc 0;
BA_ "Confidence" SG_ 2019 PTC_leftTempIGBT 0;
BA_ "Confidence" SG_ 2019 PTC_tempOCP 0;
BA_ "Confidence" SG_ 2019 PTC_rightTempIGBT 0;
BA_ "Confidence" SG_ 2019 PTC_tempPCB 0;
BA_ "Confidence" SG_ 2019 PTC_voltageHV 0;
BA_ "Confidence" SG_ 2019 PTC_leftCurrentHV 0;
BA_ "Confidence" SG_ 2019 PTC_rightCurrentHV 0;
BA_ "Confidence" SG_ 1365 RADC_alertID 1;
BA_ "Confidence" SG_ 1365 RADC_alertState 1;
BA_ "Confidence" SG_ 1365 RADC_a002_ecuAdcErrType 1;
BA_ "Confidence" SG_ 1365 RADC_a008_interLockErrType 1;
BA_ "Confidence" SG_ 1365 RADC_a011_ecuMcemErrType 1;
BA_ "Confidence" SG_ 1365 RADC_a013_ecuWdgErrType 1;
BA_ "Confidence" SG_ 1365 RADC_a016_adcOverVoltType 1;
BA_ "Confidence" SG_ 1365 RADC_a016_adcVoltage 1;
BA_ "Confidence" SG_ 1365 RADC_a017_adcUnderVoltType 1;
BA_ "Confidence" SG_ 1365 RADC_a017_adcVoltage 1;
BA_ "Confidence" SG_ 1365 RADC_a019_internalSWFaultType 1;
BA_ "Confidence" SG_ 1365 RADC_a019_internalSWFaultCoreID 1;
BA_ "Confidence" SG_ 1365 RADC_a020_ecuTemp 1;
BA_ "Confidence" SG_ 1365 RADC_a023_ecuTemp 1;
BA_ "Confidence" SG_ 1365 RADC_a025_ecuVoltage 1;
BA_ "Confidence" SG_ 1365 RADC_a026_ecuVoltage 1;
BA_ "Confidence" SG_ 1365 RADC_a027_nvmFailureType 1;
BA_ "Confidence" SG_ 1365 RADC_a028_rfComRegCheckFail 1;
BA_ "Confidence" SG_ 1365 RADC_a029_rhcChirpMonErrType 1;
BA_ "Confidence" SG_ 1365 RADC_a029_rhcRxLongTermErrType 1;
BA_ "Confidence" SG_ 1365 RADC_a029_rhcRxErrType 1;
BA_ "Confidence" SG_ 1365 RADC_a029_rhcVcoPowerErrType 1;
BA_ "Confidence" SG_ 1365 RADC_a029_rhcSp1ErrType 1;
BA_ "Confidence" SG_ 1365 RADC_a029_rhcFdcErrType 1;
BA_ "Confidence" SG_ 1365 RADC_a030_rspErrType 1;
BA_ "Confidence" SG_ 1365 RADC_a031_horizMisalignAngle 1;
BA_ "Confidence" SG_ 1365 RADC_a031_vertMisalignAngle 1;
BA_ "Confidence" SG_ 1365 RADC_a032_blockageType 1;
BA_ "Confidence" SG_ 1365 RADC_a032_block_SPMBlockageState 1;
BA_ "Confidence" SG_ 1365 RADC_a032_block_SPMSelfTestState 1;
BA_ "Confidence" SG_ 1365 RADC_a032_block_ucEstiRange 1;
BA_ "Confidence" SG_ 1365 RADC_a041_vinErrType 1;
BA_ "Confidence" SG_ 1365 RADC_a042_carConfigErrType 1;
BA_ "Confidence" SG_ 1365 RADC_a043_inertialSignalsErrType 1;
BA_ "Confidence" SG_ 1365 RADC_a044_stwAngleErrType 1;
BA_ "Confidence" SG_ 1365 RADC_a045_vehicleStateErrType 1;
BA_ "Confidence" SG_ 1365 RADC_a046_wheelSpeedsErrType 1;
BA_ "Confidence" SG_ 1365 RADC_a047_chassisTypeExp 1;
BA_ "GenSigSNA" SG_ 1365 RADC_a047_chassisTypeExp "7";
BA_ "Confidence" SG_ 1365 RADC_a047_chassisTypeRx 1;
BA_ "GenSigSNA" SG_ 1365 RADC_a047_chassisTypeRx "7";
BA_ "Confidence" SG_ 1365 RADC_a048_airSuspensionExp 1;
BA_ "GenSigSNA" SG_ 1365 RADC_a048_airSuspensionExp "7";
BA_ "Confidence" SG_ 1365 RADC_a048_airSuspensionRx 1;
BA_ "GenSigSNA" SG_ 1365 RADC_a048_airSuspensionRx "7";
BA_ "Confidence" SG_ 1365 RADC_a049_fourWheelDriveExp 1;
BA_ "GenSigSNA" SG_ 1365 RADC_a049_fourWheelDriveExp "3";
BA_ "Confidence" SG_ 1365 RADC_a049_fourWheelDriveRx 1;
BA_ "GenSigSNA" SG_ 1365 RADC_a049_fourWheelDriveRx "3";
BA_ "Confidence" SG_ 1365 RADC_a051_epasTypeExp 1;
BA_ "GenSigSNA" SG_ 1365 RADC_a051_epasTypeExp "7";
BA_ "Confidence" SG_ 1365 RADC_a051_epasTypeRx 1;
BA_ "GenSigSNA" SG_ 1365 RADC_a051_epasTypeRx "7";
BA_ "Confidence" SG_ 1365 RADC_a052_radarPositionExp 1;
BA_ "GenSigSNA" SG_ 1365 RADC_a052_radarPositionExp "7";
BA_ "Confidence" SG_ 1365 RADC_a052_radarPositionRx 1;
BA_ "GenSigSNA" SG_ 1365 RADC_a052_radarPositionRx "7";
BA_ "Confidence" SG_ 1365 RADC_a054_block_RoadbeamTimeCnt 1;
BA_ "Confidence" SG_ 1365 RADC_a055_block_usTimeoutWayCnt 1;
BA_ "Confidence" SG_ 1365 RADC_a055_block_ucTimeoutTimeCnt 1;
BA_ "SystemSignalLongSymbol" SG_ 1365 RADC_a055_bblock_ucTimeoutBlkPro "RADC_a055_bblock_ucTimeoutBlkProb";
BA_ "Confidence" SG_ 1365 RADC_a055_block_usFullBlkTimer 1;
BA_ "Confidence" SG_ 1329 RADC_infoIndex 1;
BA_ "Confidence" SG_ 1329 RADC_infoBuildType 0;
BA_ "Confidence" SG_ 1329 RADC_infoBuildConfigID 0;
BA_ "Confidence" SG_ 1329 RADC_infoHardwareID 0;
BA_ "Confidence" SG_ 1329 RADC_infoComponentID 0;
BA_ "Confidence" SG_ 1329 RADC_infoPcbaID 0;
BA_ "Confidence" SG_ 1329 RADC_infoAssemblyID 0;
BA_ "Confidence" SG_ 1329 RADC_infoUsageID 0;
BA_ "Confidence" SG_ 1329 RADC_infoSubUsageID 0;
BA_ "Confidence" SG_ 1329 RADC_infoApplicationCRC 0;
BA_ "Confidence" SG_ 1329 RADC_infoPlatformType 0;
BA_ "Confidence" SG_ 1329 RADC_infoMajorVersion 0;
BA_ "Confidence" SG_ 1329 RADC_infoBranchOrigin 0;
BA_ "Confidence" SG_ 1329 RADC_infoMaturity 0;
BA_ "Confidence" SG_ 1329 RADC_infoHardwareRevision 0;
BA_ "Confidence" SG_ 1329 RADC_infoBootUdsProtoVersion 0;
BA_ "Confidence" SG_ 1329 RADC_infoBootloaderCRC 0;
BA_ "Confidence" SG_ 1249 RCM2_alertID 1;
BA_ "Confidence" SG_ 1249 RCM2_alertState 1;
BA_ "Confidence" SG_ 1249 RCM2_eventArmStatus 1;
BA_ "Confidence" SG_ 1249 RCM2_eventFactoryMode 1;
BA_ "Confidence" SG_ 1249 RCM2_eventDriveOrientation 1;
BA_ "Confidence" SG_ 1249 RCM2_eventIDFsignal 1;
BA_ "Confidence" SG_ 1249 RCM2_eventFrontLeftSeatbelt 1;
BA_ "Confidence" SG_ 1249 RCM2_eventFrontRightSeatbelt 1;
BA_ "Confidence" SG_ 1249 RCM2_eventVehicleSpeed 1;
BA_ "Confidence" SG_ 1249 RCM2_eventDriverBrakeApply 1;
BA_ "GenSigSNA" SG_ 1249 RCM2_eventDriverBrakeApply "3";
BA_ "Confidence" SG_ 1249 RCM2_eventAccelPedalPos 1;
BA_ "GenSigSNA" SG_ 1249 RCM2_eventAccelPedalPos "255";
BA_ "SystemSignalLongSymbol" SG_ 1249 RCM2_a000_crashDetectedStaticRol "RCM2_a000_crashDetectedStaticRoll";
BA_ "SystemSignalLongSymbol" SG_ 1249 RCM2_a005_abuseImmunityThrshold_ "RCM2_a005_abuseImmunityThrshold_s";
BA_ "SystemSignalLongSymbol" SG_ 1249 RCM2_a048_batteryVoltageTooHigh_ "RCM2_a048_batteryVoltageTooHigh_s";
BA_ "SystemSignalLongSymbol" SG_ 1249 RCM2_a074_passActiveVentSht2Gnd_ "RCM2_a074_passActiveVentSht2Gnd_s";
BA_ "SystemSignalLongSymbol" SG_ 1249 RCM2_a075_passActiveVentSht2Bat_ "RCM2_a075_passActiveVentSht2Bat_s";
BA_ "SystemSignalLongSymbol" SG_ 1249 RCM2_a078_passActiveVentCrssCoup "RCM2_a078_passActiveVentCrssCoup_s";
BA_ "SystemSignalLongSymbol" SG_ 1249 RCM2_a080_pretenShldLeftSht2Gnd_ "RCM2_a080_pretenShldLeftSht2Gnd_s";
BA_ "SystemSignalLongSymbol" SG_ 1249 RCM2_a081_pretenShldLeftSht2Bat_ "RCM2_a081_pretenShldLeftSht2Bat_s";
BA_ "SystemSignalLongSymbol" SG_ 1249 RCM2_a086_pretenShldRightSht2Gnd "RCM2_a086_pretenShldRightSht2Gnd_s";
BA_ "SystemSignalLongSymbol" SG_ 1249 RCM2_a087_pretenShldRightSht2Bat "RCM2_a087_pretenShldRightSht2Bat_s";
BA_ "SystemSignalLongSymbol" SG_ 1249 RCM2_a090_pretenShldRightCrssCou "RCM2_a090_pretenShldRightCrssCou_s";
BA_ "SystemSignalLongSymbol" SG_ 1249 RCM2_a091_pretenShldRightConfig_ "RCM2_a091_pretenShldRightConfig_s";
BA_ "SystemSignalLongSymbol" SG_ 1249 RCM2_a096_pretenLapLeftCrssCoup_ "RCM2_a096_pretenLapLeftCrssCoup_s";
BA_ "SystemSignalLongSymbol" SG_ 1249 RCM2_a098_pretenLapRightSht2Gnd_ "RCM2_a098_pretenLapRightSht2Gnd_s";
BA_ "SystemSignalLongSymbol" SG_ 1249 RCM2_a099_pretenLapRightSht2Bat_ "RCM2_a099_pretenLapRightSht2Bat_s";
BA_ "SystemSignalLongSymbol" SG_ 1249 RCM2_a102_pretenLapRightCrssCoup "RCM2_a102_pretenLapRightCrssCoup_s";
BA_ "SystemSignalLongSymbol" SG_ 1249 RCM2_a132_sideAB1stRowLCrssCoup_ "RCM2_a132_sideAB1stRowLCrssCoup_s";
BA_ "SystemSignalLongSymbol" SG_ 1249 RCM2_a138_sideAB1stRowRCrssCoup_ "RCM2_a138_sideAB1stRowRCrssCoup_s";
BA_ "SystemSignalLongSymbol" SG_ 1249 RCM2_a162_preten2ndRowLCrssCoup_ "RCM2_a162_preten2ndRowLCrssCoup_s";
BA_ "SystemSignalLongSymbol" SG_ 1249 RCM2_a168_preten2ndRowRCrssCoup_ "RCM2_a168_preten2ndRowRCrssCoup_s";
BA_ "SystemSignalLongSymbol" SG_ 1249 RCM2_a186_hoodActuatorRCrssCoup_ "RCM2_a186_hoodActuatorRCrssCoup_s";
BA_ "SystemSignalLongSymbol" SG_ 1249 RCM2_a192_hoodActuatorLCrssCoup_ "RCM2_a192_hoodActuatorLCrssCoup_s";
BA_ "SystemSignalLongSymbol" SG_ 1249 RCM2_a210_sideAB2ndRowLCrssCoup_ "RCM2_a210_sideAB2ndRowLCrssCoup_s";
BA_ "SystemSignalLongSymbol" SG_ 1249 RCM2_a216_sideAB2ndRowRCrssCoup_ "RCM2_a216_sideAB2ndRowRCrssCoup_s";
BA_ "SystemSignalLongSymbol" SG_ 1249 RCM2_a264_imuYawR8OffCompPosLife "RCM2_a264_imuYawR8OffCompPosLife_s";
BA_ "SystemSignalLongSymbol" SG_ 1249 RCM2_a265_imuYawR8OffCompNegLife "RCM2_a265_imuYawR8OffCompNegLife_s";
BA_ "SystemSignalLongSymbol" SG_ 1249 RCM2_a266_imuYawR8OffCompPosFLDC "RCM2_a266_imuYawR8OffCompPosFLDC_s";
BA_ "SystemSignalLongSymbol" SG_ 1249 RCM2_a267_imuYawR8OffCompNegFLDC "RCM2_a267_imuYawR8OffCompNegFLDC_s";
BA_ "SystemSignalLongSymbol" SG_ 1249 RCM2_a268_imuYawR8OffCompPosSLDC "RCM2_a268_imuYawR8OffCompPosSLDC_s";
BA_ "SystemSignalLongSymbol" SG_ 1249 RCM2_a269_imuYawR8OffCompNegSLDC "RCM2_a269_imuYawR8OffCompNegSLDC_s";
BA_ "SystemSignalLongSymbol" SG_ 1249 RCM2_a270_imuPtchR8OffCompPosLif "RCM2_a270_imuPtchR8OffCompPosLife_s";
BA_ "SystemSignalLongSymbol" SG_ 1249 RCM2_a271_imuPtchR8OffCompNegLif "RCM2_a271_imuPtchR8OffCompNegLife_s";
BA_ "SystemSignalLongSymbol" SG_ 1249 RCM2_a272_imuPtchR8OffCompPosFLD "RCM2_a272_imuPtchR8OffCompPosFLDC_s";
BA_ "SystemSignalLongSymbol" SG_ 1249 RCM2_a273_imuPtchR8OffCompNegFLD "RCM2_a273_imuPtchR8OffCompNegFLDC_s";
BA_ "SystemSignalLongSymbol" SG_ 1249 RCM2_a274_imuPtchR8OffCompPosSLD "RCM2_a274_imuPtchR8OffCompPosSLDC_s";
BA_ "SystemSignalLongSymbol" SG_ 1249 RCM2_a275_imuPtchR8OffCompNegSLD "RCM2_a275_imuPtchR8OffCompNegSLDC_s";
BA_ "SystemSignalLongSymbol" SG_ 1249 RCM2_a276_imuRollR8OffCompPosLif "RCM2_a276_imuRollR8OffCompPosLife_s";
BA_ "SystemSignalLongSymbol" SG_ 1249 RCM2_a277_imuRollR8OffCompNegLif "RCM2_a277_imuRollR8OffCompNegLife_s";
BA_ "SystemSignalLongSymbol" SG_ 1249 RCM2_a278_imuRollR8OffCompPosFLD "RCM2_a278_imuRollR8OffCompPosFLDC_s";
BA_ "SystemSignalLongSymbol" SG_ 1249 RCM2_a279_imuRollR8OffCompNegFLD "RCM2_a279_imuRollR8OffCompNegFLDC_s";
BA_ "SystemSignalLongSymbol" SG_ 1249 RCM2_a280_imuRollR8OffCompPosSLD "RCM2_a280_imuRollR8OffCompPosSLDC_s";
BA_ "SystemSignalLongSymbol" SG_ 1249 RCM2_a281_imuRollR8OffCompNegSLD "RCM2_a281_imuRollR8OffCompNegSLDC_s";
BA_ "SystemSignalLongSymbol" SG_ 1249 RCM2_a282_imuLongAOffCompPosLife "RCM2_a282_imuLongAOffCompPosLife_s";
BA_ "SystemSignalLongSymbol" SG_ 1249 RCM2_a283_imuLongAOffCompNegLife "RCM2_a283_imuLongAOffCompNegLife_s";
BA_ "SystemSignalLongSymbol" SG_ 1249 RCM2_a284_imuLongAOffCompPosFLDC "RCM2_a284_imuLongAOffCompPosFLDC_s";
BA_ "SystemSignalLongSymbol" SG_ 1249 RCM2_a285_imuLongAOffCompNegFLDC "RCM2_a285_imuLongAOffCompNegFLDC_s";
BA_ "SystemSignalLongSymbol" SG_ 1249 RCM2_a286_imuLongAOffCompPosSLDC "RCM2_a286_imuLongAOffCompPosSLDC_s";
BA_ "SystemSignalLongSymbol" SG_ 1249 RCM2_a287_imuLongAOffCompNegSLDC "RCM2_a287_imuLongAOffCompNegSLDC_s";
BA_ "SystemSignalLongSymbol" SG_ 1249 RCM2_a288_imuLatAcOffCompPosLife "RCM2_a288_imuLatAcOffCompPosLife_s";
BA_ "SystemSignalLongSymbol" SG_ 1249 RCM2_a289_imuLatAcOffCompNegLife "RCM2_a289_imuLatAcOffCompNegLife_s";
BA_ "SystemSignalLongSymbol" SG_ 1249 RCM2_a290_imuLatAcOffCompPosFLDC "RCM2_a290_imuLatAcOffCompPosFLDC_s";
BA_ "SystemSignalLongSymbol" SG_ 1249 RCM2_a291_imuLatAcOffCompNegFLDC "RCM2_a291_imuLatAcOffCompNegFLDC_s";
BA_ "SystemSignalLongSymbol" SG_ 1249 RCM2_a292_imuLatAcOffCompPosSLDC "RCM2_a292_imuLatAcOffCompPosSLDC_s";
BA_ "SystemSignalLongSymbol" SG_ 1249 RCM2_a293_imuLatAcOffCompNegSLDC "RCM2_a293_imuLatAcOffCompNegSLDC_s";
BA_ "SystemSignalLongSymbol" SG_ 1249 RCM2_a294_imuVertAOffCompPosLife "RCM2_a294_imuVertAOffCompPosLife_s";
BA_ "SystemSignalLongSymbol" SG_ 1249 RCM2_a295_imuVertAOffCompNegLife "RCM2_a295_imuVertAOffCompNegLife_s";
BA_ "SystemSignalLongSymbol" SG_ 1249 RCM2_a296_imuVertAOffCompPosFLDC "RCM2_a296_imuVertAOffCompPosFLDC_s";
BA_ "SystemSignalLongSymbol" SG_ 1249 RCM2_a297_imuVertAOffCompNegFLDC "RCM2_a297_imuVertAOffCompNegFLDC_s";
BA_ "SystemSignalLongSymbol" SG_ 1249 RCM2_a298_imuVertAOffCompPosSLDC "RCM2_a298_imuVertAOffCompPosSLDC_s";
BA_ "SystemSignalLongSymbol" SG_ 1249 RCM2_a299_imuVertAOffCompNegSLDC "RCM2_a299_imuVertAOffCompNegSLDC_s";
BA_ "SystemSignalLongSymbol" SG_ 1249 RCM2_a309_imuPitchR8SnsrPermInit "RCM2_a309_imuPitchR8SnsrPermInit_s";
BA_ "SystemSignalLongSymbol" SG_ 1249 RCM2_a311_imuPitchR8ChnlMonTmpLF "RCM2_a311_imuPitchR8ChnlMonTmpLF_s";
BA_ "SystemSignalLongSymbol" SG_ 1249 RCM2_a313_imuRollR8SnsrPermInit_ "RCM2_a313_imuRollR8SnsrPermInit_s";
BA_ "SystemSignalLongSymbol" SG_ 1249 RCM2_a315_imuRollR8ChnlMonTmpLF_ "RCM2_a315_imuRollR8ChnlMonTmpLF_s";
BA_ "SystemSignalLongSymbol" SG_ 1249 RCM2_a323_imuCalibrationNotDone_ "RCM2_a323_imuCalibrationNotDone_s";
BA_ "SystemSignalLongSymbol" SG_ 1249 RCM2_a370_upFrntSnsrMidLSht2Gnd_ "RCM2_a370_upFrntSnsrMidLSht2Gnd_s";
BA_ "SystemSignalLongSymbol" SG_ 1249 RCM2_a371_upFrntSnsrMidLSht2Bat_ "RCM2_a371_upFrntSnsrMidLSht2Bat_s";
BA_ "SystemSignalLongSymbol" SG_ 1249 RCM2_a373_upFrntSnsrMidLCrssCoup "RCM2_a373_upFrntSnsrMidLCrssCoup_s";
BA_ "SystemSignalLongSymbol" SG_ 1249 RCM2_a374_upFrntSnsrMidLCommErr_ "RCM2_a374_upFrntSnsrMidLCommErr_s";
BA_ "SystemSignalLongSymbol" SG_ 1249 RCM2_a375_upFrntSnsrMidLInitTyp_ "RCM2_a375_upFrntSnsrMidLInitTyp_s";
BA_ "SystemSignalLongSymbol" SG_ 1249 RCM2_a380_upFrntSnsrMidRSht2Gnd_ "RCM2_a380_upFrntSnsrMidRSht2Gnd_s";
BA_ "SystemSignalLongSymbol" SG_ 1249 RCM2_a381_upFrntSnsrMidRSht2Bat_ "RCM2_a381_upFrntSnsrMidRSht2Bat_s";
BA_ "SystemSignalLongSymbol" SG_ 1249 RCM2_a383_upFrntSnsrMidRCrssCoup "RCM2_a383_upFrntSnsrMidRCrssCoup_s";
BA_ "SystemSignalLongSymbol" SG_ 1249 RCM2_a384_upFrntSnsrMidRCommErr_ "RCM2_a384_upFrntSnsrMidRCommErr_s";
BA_ "SystemSignalLongSymbol" SG_ 1249 RCM2_a385_upFrntSnsrMidRInitTyp_ "RCM2_a385_upFrntSnsrMidRInitTyp_s";
BA_ "SystemSignalLongSymbol" SG_ 1249 RCM2_a390_sideAccelBPilLSht2Gnd_ "RCM2_a390_sideAccelBPilLSht2Gnd_s";
BA_ "SystemSignalLongSymbol" SG_ 1249 RCM2_a391_sideAccelBPilLSht2Bat_ "RCM2_a391_sideAccelBPilLSht2Bat_s";
BA_ "SystemSignalLongSymbol" SG_ 1249 RCM2_a393_sideAccelBPilLCLosCoup "RCM2_a393_sideAccelBPilLCLosCoup_s";
BA_ "SystemSignalLongSymbol" SG_ 1249 RCM2_a394_sideAccelBPilLCommErr_ "RCM2_a394_sideAccelBPilLCommErr_s";
BA_ "SystemSignalLongSymbol" SG_ 1249 RCM2_a395_sideAccelBPilLInitTyp_ "RCM2_a395_sideAccelBPilLInitTyp_s";
BA_ "SystemSignalLongSymbol" SG_ 1249 RCM2_a400_sideAccelBPilRSht2Gnd_ "RCM2_a400_sideAccelBPilRSht2Gnd_s";
BA_ "SystemSignalLongSymbol" SG_ 1249 RCM2_a401_sideAccelBPilRSht2Bat_ "RCM2_a401_sideAccelBPilRSht2Bat_s";
BA_ "SystemSignalLongSymbol" SG_ 1249 RCM2_a403_sideAccelBPilRCrssCoup "RCM2_a403_sideAccelBPilRCrssCoup_s";
BA_ "SystemSignalLongSymbol" SG_ 1249 RCM2_a404_sideAccelBPilRCommErr_ "RCM2_a404_sideAccelBPilRCommErr_s";
BA_ "SystemSignalLongSymbol" SG_ 1249 RCM2_a405_sideAccelBPilRInitTyp_ "RCM2_a405_sideAccelBPilRInitTyp_s";
BA_ "SystemSignalLongSymbol" SG_ 1249 RCM2_a410_sideAccelCPilLSht2Gnd_ "RCM2_a410_sideAccelCPilLSht2Gnd_s";
BA_ "SystemSignalLongSymbol" SG_ 1249 RCM2_a411_sideAccelCPilLSht2Bat_ "RCM2_a411_sideAccelCPilLSht2Bat_s";
BA_ "SystemSignalLongSymbol" SG_ 1249 RCM2_a413_sideAccelCPilLCrssCoup "RCM2_a413_sideAccelCPilLCrssCoup_s";
BA_ "SystemSignalLongSymbol" SG_ 1249 RCM2_a414_sideAccelCPilLCommErr_ "RCM2_a414_sideAccelCPilLCommErr_s";
BA_ "SystemSignalLongSymbol" SG_ 1249 RCM2_a415_sideAccelCPilLInitTyp_ "RCM2_a415_sideAccelCPilLInitTyp_s";
BA_ "SystemSignalLongSymbol" SG_ 1249 RCM2_a420_sideAccelCPilRSht2Gnd_ "RCM2_a420_sideAccelCPilRSht2Gnd_s";
BA_ "SystemSignalLongSymbol" SG_ 1249 RCM2_a421_sideAccelCPilRSht2Bat_ "RCM2_a421_sideAccelCPilRSht2Bat_s";
BA_ "SystemSignalLongSymbol" SG_ 1249 RCM2_a423_sideAccelCPilRCrssCoup "RCM2_a423_sideAccelCPilRCrssCoup_s";
BA_ "SystemSignalLongSymbol" SG_ 1249 RCM2_a424_sideAccelCPilRCommErr_ "RCM2_a424_sideAccelCPilRCommErr_s";
BA_ "SystemSignalLongSymbol" SG_ 1249 RCM2_a425_sideAccelCPilRInitTyp_ "RCM2_a425_sideAccelCPilRInitTyp_s";
BA_ "SystemSignalLongSymbol" SG_ 1249 RCM2_a433_presFrntLDoorCrssCoup_ "RCM2_a433_presFrntLDoorCrssCoup_s";
BA_ "SystemSignalLongSymbol" SG_ 1249 RCM2_a443_presFrntRDoorCrssCoup_ "RCM2_a443_presFrntRDoorCrssCoup_s";
BA_ "SystemSignalLongSymbol" SG_ 1249 RCM2_a473_upFrntPedProLCrssCoup_ "RCM2_a473_upFrntPedProLCrssCoup_s";
BA_ "SystemSignalLongSymbol" SG_ 1249 RCM2_a483_upFrntPedProRCrssCoup_ "RCM2_a483_upFrntPedProRCrssCoup_s";
BA_ "SystemSignalLongSymbol" SG_ 1249 RCM2_a493_presRearLDoorCrssCoup_ "RCM2_a493_presRearLDoorCrssCoup_s";
BA_ "SystemSignalLongSymbol" SG_ 1249 RCM2_a503_presRearRDoorCrssCoup_ "RCM2_a503_presRearRDoorCrssCoup_s";
BA_ "SystemSignalLongSymbol" SG_ 1249 RCM2_a509_sideAccelDPilLSht2Gnd_ "RCM2_a509_sideAccelDPilLSht2Gnd_s";
BA_ "SystemSignalLongSymbol" SG_ 1249 RCM2_a510_sideAccelDPilLSht2Bat_ "RCM2_a510_sideAccelDPilLSht2Bat_s";
BA_ "SystemSignalLongSymbol" SG_ 1249 RCM2_a512_sideAccelDPilLCrssCoup "RCM2_a512_sideAccelDPilLCrssCoup_s";
BA_ "SystemSignalLongSymbol" SG_ 1249 RCM2_a513_sideAccelDPilLCommErr_ "RCM2_a513_sideAccelDPilLCommErr_s";
BA_ "SystemSignalLongSymbol" SG_ 1249 RCM2_a514_sideAccelDPilLInitTyp_ "RCM2_a514_sideAccelDPilLInitTyp_s";
BA_ "SystemSignalLongSymbol" SG_ 1249 RCM2_a518_sideAccelDPilRSht2Gnd_ "RCM2_a518_sideAccelDPilRSht2Gnd_s";
BA_ "SystemSignalLongSymbol" SG_ 1249 RCM2_a519_sideAccelDPilRSht2Bat_ "RCM2_a519_sideAccelDPilRSht2Bat_s";
BA_ "SystemSignalLongSymbol" SG_ 1249 RCM2_a521_sideAccelDPilRCrssCoup "RCM2_a521_sideAccelDPilRCrssCoup_s";
BA_ "SystemSignalLongSymbol" SG_ 1249 RCM2_a522_sideAccelDPilRCommErr_ "RCM2_a522_sideAccelDPilRCommErr_s";
BA_ "SystemSignalLongSymbol" SG_ 1249 RCM2_a523_sideAccelDPilRInitTyp_ "RCM2_a523_sideAccelDPilRInitTyp_s";
BA_ "SystemSignalLongSymbol" SG_ 1249 RCM2_a554_bucklHallLeftCrssCoup_ "RCM2_a554_bucklHallLeftCrssCoup_s";
BA_ "SystemSignalLongSymbol" SG_ 1249 RCM2_a556_bucklHallRightSht2Gnd_ "RCM2_a556_bucklHallRightSht2Gnd_s";
BA_ "SystemSignalLongSymbol" SG_ 1249 RCM2_a557_bucklHallRightSht2Bat_ "RCM2_a557_bucklHallRightSht2Bat_s";
BA_ "SystemSignalLongSymbol" SG_ 1249 RCM2_a560_bucklHallRightCrssCoup "RCM2_a560_bucklHallRightCrssCoup_s";
BA_ "SystemSignalLongSymbol" SG_ 1249 RCM2_a565_seaTrkPosLeftUndefined "RCM2_a565_seaTrkPosLeftUndefined_s";
BA_ "SystemSignalLongSymbol" SG_ 1249 RCM2_a566_seaTrkPosLeftCrssCoup_ "RCM2_a566_seaTrkPosLeftCrssCoup_s";
BA_ "SystemSignalLongSymbol" SG_ 1249 RCM2_a587_sbrRearNetworkSht2Gnd_ "RCM2_a587_sbrRearNetworkSht2Gnd_s";
BA_ "SystemSignalLongSymbol" SG_ 1249 RCM2_a588_sbrRearNetworkSht2Bat_ "RCM2_a588_sbrRearNetworkSht2Bat_s";
BA_ "SystemSignalLongSymbol" SG_ 1249 RCM2_a591_sbrRearNetworkCrssCoup "RCM2_a591_sbrRearNetworkCrssCoup_s";
BA_ "SystemSignalLongSymbol" SG_ 1249 RCM2_a593_driveOrientationSht2Gn "RCM2_a593_driveOrientationSht2Gnd_s";
BA_ "SystemSignalLongSymbol" SG_ 1249 RCM2_a594_driveOrientationSht2Ba "RCM2_a594_driveOrientationSht2Bat_s";
BA_ "SystemSignalLongSymbol" SG_ 1249 RCM2_a596_driveOrientationUndefi "RCM2_a596_driveOrientationUndefined_s";
BA_ "SystemSignalLongSymbol" SG_ 1249 RCM2_a597_driveOrientationCrssCo "RCM2_a597_driveOrientationCrssCoup_s";
BA_ "SystemSignalLongSymbol" SG_ 1249 RCM2_a598_driveOrientationConfig "RCM2_a598_driveOrientationConfig_s";
BA_ "SystemSignalLongSymbol" SG_ 1249 RCM2_a600_comCANinternalTimeout_ "RCM2_a600_comCANinternalTimeout_s";
BA_ "SystemSignalLongSymbol" SG_ 1249 RCM2_a620_comInvalidVehicleSpeed "RCM2_a620_comInvalidVehicleSpeed_s";
BA_ "SystemSignalLongSymbol" SG_ 1249 RCM2_a804_configDataInconsistent "RCM2_a804_configDataInconsistent_s";
BA_ "SystemSignalLongSymbol" SG_ 1249 RCM2_a808_configDriveNotLearned_ "RCM2_a808_configDriveNotLearned_s";
BA_ "SystemSignalLongSymbol" SG_ 1249 RCM2_a815_upFrntPedProMLSht2Gnd_ "RCM2_a815_upFrntPedProMLSht2Gnd_s";
BA_ "SystemSignalLongSymbol" SG_ 1249 RCM2_a816_upFrntPedProMLSht2Bat_ "RCM2_a816_upFrntPedProMLSht2Bat_s";
BA_ "SystemSignalLongSymbol" SG_ 1249 RCM2_a818_upFrntPedProMLCrssCoup "RCM2_a818_upFrntPedProMLCrssCoup_s";
BA_ "SystemSignalLongSymbol" SG_ 1249 RCM2_a819_upFrntPedProMLCommErr_ "RCM2_a819_upFrntPedProMLCommErr_s";
BA_ "SystemSignalLongSymbol" SG_ 1249 RCM2_a824_upFrntPedProMRSht2Gnd_ "RCM2_a824_upFrntPedProMRSht2Gnd_s";
BA_ "SystemSignalLongSymbol" SG_ 1249 RCM2_a825_upFrntPedProMRSht2Bat_ "RCM2_a825_upFrntPedProMRSht2Bat_s";
BA_ "SystemSignalLongSymbol" SG_ 1249 RCM2_a827_upFrntPedProMRCrssCoup "RCM2_a827_upFrntPedProMRCrssCoup_s";
BA_ "SystemSignalLongSymbol" SG_ 1249 RCM2_a828_upFrntPedProMRCommErr_ "RCM2_a828_upFrntPedProMRCommErr_s";
BA_ "SystemSignalLongSymbol" SG_ 1249 RCM2_a843_preten2ndRowCCrssCoup_ "RCM2_a843_preten2ndRowCCrssCoup_s";
BA_ "SystemSignalLongSymbol" SG_ 1249 RCM2_a853_ConfigParametersIncons "RCM2_a853_ConfigParametersInconsistent_s";
BA_ "SystemSignalLongSymbol" SG_ 1249 RCM2_a854_ConfigParametersNotLea "RCM2_a854_ConfigParametersNotLearned_s";
BA_ "SystemSignalLongSymbol" SG_ 1249 RCM2_a861_typeApprovalStringNotL "RCM2_a861_typeApprovalStringNotLearned_s";
VAL_ 2020 PM_infoIndex 255 "END" 21 "DI_BUILD_DATA" 20 "UDS_PROTOCOL_BOOTCRC" 19 "VERSION_DEPRECATED" 18 "BOOTLOADER_GITHASH" 17 "APP_GITHASH" 16 "SUBCOMPONENT" 15 "BOOTLOADER_CRC" 14 "BOOTLOADER_SVN" 13 "APP_CRC" 11 "PCBAID_ASSYID_USAGEID" 10 "BUILD_HWID_COMPONENTID" 9 "DEPRECATED_9" 8 "DEPRECATED_8" 7 "DEPRECATED_7" 6 "DEPRECATED_6" 5 "DEPRECATED_5" 4 "DEPRECATED_4" 3 "DEPRECATED_3" 2 "DEPRECATED_2" 1 "DEPRECATED_1" 0 "DEPRECATED_0" ;
VAL_ 2020 PM_buildType 4 "INFO_MFG_BUILD" 3 "INFO_TRACEABLE_CI_BUILD" 2 "INFO_LOCAL_BUILD" 1 "INFO_PLATFORM_BUILD" 0 "INFO_UNKNOWN_BUILD" ;
VAL_ 2020 PM_hardwareId 252 "CONFIGURABLE_HWID_PLACEHOLDER" ;
VAL_ 463 PM_torqueCheckState 4 "CANNOT_POLICE_AT_ALL" 3 "CANNOT_POLICE_MEASUREMENT" 2 "CANNOT_POLICE_COMMAND" 1 "POLICING" 0 "START" ;
VAL_ 463 PM_limpRequest 2 "SYSTEM" 1 "UNIT" 0 "OK" ;
VAL_ 463 PM_torqueCommand -4096 "SNA" ;
VAL_ 463 PM_torqueState 2 "INHIBITED" 1 "DISALLOWED" 0 "ALLOWED" ;
VAL_ 463 PM_hvilSystemStatus 3 "SNA" 2 "CLOSED" 1 "OPEN" 0 "DISABLED" ;
VAL_ 463 PM_sysElecPower -1024 "SNA" ;
VAL_ 2038 PM_vdcDebugSelector 32 "Mux32" 31 "Mux31" 30 "Mux30" 29 "Mux29" 28 "Mux28" 27 "Mux27" 26 "Mux26" 25 "Mux25" 24 "Mux24" 23 "Mux23" 22 "Mux22" 21 "Mux21" 20 "Mux20" 19 "Mux19" 18 "Mux18" 17 "Mux17" 16 "Mux16" 15 "Mux15" 14 "Mux14" 13 "Mux13" 12 "Mux12" 11 "Mux11" 10 "Mux10" 9 "Mux9" 8 "Mux8" 7 "Mux7" 6 "Mux6" 5 "Mux5" 4 "Mux4" 3 "Mux3" 2 "Mux2" 1 "Mux1" 0 "Mux0" ;
VAL_ 519 PTC_leftPowerDerating 3 "OVERTEMPERATURE_CORE" 2 "OVERTEMPERATURE_IGBT" 1 "OVERTEMPERATURE_PCB" 0 "NOT_DERATED" ;
VAL_ 519 PTC_rightPowerDerating 3 "OVERTEMPERATURE_CORE" 2 "OVERTEMPERATURE_IGBT" 1 "OVERTEMPERATURE_PCB" 0 "NOT_DERATED" ;
VAL_ 519 PTC_ocpEvent 2 "OCP_EVENT_RIGHT_SIDE" 1 "OCP_EVENT_LEFT_SIDE" 0 "NO_OCP_EVENT" ;
VAL_ 519 PTC_tliSource 4 "HV_OVER_VOLTAGE" 3 "OCP" 2 "12_VOLTS" 1 "IGBT_DRIVER" 0 "NO_ERROR" ;
VAL_ 837 PTC_infoIndex 255 "END" 31 "SUBCOMPONENT_GITHASH" 30 "PACKAGE_SN_8_14" 29 "PACKAGE_SN_1_7" 27 "PACKAGE_PN_15_20" 26 "PACKAGE_PN_8_14" 25 "PACKAGE_PN_1_7" 23 "SUBCOMPONENT2" 22 "VARIANTCRC" 20 "UDS_PROTOCOL_BOOTCRC" 19 "VERSION_DEPRECATED" 18 "BOOTLOADER_GITHASH" 17 "APP_GITHASH" 16 "SUBCOMPONENT" 15 "BOOTLOADER_CRC" 14 "BOOTLOADER_SVN" 13 "APP_CRC" 11 "PCBAID_ASSYID_USAGEID" 10 "BUILD_HWID_COMPONENTID" 9 "DEPRECATED_9" 8 "DEPRECATED_8" 7 "DEPRECATED_7" 6 "DEPRECATED_6" 5 "DEPRECATED_5" 4 "DEPRECATED_4" 3 "DEPRECATED_3" 2 "DEPRECATED_2" 1 "DEPRECATED_1" 0 "DEPRECATED_0" ;
VAL_ 837 PTC_infoBuildType 4 "INFO_MFG_BUILD" 3 "INFO_TRACEABLE_CI_BUILD" 2 "INFO_LOCAL_BUILD" 1 "INFO_PLATFORM_BUILD" 0 "INFO_UNKNOWN_BUILD" ;
VAL_ 837 PTC_infoAssemblyId 255 "ASSEMBLY_SNA" 1 "ASSEMBLY1" ;
VAL_ 1365 RADC_alertID 55 "a055_blockageInfo_Frame_2" 54 "a054_blockageInfo_Frame_1" 53 "a053_emError" 52 "a052_mismatcRadPos" 51 "a051_mismatchEPASType" 50 "a050_mismatchCountry" 49 "a049_mismatchFourWheelDrive" 48 "a048_mismatchAirSuspension" 47 "a047_mismatchChassisType" 46 "a046_wheelSpeedsErr" 45 "a045_vehicleStateErr" 44 "a044_steeringWheelAngleErr" 43 "a043_inertialSignalsErr" 42 "a042_carConfigErr" 41 "a041_vinErr" 40 "a040_wheelSpeedsMIA" 39 "a039_vehicleStateMIA" 38 "a038_steeringWheelAngleMIA" 37 "a037_inertialSignalsMIA" 36 "a036_carConfigMIA" 35 "a035_vinMIA" 34 "a034_vehDynamicsError" 33 "a033_sensorNeverAligned" 32 "a032_sensorBlocked" 31 "a031_sensorMisaligned" 30 "a030_rspError" 29 "a029_rhcError" 28 "a028_rfChipError" 27 "a027_nvmFailure" 26 "a026_underVoltage" 25 "a025_overVoltage" 24 "a024_underTempCrit" 23 "a023_underTemp" 22 "a022_tempImplausible" 21 "a021_overTempCrit" 20 "a020_overTemp" 19 "a019_internalSoftwareFault" 18 "a018_internalHardwareFault" 17 "a017_adcUnderVolt" 16 "a016_adcOverVolt" 15 "a015_fctSenInterference" 14 "a014_fctSelfTestNotDone" 13 "a013_ecuWdgError" 12 "a012_ecuSpiError" 11 "a011_ecuMcemError" 10 "a010_ecuIoHwAbError" 9 "a009_plantModeActive" 8 "a008_ecuHwSwInterlock" 7 "a007_ecuGptCheckError" 6 "a006_ecuFimError" 5 "a005_ecuEcuMError" 4 "a004_ecuCrcHwError" 3 "a003_ecuBistDisabled" 2 "a002_ecuAdcError" 1 "a001_can1BusOff" 0 "ALERT_DO_NOT_USE_ZERO" ;
VAL_ 1365 RADC_alertState 1 "SET" 0 "CLEARED" ;
VAL_ 1365 RADC_a002_ecuAdcErrType 1 "INVALID_CONV_MODE" 0 "LIMIT_RANGE" ;
VAL_ 1365 RADC_a008_interLockErrType 1 "SW_VERSION_MISMATCH" 0 "HW_SW_PROJECT_ID_INCOMPATIBLE" ;
VAL_ 1365 RADC_a011_ecuMcemErrType 10 "MCEM__ALARM_ISR" 9 "MCEM_E_CORRUPTED_HW_CONFIG" 8 "MCEM_E_FAULT" 7 "MCEM_E_FORBIDDEN_INVOCATION" 6 "MCEM_E_INIT_FAILED" 5 "MCEM_E_OPERATION_FAILED" 4 "MCU_E_CLOCK_FAILURE" 3 "MCU_E_MCME_PERIODIC_CHECK" 2 "MCU_E_MCPCU_PERIODIC_CHECK" 1 "MCU_E_MCRGM_PERIODIC_CHECK" 0 "MCU_E_QUARTZ_FAILURE" ;
VAL_ 1365 RADC_a013_ecuWdgErrType 3 "CORRUPT_CONFIG" 2 "DISABLE_REJECTED" 1 "INVALID_CALL" 0 "UNLOCKED" ;
VAL_ 1365 RADC_a016_adcOverVoltType 7 "5V_SMPS_OVER_VOLTAGE" 6 "4V5_LIN_VOLTAGECO_OVER_VOLTAGE" 5 "3V8_SMPS_OVER_VOLTAGE" 4 "3V3_LIN_ANALOG_OVER_VOLTAGE" 3 "3V3_LIN_DIGITAL_OVER_VOLTAGE" 2 "3V3_LIN_PA_OVER_VOLTAGE" 1 "3V3_LIN_VOLTAGECO_OVER_VOLTAGE" 0 "1V25_SMPS_OVER_VOLTAGE" ;
VAL_ 1365 RADC_a017_adcUnderVoltType 7 "5V_SMPS_UNDER_VOLTAGE" 6 "4V5_LIN_VOLTAGECO_UNDER_VOLTAGE" 5 "3V8_SMPS_UNDER_VOLTAGE" 4 "3V3_LIN_ANALOG_UNDER_VOLTAGE" 3 "3V3_LIN_DIGITAL_UNDER_VOLTAGE" 2 "3V3_LIN_PA_UNDER_VOLTAGE" 1 "3V3_LIN_VOLTAGECO_UNDER_VOLTAGE" 0 "1V25_SMPS_UNDER_VOLTAGE" ;
VAL_ 1365 RADC_a019_internalSWFaultType 110 "ADC_CALIBRATION" 109 "PROCESSOR_VERSION" 108 "FLASH_CYCLIC_CHECK" 107 "INTERNAL_VOLTAGE_FAILED" 106 "ATIC_RESET" 105 "LBIST_FAILED" 104 "MBIST_FAILED" 103 "STARTUP_ERROR" 102 "TEMP_CROSS_CHECK" 101 "ECC_INIT_FAILED" 100 "RADAR_CYCLE_VIOLATION" 99 "FLSP_INIT_FAILED" 98 "POWERUP_SEQ_TIMEOUT" 97 "IOHWAB_TIMEOUT" 96 "UBATT_OUT_OF_RANGE" 95 "EXCEPT_RESERVED_15" 94 "EXCEPT_RESERVED_14" 93 "EXCEPT_RESERVED_13" 92 "EXCEPT_TRAP" 91 "EXCEPT_CENTRAL" 90 "FCCU_HEALED_FAULT" 89 "FCCU_CHECKER_MISMATCH" 88 "PLL_STUCK" 87 "ECUM_REQUEST" 86 "SPI_ATIC_FAULT" 85 "SPI_MMIC_MISMATCH" 84 "SPI_MMIC_FAULT" 83 "ECC_OTHER_2BIT" 82 "ECC_CORE_ICACHE_2BIT" 81 "ECC_CORE_DCACHE_2BIT" 80 "ECC_CORE_IMEM_2BIT" 79 "ECC_CORE_DMEM_2BIT" 78 "ECC_EEPROM_2BIT" 77 "ECC_FLASH_2BIT" 76 "ECC_SRAM_2BIT" 75 "SMPU" 74 "IOHWAB" 73 "ECC_PATTERN_MISSING" 72 "WATCHDOG" 71 "WATCHDOG_INITIALIZATION" 70 "CLKMON_CALIBRATION" 69 "CLKMON_CONFIG_CHECK" 68 "CLKMON_INITIALIZATION" 67 "FCCU_FAULT_SIGNALED" 66 "FCCU_CORRUPTED_CONFIG" 65 "HW_SW_INCOMPATIBLE" 64 "SPE_CHECK" 63 "FPU_CHECK" 62 "ECC_SPT_2BIT" 61 "ECC_DMA_2BIT" 60 "ECC_HARDWARE_FAILURE" 59 "DRIVERINIT_FAILED" 58 "CORE2_STACK_OVERFLOW" 57 "CORE1_STACK_OVERFLOW" 56 "NVM_TIMEOUT" 55 "EXCEPT_ECC2BITERROR" 54 "EXCEPT_ECC1BITERROR" 53 "EXCEPT_DECREMENTER" 52 "EXCEPT_AP_UNAVAILABLE" 51 "EXCEPT_SYSTEM_CALL" 50 "E_FLOATINGPOINT_UNAVAIL" 49 "FCCU" 48 "INTENTIONAL_RESET" 47 "CYCLE_MON" 46 "TESTCASE_CONFIG" 45 "TESTCASE_ABORT" 44 "EXCEPT_CORE_FREEZE" 43 "INVALID_SAFESECTION" 42 "BUS_TEST" 41 "UNEXPECTED_RESET" 40 "ALU_CHECK" 39 "MISC_CHECK" 38 "APPL_CRC_CHECK" 37 "CONFIG_REGISTER_CHECK" 36 "CPU_REGISTER_CHECK" 35 "TPU_RAM_ADDRESS_BUS1" 34 "TPU_RAM_ADDRESS_BUS0" 33 "SRAM_ADDRESS_BUS1" 32 "SRAM_ADDRESS_BUS0" 31 "ECC_TIMEOUT" 30 "DCACHE_MARCHC" 29 "AD_CONVERTER" 28 "TASK_STACK" 27 "TASK_MON_LOGIC" 26 "SYSTEM_CYCLE_MON" 25 "EXCEPT_UNDEFINED" 24 "EXCEPT_ERROR_TPU_RAM" 23 "EXCEPT_ERROR_SRAM" 22 "EXCEPT_SHUTDOWN_OS" 21 "EXCEPT_EFP_ROUND" 20 "EXCEPT_EFP_DATA" 19 "EXCEPT_SPE_UNAVAIL" 18 "EXCEPT_INSTR_TLB_ERROR" 17 "EXCEPT_DATA_TLB_ERROR" 16 "EXCEPT_WATCHDOG_TIMER" 15 "EXCEPT_FIXED_INTER" 14 "EXCEPT_DEBUG" 13 "EXCEPT_PERFORMANCEMON" 12 "EXCEPT_PROGRAM" 11 "EXCEPT_ALIGN" 10 "EXCEPT_INSTRUCT_STORE" 9 "EXCEPT_DATA_STORE" 8 "EXCEPT_MACH_CHECK" 7 "EXCEPT_CRIT_INPUT" 6 "ROM_ECC_2BIT" 5 "RAM_ECC_2BIT" 4 "ROM_ECC_1BIT" 3 "RAM_ECC_1BIT" 2 "MCU_SUPPLY" 1 "TEMP_MON" 0 "NONE" ;
VAL_ 1365 RADC_a019_internalSWFaultCoreID 2 "2" 1 "1" 0 "0" ;
VAL_ 1365 RADC_a027_nvmFailureType 2 "INTEGRITY_FAILED" 1 "REQ_FAILED" 0 "RECORD_SIZE_MISSMATCH" ;
VAL_ 1365 RADC_a028_rfComRegCheckFail 4 "MON_RF_OVERTEMP" 3 "MON_RF_CHIP_TEMP_IMPLAUSIBLE" 2 "REG_CHECK_FAILED_LT" 1 "REG_CHECK_FAILED" 0 "REG_CHECK_CYCLE_FAILED" ;
VAL_ 1365 RADC_a029_rhcChirpMonErrType 2 "RG_LENGTH_ERROR_NS" 1 "RMSE_TOO_LARGE_NS" 0 "FREQ_ERROR_SPEC_TOO_LARGE_NS" ;
VAL_ 1365 RADC_a029_rhcRxLongTermErrType 6 "NOISE_POWER_TOO_HIGH_LT" 5 "SPURIOUS_PEAKS_TOO_HIGH_LT" 4 "SIGNAL_POWER_TOO_LOW_LT" 3 "TRANSFER_FUNCTION_ERR_LT" 2 "CHANNEL_VARIATION_ERR_LT" 1 "STC_FILTER_ERR_LT" 0 "NONLINEAR_ERR_LT" ;
VAL_ 1365 RADC_a029_rhcRxErrType 7 "RX_SPURIOUS_PEAKS_TOO_HIGH" 6 "LOAD_PULLING_TOO_HIGH_NS" 5 "RX_NOISE_POWER_TOO_HIGH" 4 "RX_SIGNAL_POWER_TOO_LOW" 3 "RX_TRANSFER_FUNCTION_ERR" 2 "RX_CHANNEL_VARIATION_ERR" 1 "RX_STC_FILTER_ERR" 0 "RX_NONLINEAR_ERR" ;
VAL_ 1365 RADC_a029_rhcVcoPowerErrType 1 "LOW" 0 "HIGH" ;
VAL_ 1365 RADC_a029_rhcSp1ErrType 0 "RHC_CTE_LUT_DUR_STUCK_ERR" ;
VAL_ 1365 RADC_a029_rhcFdcErrType 2 "LONG_TERM_ERROR_NS" 1 "RMSE_TOO_LARGE_NS" 0 "DRIFT_FREQ_TOO_LARGE_NS" ;
VAL_ 1365 RADC_a030_rspErrType 1 "LONG_TERM_ERROR" 0 "SHORT_TERM_ERROR" ;
VAL_ 1365 RADC_a032_blockageType 4 "FCTSEN_OBJ_NOT_MEASURED" 3 "FCTSEN_BLOCKAGE" 2 "FCTSEN_DEC_BLOCKAGE" 1 "FCTSEN_INC_BLOCKAGE" 0 "ALN_PATH_COMP_HIGH_NEAR" ;
VAL_ 1365 RADC_a032_block_SPMBlockageState 4 "GDB_UNKNOWN_DAMP" 3 "GDB_RDC_DAMP" 2 "GDB_FULL_DAMP" 1 "GDB_INC_DAMP" 0 "DB_NO_DAMP" ;
VAL_ 1365 RADC_a032_block_SPMSelfTestState 3 "ROADBEAM_TEST" 2 "STARTUP" 1 "ON" 0 "OFF" ;
VAL_ 1365 RADC_a041_vinErrType 5 "OVERRUN" 4 "INVALID_DATA" 3 "SEQUENCE" 2 "CHECKSUM" 1 "LENGTH" 0 "NONE" ;
VAL_ 1365 RADC_a042_carConfigErrType 5 "OVERRUN" 4 "INVALID_DATA" 3 "SEQUENCE" 2 "CHECKSUM" 1 "LENGTH" 0 "NONE" ;
VAL_ 1365 RADC_a043_inertialSignalsErrType 5 "OVERRUN" 4 "INVALID_DATA" 3 "SEQUENCE" 2 "CHECKSUM" 1 "LENGTH" 0 "NONE" ;
VAL_ 1365 RADC_a044_stwAngleErrType 5 "OVERRUN" 4 "INVALID_DATA" 3 "SEQUENCE" 2 "CHECKSUM" 1 "LENGTH" 0 "NONE" ;
VAL_ 1365 RADC_a045_vehicleStateErrType 5 "OVERRUN" 4 "INVALID_DATA" 3 "SEQUENCE" 2 "CHECKSUM" 1 "LENGTH" 0 "NONE" ;
VAL_ 1365 RADC_a046_wheelSpeedsErrType 5 "OVERRUN" 4 "INVALID_DATA" 3 "SEQUENCE" 2 "CHECKSUM" 1 "LENGTH" 0 "NONE" ;
VAL_ 1365 RADC_a047_chassisTypeExp 7 "SNA" 2 "MODEL_3_CHASSIS" 1 "MODEL_X_CHASSIS" 0 "MODEL_S_CHASSIS" ;
VAL_ 1365 RADC_a047_chassisTypeRx 7 "SNA" 2 "MODEL_3_CHASSIS" 1 "MODEL_X_CHASSIS" 0 "MODEL_S_CHASSIS" ;
VAL_ 1365 RADC_a048_airSuspensionExp 7 "SNA" 5 "TESLA_ADAPTIVE" 4 "TESLA_PLUS" 3 "TESLA_STANDARD" 2 "PLUS" 1 "STANDARD" 0 "NONE" ;
VAL_ 1365 RADC_a048_airSuspensionRx 7 "SNA" 5 "TESLA_ADAPTIVE" 4 "TESLA_PLUS" 3 "TESLA_STANDARD" 2 "PLUS" 1 "STANDARD" 0 "NONE" ;
VAL_ 1365 RADC_a049_fourWheelDriveExp 3 "SNA" 2 "UNUSED" 1 "4WD" 0 "2WD" ;
VAL_ 1365 RADC_a049_fourWheelDriveRx 3 "SNA" 2 "UNUSED" 1 "4WD" 0 "2WD" ;
VAL_ 1365 RADC_a051_epasTypeExp 7 "SNA" 4 "MANDO_VGR63_GEN3" 3 "MANDO_VGR66" 2 "MANDO_FGR64" 1 "BOSCH_L405" 0 "BOSCH_L538" ;
VAL_ 1365 RADC_a051_epasTypeRx 7 "SNA" 4 "MANDO_VGR63_GEN3" 3 "MANDO_VGR66" 2 "MANDO_FGR64" 1 "BOSCH_L405" 0 "BOSCH_L538" ;
VAL_ 1365 RADC_a052_radarPositionExp 7 "SNA" 3 "MODEL_3" 2 "MODELX" 1 "MODELS_2" 0 "MODELS" ;
VAL_ 1365 RADC_a052_radarPositionRx 7 "SNA" 3 "MODEL_3" 2 "MODELX" 1 "MODELS_2" 0 "MODELS" ;
VAL_ 1329 RADC_infoIndex 20 "Mux20" 19 "Mux19" 13 "Mux13" 11 "Mux11" 10 "Mux10" ;
VAL_ 1329 RADC_infoBuildType 4 "INFO_MFG_BUILD" 3 "INFO_TRACEABLE_CI_BUILD" 2 "INFO_LOCAL_BUILD" 1 "INFO_PLATFORM_BUILD" 0 "INFO_UNKNOWN_BUILD" ;
VAL_ 1249 RCM2_alertID 879 "a879_headAB3rdRowLConfig" 878 "a878_headAB3rdRowLCrossC" 877 "a877_headAB3rdRowLShort" 876 "a876_headAB3rdRowLOpen" 875 "a875_headAB3rdRowLSht2Bat" 874 "a874_headAB3rdRowLSht2Gnd" 873 "a873_headAB3rdRowRConfig" 872 "a872_headAB3rdRowRCrossC" 871 "a871_headAB3rdRowRShort" 870 "a870_headAB3rdRowROpen" 869 "a869_headAB3rdRowRSht2Bat" 868 "a868_headAB3rdRowRSht2Gnd" 866 "a866_comDASstatusMIA" 865 "a865_comVCLVBMSstatusHighMIA" 864 "a864_comGTWepochTimeMIA" 863 "a863_comVCFRONTalertMatrixMIA" 862 "a862_comPCSalertMatrixMIA" 861 "a861_typeApprovalStringNotLearned" 860 "a860_comVCxLVPowerStateCntr" 859 "a859_comVCxLVPowerStateChkSm" 858 "a858_comVCxLVPowerStateMIA" 857 "a857_comVCLEFT2rCBuckle" 854 "a854_ConfigParametersNotLearned" 853 "a853_ConfigParametersInconsistent" 852 "a852_autarkyEvent" 851 "a851_internalFaultTemp" 850 "a850_comVCFRONTlightingMIA" 849 "a849_comIBSTparty1MIA" 848 "a848_comDIlocStatMIA" 847 "a847_comDASctrlMIA" 846 "a846_comSCCMstrAnglSnsMIA" 845 "a845_comUIchassisControlMIA" 844 "a844_preten2ndRowCConfig" 843 "a843_preten2ndRowCCrssCoup" 842 "a842_preten2ndRowCShort" 841 "a841_preten2ndRowCOpen" 840 "a840_preten2ndRowCSht2Bat" 839 "a839_preten2ndRowCSht2Gnd" 838 "a838_pretenShldCConfig" 837 "a837_pretenShldCCrossC" 836 "a836_pretenShldCShort" 835 "a835_pretenShldCOpen" 834 "a834_pretenShldCSht2Bat" 833 "a833_pretenShldCSht2Gnd" 832 "a832_upFrntPedProMRSigMon" 831 "a831_upFrntPedProMRDefect" 830 "a830_upFrntPedProMRConfig" 829 "a829_upFrntPedProMRIntTyp" 828 "a828_upFrntPedProMRCommErr" 827 "a827_upFrntPedProMRCrssCoup" 826 "a826_upFrntPedProMROpen" 825 "a825_upFrntPedProMRSht2Bat" 824 "a824_upFrntPedProMRSht2Gnd" 823 "a823_upFrntPedProMLSigMon" 822 "a822_upFrntPedProMLDefect" 821 "a821_upFrntPedProMLConfig" 820 "a820_upFrntPedProMLIntTyp" 819 "a819_upFrntPedProMLCommErr" 818 "a818_upFrntPedProMLCrssCoup" 817 "a817_upFrntPedProMLOpen" 816 "a816_upFrntPedProMLSht2Bat" 815 "a815_upFrntPedProMLSht2Gnd" 814 "a814_idfEnviMonitoringEvent" 813 "a813_idfEnviMonitoringError" 812 "a812_idfMisuseMonitoringErr" 811 "a811_comAxleSpeed" 810 "a810_bootUpActionFailure" 809 "a809_configDriveMismatch" 808 "a808_configDriveNotLearned" 807 "a807_configVINmismatch" 806 "a806_configVINnotLearned" 805 "a805_swVersionWrong" 804 "a804_configDataInconsistent" 803 "a803_algoVerifySensorID" 802 "a802_parameterTransferID" 801 "a801_parameterLayoutID" 800 "a800_crcFault" 799 "a799_internalFault" 750 "a750_linInternalTimeout" 701 "a701_comVCSECtpmsStatusMIA" 700 "a700_comVCRIGHT1rRSTPS" 699 "a699_comVCRIGHTocs" 698 "a698_comVCRIGHT2rRBuckle" 697 "a697_comVCRIGHT1rRBuckle" 696 "a696_comVCRIGHTrestCntr" 695 "a695_comVCRIGHTrestChkSm" 694 "a694_comVCRIGHTrestMIA" 693 "a693_comVCLEFT1rLSTPS" 692 "a692_comVCLEFT2rLBuckle" 691 "a691_comVCLEFT1rLBuckle" 690 "a690_comVCLEFTrestCntr" 689 "a689_comVCLEFTrestChkSm" 688 "a688_comVCLEFTrestMIA" 687 "a687_comDIchassControlCntr" 686 "a686_comDIchassControlChkSm" 685 "a685_comDIchassControlMIA" 684 "a684_comDIspeedCntr" 683 "a683_comDIspeedChkSm" 682 "a682_comDIspeedMIA" 681 "a681_comESPwheelSpeedsCntr" 680 "a680_comESPwheelSpeedsChkSm" 679 "a679_comESPwheelSpeedsMIA" 678 "a678_comEPAS3PsysCntr" 677 "a677_comEPAS3PsysChkSm" 676 "a676_comEPAS3PsysMIA" 675 "a675_comUIodoMIA" 674 "a674_comEPBRstatusCntr" 673 "a673_comEPBRstatusChkSm" 672 "a672_comEPBRstatusMIA" 671 "a671_comEPBLstatusCntr" 670 "a670_comEPBLstatusChkSm" 669 "a669_comEPBLstatusMIA" 668 "a668_comVCSEATDstps" 667 "a667_comVCSEATDOccpy" 666 "a666_comVCSEATDbuckle" 665 "a665_comVCSEATDrestCntr" 664 "a664_comVCSEATDrestChkSm" 663 "a663_comVCSEATDrestMIA" 662 "a662_comVCSEATPstps" 661 "a661_comVCSEATPocs" 660 "a660_comVCSEATPOccpy" 659 "a659_comVCSEATPbuckle" 658 "a658_comVCSEATPrestCntr" 657 "a657_comVCSEATPrestChkSm" 656 "a656_comVCSEATPrestMIA" 655 "a655_comGTWESP1Cntr" 654 "a654_comGTWESP1ChkSm" 653 "a653_comGTWESP1MIA" 652 "a652_ambientTempFaulted" 651 "a651_comDIstate2Cntr" 650 "a650_comDIstate2ChkSm" 649 "a649_comDIstate2MIA" 648 "a648_comDIstateCntr" 647 "a647_comDIstateChkSm" 646 "a646_comDIstateMIA" 645 "a645_comDASSafetyFrntCntr" 644 "a644_comDASSafetyFrntChkSm" 643 "a643_comDASSafetyFrntMIA" 642 "a642_comVINmessageMIA" 641 "a641_comGTWCarConfigMIA" 640 "a640_comTPMSStatusCMIA" 639 "a639_comGTWCarStateMIA" 638 "a638_comGTWodoMIA" 637 "a637_ocsUnknown" 636 "a636_ocsFaulted" 635 "a635_comOCS1PCntr" 634 "a634_comOCS1PChkSm" 633 "a633_comOCS1PMIA" 632 "a632_comGTWACSCntr" 631 "a631_comGTWACSChkSm" 630 "a630_comGTWACSMIA" 629 "a629_comEPBStatusCntr" 628 "a628_comEPBStatusChkSm" 627 "a627_comEPBStatusMIA" 626 "a626_comESPCCntr" 625 "a625_comESPCChkSm" 624 "a624_comESPCMIA" 623 "a623_comESPBCntr" 622 "a622_comESPBChkSm" 621 "a621_comESPBMIA" 620 "a620_comInvalidVehicleSpeed" 619 "a619_comESP145Cntr" 618 "a618_comESP145ChkSm" 617 "a617_comESP145MIA" 616 "a616_comESP135Cntr" 615 "a615_comESP135ChkSm" 614 "a614_comESP135MIA" 613 "a613_comDItorque2Cntr" 612 "a612_comDItorque2ChkSm" 611 "a611_comDItorque2MIA" 610 "a610_comDItorque1Cntr" 609 "a609_comDItorque1ChkSm" 608 "a608_comDItorque1MIA" 607 "a607_comStwAngStatCntr" 606 "a606_comStwAngStatChkSm" 605 "a605_comStwAngStatMIA" 604 "a604_comPARTYCANBusOff" 603 "a603_comPARTYCANSilent" 602 "a602_comChassisCANBusOff" 601 "a601_comChassisCANSilent" 600 "a600_comCANinternalTimeout" 598 "a598_driveOrientationConfig" 597 "a597_driveOrientationCrssCoup" 596 "a596_driveOrientationUndefined" 595 "a595_driveOrientationOpen" 594 "a594_driveOrientationSht2Bat" 593 "a593_driveOrientationSht2Gnd" 592 "a592_sbrRearNetworkConfig" 591 "a591_sbrRearNetworkCrssCoup" 590 "a590_sbrRearNetworkUndefined" 589 "a589_sbrRearNetworkOpen" 588 "a588_sbrRearNetworkSht2Bat" 587 "a587_sbrRearNetworkSht2Gnd" 573 "a573_occPROSConfig" 572 "a572_occPROSCrssCoup" 571 "a571_occPROSUndef" 570 "a570_occPROSOpen" 569 "a569_occPROSSht2Bat" 568 "a568_occPROSSht2Gnd" 567 "a567_seaTrkPosLeftConfig" 566 "a566_seaTrkPosLeftCrssCoup" 565 "a565_seaTrkPosLeftUndefined" 564 "a564_seaTrkPosLeftOpen" 563 "a563_seaTrkPosLeftShtBat" 562 "a562_seaTrkPosLeftSht2Gnd" 561 "a561_bucklHallRightConfig" 560 "a560_bucklHallRightCrssCoup" 559 "a559_bucklHallRightUndef" 558 "a558_bucklHallRightOpen" 557 "a557_bucklHallRightSht2Bat" 556 "a556_bucklHallRightSht2Gnd" 555 "a555_bucklHallLeftConfig" 554 "a554_bucklHallLeftCrssCoup" 553 "a553_bucklHallLeftUndef" 552 "a552_bucklHallLeftOpen" 551 "a551_bucklHallLeftSht2Bat" 550 "a550_bucklHallLeftSht2Gnd" 535 "a535_upFrntSnsrCSigMon" 534 "a534_upFrntSnsrCDefect" 533 "a533_upFrntSnsrCConfig" 532 "a532_upFrntSnsrCInitTyp" 531 "a531_upFrntSnsrCCommErr" 530 "a530_upFrntSnsrCCrssCoup" 529 "a529_upFrntSnsrCOpen" 528 "a528_upFrntSnsrCSht2Bat" 527 "a527_upFrntSnsrCSht2Gnd" 526 "a526_sideAccelDPilRSigMon" 525 "a525_sideAccelDPilRDefect" 524 "a524_sideAccelDPilRConfig" 523 "a523_sideAccelDPilRInitTyp" 522 "a522_sideAccelDPilRCommErr" 521 "a521_sideAccelDPilRCrssCoup" 520 "a520_sideAccelDPilROpen" 519 "a519_sideAccelDPilRSht2Bat" 518 "a518_sideAccelDPilRSht2Gnd" 517 "a517_sideAccelDPilLSigMon" 516 "a516_sideAccelDPilLDefect" 515 "a515_sideAccelDPilLConfig" 514 "a514_sideAccelDPilLInitTyp" 513 "a513_sideAccelDPilLCommErr" 512 "a512_sideAccelDPilLCrssCoup" 511 "a511_sideAccelDPilLOpen" 510 "a510_sideAccelDPilLSht2Bat" 509 "a509_sideAccelDPilLSht2Gnd" 508 "a508_presRearRDoorSigMon" 507 "a507_presRearRDoorDefect" 506 "a506_presRearRDoorConfig" 505 "a505_presRearRDoorInitTyp" 504 "a504_presRearRDoorCommErr" 503 "a503_presRearRDoorCrssCoup" 502 "a502_presRearRDoorOpen" 501 "a501_presRearRDoorSht2Bat" 500 "a500_presRearRDoorSht2Gnd" 498 "a498_presRearLDoorSigMon" 497 "a497_presRearLDoorDefect" 496 "a496_presRearLDoorConfig" 495 "a495_presRearLDoorInitTyp" 494 "a494_presRearLDoorCommErr" 493 "a493_presRearLDoorCrssCoup" 492 "a492_presRearLDoorOpen" 491 "a491_presRearLDoorSht2Bat" 490 "a490_presRearLDoorSht2Gnd" 488 "a488_upFrntPedProRSigMon" 487 "a487_upFrntPedProRDefect" 486 "a486_upFrntPedProRConfig" 485 "a485_upFrntPedProRIntTyp" 484 "a484_upFrntPedProRCommErr" 483 "a483_upFrntPedProRCrssCoup" 482 "a482_upFrntPedProROpen" 481 "a481_upFrntPedProRSht2Bat" 480 "a480_upFrntPedProRSht2Gnd" 478 "a478_upFrntPedProLSigMon" 477 "a477_upFrntPedProLDefect" 476 "a476_upFrntPedProLConfig" 475 "a475_upFrntPedProLIntTyp" 474 "a474_upFrntPedProLCommErr" 473 "a473_upFrntPedProLCrssCoup" 472 "a472_upFrntPedProLOpen" 471 "a471_upFrntPedProLSht2Bat" 470 "a470_upFrntPedProLSht2Gnd" 469 "a469_presPedProAbsolute" 468 "a468_presPedProRSigMon" 467 "a467_presPedProRDefect" 466 "a466_presPedProRConfig" 465 "a465_presPedProRInitTyp" 464 "a464_presPedProRCommErr" 463 "a463_presPedProRCrssCoup" 462 "a462_presPedProROpen" 461 "a461_presPedProRSht2Bat" 460 "a460_presPedProRSht2Gnd" 458 "a458_presPedProLSigMon" 457 "a457_presPedProLDefect" 456 "a456_presPedProLConfig" 455 "a455_presPedProLInitTyp" 454 "a454_presPedProLCommErr" 453 "a453_presPedProLCrssCoup" 452 "a452_presPedProLOpen" 451 "a451_presPedProLSht2Bat" 450 "a450_presPedProLSht2Gnd" 449 "a449_presDoorAbsolute2" 448 "a448_presFrntRDoorSigMon" 447 "a447_presFrntRDoorDefect" 446 "a446_presFrntRDoorConfig" 445 "a445_presFrntRDoorInitTyp" 444 "a444_presFrntRDoorCommErr" 443 "a443_presFrntRDoorCrssCoup" 442 "a442_presFrntRDoorOpen" 441 "a441_presFrntRDoorSht2Bat" 440 "a440_presFrntRDoorSht2Gnd" 439 "a439_presDoorAbsolute1" 438 "a438_presFrntLDoorSigMon" 437 "a437_presFrntLDoorDefect" 436 "a436_presFrntLDoorConfig" 435 "a435_presFrntLDoorInitTyp" 434 "a434_presFrntLDoorCommErr" 433 "a433_presFrntLDoorCrssCoup" 432 "a432_presFrntLDoorOpen" 431 "a431_presFrntLDoorSht2Bat" 430 "a430_presFrntLDoorSht2Gnd" 428 "a428_sideAccelCPilRSigMon" 427 "a427_sideAccelCPilRDefect" 426 "a426_sideAccelCPilRConfig" 425 "a425_sideAccelCPilRInitTyp" 424 "a424_sideAccelCPilRCommErr" 423 "a423_sideAccelCPilRCrssCoup" 422 "a422_sideAccelCPilROpen" 421 "a421_sideAccelCPilRSht2Bat" 420 "a420_sideAccelCPilRSht2Gnd" 418 "a418_sideAccelCPilLSigMon" 417 "a417_sideAccelCPilLDefect" 416 "a416_sideAccelCPilLConfig" 415 "a415_sideAccelCPilLInitTyp" 414 "a414_sideAccelCPilLCommErr" 413 "a413_sideAccelCPilLCrssCoup" 412 "a412_sideAccelCPilLOpen" 411 "a411_sideAccelCPilLSht2Bat" 410 "a410_sideAccelCPilLSht2Gnd" 408 "a408_sideAccelBPilRSigMon" 407 "a407_sideAccelBPilRDefect" 406 "a406_sideAccelBPilRConfig" 405 "a405_sideAccelBPilRInitTyp" 404 "a404_sideAccelBPilRCommErr" 403 "a403_sideAccelBPilRCrssCoup" 402 "a402_sideAccelBPilROpen" 401 "a401_sideAccelBPilRSht2Bat" 400 "a400_sideAccelBPilRSht2Gnd" 398 "a398_sideAccelBPilLSigMon" 397 "a397_sideAccelBPilLDefect" 396 "a396_sideAccelBPilLConfig" 395 "a395_sideAccelBPilLInitTyp" 394 "a394_sideAccelBPilLCommErr" 393 "a393_sideAccelBPilLCLosCoup" 392 "a392_sideAccelBPilLOpen" 391 "a391_sideAccelBPilLSht2Bat" 390 "a390_sideAccelBPilLSht2Gnd" 388 "a388_upFrntSnsrMidRSigMon" 387 "a387_upFrntSnsrMidRDefect" 386 "a386_upFrntSnsrMidRConfig" 385 "a385_upFrntSnsrMidRInitTyp" 384 "a384_upFrntSnsrMidRCommErr" 383 "a383_upFrntSnsrMidRCrssCoup" 382 "a382_upFrntSnsrMidROpen" 381 "a381_upFrntSnsrMidRSht2Bat" 380 "a380_upFrntSnsrMidRSht2Gnd" 378 "a378_upFrntSnsrMidLSigMon" 377 "a377_upFrntSnsrMidLDefect" 376 "a376_upFrntSnsrMidLConfig" 375 "a375_upFrntSnsrMidLInitTyp" 374 "a374_upFrntSnsrMidLCommErr" 373 "a373_upFrntSnsrMidLCrssCoup" 372 "a372_upFrntSnsrMidLOpen" 371 "a371_upFrntSnsrMidLSht2Bat" 370 "a370_upFrntSnsrMidLSht2Gnd" 368 "a368_upFrntSnsrRSigMon" 367 "a367_upFrntSnsrRDefect" 366 "a366_upFrntSnsrRConfig" 365 "a365_upFrntSnsrRInitTyp" 364 "a364_upFrntSnsrRCommErr" 363 "a363_upFrntSnsrRCrssCoup" 362 "a362_upFrntSnsrROpen" 361 "a361_upFrntSnsrRSht2Bat" 360 "a360_upFrntSnsrRSht2Gnd" 358 "a358_upFrntSnsrLSigMon" 357 "a357_upFrntSnsrLDefect" 356 "a356_upFrntSnsrLConfig" 355 "a355_upFrntSnsrLInitTyp" 354 "a354_upFrntSnsrLCommErr" 353 "a353_upFrntSnsrLCrssCoup" 352 "a352_upFrntSnsrLOpen" 351 "a351_upFrntSnsrLSht2Bat" 350 "a350_upFrntSnsrLSht2Gnd" 323 "a323_imuCalibrationNotDone" 322 "a322_imuCalibrationFailed" 321 "a321_imuAccZLgMonChlTemp" 320 "a320_imuAccZLgMonChlPerm" 319 "a319_imuAccYLgMonChlTemp" 318 "a318_imuAccYLgMonChlPerm" 317 "a317_imuAccXLgMonChlTemp" 316 "a316_imuAccXLgMonChlPerm" 315 "a315_imuRollR8ChnlMonTmpLF" 314 "a314_imuRollR8SnsrPermLF" 313 "a313_imuRollR8SnsrPermInit" 312 "a312_imuRollR8SnsrPermBG" 311 "a311_imuPitchR8ChnlMonTmpLF" 310 "a310_imuPitchR8SnsrPermLF" 309 "a309_imuPitchR8SnsrPermInit" 308 "a308_imuPitchR8SnsrPermBG" 307 "a307_imuYawR8ChnlMonTmpLF" 306 "a306_imuYawR8SnsrPermLF" 305 "a305_imuYawR8SnsrPermInit" 304 "a304_imuYawR8SnsrPermBG" 303 "a303_imuAccYHgMonChlTemp" 302 "a302_imuAccYHgMonChlPerm" 301 "a301_imuAccXHgMonChlTemp" 300 "a300_imuAccXHgMonChlPerm" 299 "a299_imuVertAOffCompNegSLDC" 298 "a298_imuVertAOffCompPosSLDC" 297 "a297_imuVertAOffCompNegFLDC" 296 "a296_imuVertAOffCompPosFLDC" 295 "a295_imuVertAOffCompNegLife" 294 "a294_imuVertAOffCompPosLife" 293 "a293_imuLatAcOffCompNegSLDC" 292 "a292_imuLatAcOffCompPosSLDC" 291 "a291_imuLatAcOffCompNegFLDC" 290 "a290_imuLatAcOffCompPosFLDC" 289 "a289_imuLatAcOffCompNegLife" 288 "a288_imuLatAcOffCompPosLife" 287 "a287_imuLongAOffCompNegSLDC" 286 "a286_imuLongAOffCompPosSLDC" 285 "a285_imuLongAOffCompNegFLDC" 284 "a284_imuLongAOffCompPosFLDC" 283 "a283_imuLongAOffCompNegLife" 282 "a282_imuLongAOffCompPosLife" 281 "a281_imuRollR8OffCompNegSLDC" 280 "a280_imuRollR8OffCompPosSLDC" 279 "a279_imuRollR8OffCompNegFLDC" 278 "a278_imuRollR8OffCompPosFLDC" 277 "a277_imuRollR8OffCompNegLife" 276 "a276_imuRollR8OffCompPosLife" 275 "a275_imuPtchR8OffCompNegSLDC" 274 "a274_imuPtchR8OffCompPosSLDC" 273 "a273_imuPtchR8OffCompNegFLDC" 272 "a272_imuPtchR8OffCompPosFLDC" 271 "a271_imuPtchR8OffCompNegLife" 270 "a270_imuPtchR8OffCompPosLife" 269 "a269_imuYawR8OffCompNegSLDC" 268 "a268_imuYawR8OffCompPosSLDC" 267 "a267_imuYawR8OffCompNegFLDC" 266 "a266_imuYawR8OffCompPosFLDC" 265 "a265_imuYawR8OffCompNegLife" 264 "a264_imuYawR8OffCompPosLife" 261 "a261_ens4Config" 260 "a260_ens4Sht2Gnd" 259 "a259_ens4Sht2Bat" 258 "a258_ens3Config" 257 "a257_ens3Sht2Gnd" 256 "a256_ens3Sht2Bat" 255 "a255_ens2Config" 254 "a254_ens2Sht2Gnd" 253 "a253_ens2Sht2Bat" 252 "a252_ens1Config" 251 "a251_ens1Sht2Gnd" 250 "a250_ens1Sht2Bat" 217 "a217_sideAB2ndRowRConfig" 216 "a216_sideAB2ndRowRCrssCoup" 215 "a215_sideAB2ndRowRShort" 214 "a214_sideAB2ndRowROpen" 213 "a213_sideAB2ndRowRSht2Bat" 212 "a212_sideAB2ndRowRSht2Gnd" 211 "a211_sideAB2ndRowLConfig" 210 "a210_sideAB2ndRowLCrssCoup" 209 "a209_sideAB2ndRowLShort" 208 "a208_sideAB2ndRowLOpen" 207 "a207_sideAB2ndRowLSht2Bat" 206 "a206_sideAB2ndRowLSht2Gnd" 205 "a205_driverFSABConfig" 204 "a204_driverFSABCrossCoup" 203 "a203_driverFSABShort" 202 "a202_driverFSABOpen" 201 "a201_driverFSABSht2Bat" 200 "a200_driverFSABSht2Gnd" 199 "a199_driverABAVConfig" 198 "a198_driverABAVCrossCoup" 197 "a197_driverABAVShort" 196 "a196_driverABAVOpen" 195 "a195_driverABAVSht2Bat" 194 "a194_driverABAVSht2Gnd" 193 "a193_hoodActuatorLConfig" 192 "a192_hoodActuatorLCrssCoup" 191 "a191_hoodActuatorLShort" 190 "a190_hoodActuatorLOpen" 189 "a189_hoodActuatorLSht2Bat" 188 "a188_hoodActuatorLSht2Gnd" 187 "a187_hoodActuatorRConfig" 186 "a186_hoodActuatorRCrssCoup" 185 "a185_hoodActuatorRShort" 184 "a184_hoodActuatorROpen" 183 "a183_hoodActuatorRSht2Bat" 182 "a182_hoodActuatorRSht2Gnd" 181 "a181_curAB2ndRowRConfig" 180 "a180_curAB2ndRowRCrssCoup" 179 "a179_curAB2ndRowRShort" 178 "a178_curAB2ndRowROpen" 177 "a177_curAB2ndRowRSht2Bat" 176 "a176_curAB2ndRowRSht2Gnd" 175 "a175_curAB2ndRowLConfig" 174 "a174_curAB2ndRowLCrssCoup" 173 "a173_curAB2ndRowLShort" 172 "a172_curAB2ndRowLOpen" 171 "a171_curAB2ndRowLSht2Bat" 170 "a170_curAB2ndRowLSht2Gnd" 169 "a169_preten2ndRowRCgf" 168 "a168_preten2ndRowRCrssCoup" 167 "a167_preten2ndRowRShort" 166 "a166_preten2ndRowROpen" 165 "a165_preten2ndRowRSht2Bat" 164 "a164_preten2ndRowRSht2Gnd" 163 "a163_preten2ndRowLCgf" 162 "a162_preten2ndRowLCrssCoup" 161 "a161_preten2ndRowLShort" 160 "a160_preten2ndRowLOpen" 159 "a159_preten2ndRowLSht2Bat" 158 "a158_preten2ndRowLSht2Gnd" 157 "a157_curABRightConfig" 156 "a156_curABRightCrssCoup" 155 "a155_curABRightShort" 154 "a154_curABRightOpen" 153 "a153_curABRightSht2Bat" 152 "a152_curABRightSht2Gnd" 151 "a151_curABLeftConfig" 150 "a150_curABLeftCrssCoup" 149 "a149_curABLeftShort" 148 "a148_curABLeftOpen" 147 "a147_curABLeftSht2Bat" 146 "a146_curABLeftSht2Gnd" 145 "a145_hvdPyroConfig" 144 "a144_hvdPyroCrssCoup" 143 "a143_hvdPyroShort" 142 "a142_hvdPyroOpen" 141 "a141_hvdPyroSht2Bat" 140 "a140_hvdPyroSht2Gnd" 139 "a139_sideAB1stRowRConfig" 138 "a138_sideAB1stRowRCrssCoup" 137 "a137_sideAB1stRowRShort" 136 "a136_sideAB1stRowROpen" 135 "a135_sideAB1stRowRSht2Bat" 134 "a134_sideAB1stRowRSht2Gnd" 133 "a133_sideAB1stRowLConfig" 132 "a132_sideAB1stRowLCrssCoup" 131 "a131_sideAB1stRowLShort" 130 "a130_sideAB1stRowLOpen" 129 "a129_sideAB1stRowLSht2Bat" 128 "a128_sideAB1stRowLSht2Gnd" 127 "a127_kneeABPassConfig" 126 "a126_kneeABPassCrssCoup" 125 "a125_kneeABPassShort" 124 "a124_kneeABPassOpen" 123 "a123_kneeABPassSht2Bat" 122 "a122_kneeABPassSht2Gnd" 121 "a121_kneeABDrvrConfig" 120 "a120_kneeABDrvrCrssCoup" 119 "a119_kneeABDrvrShort" 118 "a118_kneeABDrvrOpen" 117 "a117_kneeABDrvrSht2Bat" 116 "a116_kneeABDrvrSht2Gnd" 115 "a115_loadLimRightConfig" 114 "a114_loadLimRightCrssCoup" 113 "a113_loadLimRightShort" 112 "a112_loadLimRightOpen" 111 "a111_loadLimRightSht2Bat" 110 "a110_loadLimRightSht2Gnd" 109 "a109_loadLimLeftConfig" 108 "a108_loadLimLeftCrssCoup" 107 "a107_loadLimLeftShort" 106 "a106_loadLimLeftOpen" 105 "a105_loadLimLeftSht2Bat" 104 "a104_loadLimLeftSht2Gnd" 103 "a103_pretenLapRightConfig" 102 "a102_pretenLapRightCrssCoup" 101 "a101_pretenLapRightShort" 100 "a100_pretenLapRightOpen" 99 "a099_pretenLapRightSht2Bat" 98 "a098_pretenLapRightSht2Gnd" 97 "a097_pretenLapLeftConfig" 96 "a096_pretenLapLeftCrssCoup" 95 "a095_pretenLapLeftShort" 94 "a094_pretenLapLeftOpen" 93 "a093_pretenLapLeftSht2Bat" 92 "a092_pretenLapLeftSht2Gnd" 91 "a091_pretenShldRightConfig" 90 "a090_pretenShldRightCrssCou" 89 "a089_pretenShldRightShort" 88 "a088_pretenShldRightOpen" 87 "a087_pretenShldRightSht2Bat" 86 "a086_pretenShldRightSht2Gnd" 85 "a085_pretenShldLeftConfig" 84 "a084_pretenShldLeftCrossC" 83 "a083_pretenShldLeftShort" 82 "a082_pretenShldLeftOpen" 81 "a081_pretenShldLeftSht2Bat" 80 "a080_pretenShldLeftSht2Gnd" 79 "a079_passActiveVentConfig" 78 "a078_passActiveVentCrssCoup" 77 "a077_passActiveVentShort" 76 "a076_passActiveVentOpen" 75 "a075_passActiveVentSht2Bat" 74 "a074_passActiveVentSht2Gnd" 73 "a073_passABStg2Config" 72 "a072_passABStg2CrssCoup" 71 "a071_passABStg2Short" 70 "a070_passABStg2Open" 69 "a069_passABStg2Sht2Bat" 68 "a068_passABStg2Sht2Gnd" 67 "a067_passABStg1Config" 66 "a066_passABStg1CrssCoup" 65 "a065_passABStg1Short" 64 "a064_passABStg1Open" 63 "a063_passABStg1Sht2Bat" 62 "a062_passABStg1Sht2Gnd" 61 "a061_driverABStg2Config" 60 "a060_driverABStg2CrssCoup" 59 "a059_driverABStg2Short" 58 "a058_driverABStg2Open" 57 "a057_driverABStg2Sht2Bat" 56 "a056_driverABStg2Sht2Gnd" 55 "a055_driverABStg1Config" 54 "a054_driverABStg1CrssCoup" 53 "a053_driverABStg1Short" 52 "a052_driverABStg1Open" 51 "a051_driverABStg1Sht2Bat" 50 "a050_driverABStg1Sht2Gnd" 49 "a049_batteryVoltageTooLow" 48 "a048_batteryVoltageTooHigh" 47 "a047_batteryESRhigh" 17 "a017_ecuLogAvailable" 16 "a016_noDeployPedProCal" 15 "a015_noDeployCrashCal" 14 "a014_pedProNearDeploy" 13 "a013_placeholder2" 12 "a012_placeholder1" 11 "a011_placeholder0" 10 "a010_pedProEDRDataLocked" 9 "a009_edrDataAreaLocked" 8 "a008_factoryMode" 7 "a007_pedProCrashDetected" 6 "a006_supplierDiagEnabled" 5 "a005_abuseImmunityThrshold" 4 "a004_crashAlgoWakeup" 3 "a003_warningIndicator" 2 "a002_airbagsUnArmed" 1 "a001_nearDeploy" 0 "a000_crashDetected" ;
VAL_ 1249 RCM2_alertState 1 "SET" 0 "CLEARED" ;
VAL_ 1249 RCM2_eventArmStatus 1 "ARMED" 0 "UNARMED" ;
VAL_ 1249 RCM2_eventFactoryMode 1 "ENABLED" 0 "DISABLED" ;
VAL_ 1249 RCM2_eventDriveOrientation 1 "RIGHT_HAND_DRIVE" 0 "LEFT_HAND_DRIVE" ;
VAL_ 1249 RCM2_eventIDFsignal 1 "ACTIVE" 0 "NOT_ACTIVE" ;
VAL_ 1249 RCM2_eventFrontLeftSeatbelt 1 "LATCHED" 0 "UNLATCHED" ;
VAL_ 1249 RCM2_eventFrontRightSeatbelt 1 "LATCHED" 0 "UNLATCHED" ;
VAL_ 1249 RCM2_eventDriverBrakeApply 3 "Faulty_SNA" 2 "Driver_applying_brakes" 1 "Not_Applied" 0 "NotInit_orOff" ;
VAL_ 1249 RCM2_eventAccelPedalPos 255 "SNA" ;
